VERSION ""

NS_ :

BS_:

BU_: AHLM ASBS CADM CBC DIAGNOST DPDM DTCM ECM EHPS ESC ESL ESM ETM EVCU2 GPF IC IRCM LTM OCM ORC PTS RF_HUB SCCM SGW TBM TCM

BO_ 1005 VehCfgBu2: 8 RF_HUB
 SG_ VC_BU_PwrIvtrTyp : 2|2@1+ (1,0) [0|0] ""  CBC,SGW
 SG_ VC_BU_MaseratiMd : 6|2@1+ (1,0) [0|0] ""  CBC,SGW
 SG_ VC_BU_FULL_SPARE : 14|1@1+ (1,0) [0|0] ""  CBC,SGW
 SG_ VC_BU_ECO_Indicator : 24|1@1+ (1,0) [0|0] ""  CBC,SGW
 SG_ VC_BU_EngPowerDrvMd_Prsnt : 28|1@1+ (1,0) [0|0] ""  CBC,SGW
 SG_ VC_BU_MaxLdPressFtTr : 40|8@1+ (1,0) [0|126] "psi"  CBC,SGW
 SG_ VC_BU_LgtLdPressRrTr : 48|8@1+ (1,0) [0|126] "psi"  CBC,SGW
 SG_ VC_BU_LgtLdPressFtTr : 56|8@1+ (1,0) [0|126] "psi"  CBC,SGW
 SG_ VC_BU_SecPrkPrsnt : 29|1@1+ (1,0) [0|0] ""  CBC,SGW
 SG_ VC_BU_ShftInd_Prsnt : 30|2@1+ (1,0) [0|0] ""  CBC,SGW
 SG_ VC_BU_DRVMD_Prsnt : 25|1@1+ (1,0) [0|0] ""  CBC,SGW
 SG_ VC_BU_MemoryDRVMD_Prsnt : 26|1@1+ (1,0) [0|0] ""  CBC,SGW
 SG_ VC_BU_ESCDrvMd_Prsnt : 27|1@1+ (1,0) [0|0] ""  CBC,SGW
 SG_ VC_BU_MaxLdPressRrTr : 32|8@1+ (1,0) [0|126] "psi"  CBC,SGW
 SG_ VC_BU_OffRoad : 15|1@1+ (1,0) [0|0] ""  CBC,SGW
 SG_ VC_BU_PADS_Prsnt : 8|1@1+ (1,0) [0|0] ""  CBC,SGW
 SG_ VC_BU_RainSnsPrsnt : 9|1@1+ (1,0) [0|0] ""  CBC,SGW
 SG_ VC_BU_SKIM_PRSNT : 10|1@1+ (1,0) [0|0] ""  CBC,SGW
 SG_ VC_BU_AC_Prsnt : 11|1@1+ (1,0) [0|0] ""  CBC,SGW
 SG_ VC_BU_CRUISE_PRSNT : 12|1@1+ (1,0) [0|0] ""  CBC,SGW
 SG_ VC_BU_FG_PRSNT : 13|1@1+ (1,0) [0|0] ""  CBC,SGW
 SG_ VC_BU_ThatchamPrsnt : 4|1@1+ (1,0) [0|0] ""  CBC,SGW
 SG_ VC_BU_RunFlatTirePrsnt : 5|1@1+ (1,0) [0|0] ""  CBC,SGW
 SG_ VC_BU_VehCfg2_Stat : 0|2@1+ (1,0) [0|0] ""  CBC,SGW
 SG_ VC_BU_SpecialPKG_IC : 16|8@1+ (1,0) [0|0] ""  CBC,SGW

BO_ 1006 VehCfgBu3: 8 RF_HUB
 SG_ VC_BU_AutoParkPrsnt : 61|1@1+ (1,0) [0|0] ""  CBC,SGW
 SG_ VC_BU_PE_Prsnt : 62|1@1+ (1,0) [0|0] ""  CBC,SGW
 SG_ VC_BU_KG_Prsnt : 63|1@1+ (1,0) [0|0] ""  CBC,SGW
 SG_ VC_BU_Prem_TPM : 58|1@1+ (1,0) [0|0] ""  CBC,SGW
 SG_ VC_BU_PDDL_PRSNT : 59|1@1+ (1,0) [0|0] ""  CBC,SGW
 SG_ VC_BU_CMS : 55|1@1+ (1,0) [0|0] ""  CBC,SGW
 SG_ VC_BU_FCW : 56|1@1+ (1,0) [0|0] ""  CBC,SGW
 SG_ VC_BU_SecLkPrsnt : 52|1@1+ (1,0) [0|0] ""  CBC,SGW
 SG_ VC_BU_VEH_BRAND : 44|4@1+ (1,0) [0|0] ""  CBC,SGW
 SG_ VC_BU_CMP_DISP : 48|1@1+ (1,0) [0|0] ""  CBC,SGW
 SG_ VC_BU_IntEC_MIRR : 49|1@1+ (1,0) [0|0] ""  CBC,SGW
 SG_ VC_BU_ESCL_Prsnt : 50|1@1+ (1,0) [0|0] ""  CBC,SGW
 SG_ VC_BU_DrAlrPrsnt : 28|1@1+ (1,0) [0|0] ""  CBC,SGW
 SG_ VC_BU_DualFuelSens : 29|1@1+ (1,0) [0|0] ""  CBC,SGW
 SG_ VC_BU_SRT_PRSNT : 30|1@1+ (1,0) [0|0] ""  CBC,SGW
 SG_ VC_BU_DSBL_CLK_DISP : 31|1@1+ (1,0) [0|0] ""  CBC,SGW
 SG_ VC_BU_ChassisType : 32|7@1+ (1,0) [0|126] ""  CBC,SGW
 SG_ VC_BU_TEMP_DISP : 39|1@1+ (1,0) [0|0] ""  CBC,SGW
 SG_ VC_BU_RKE_PRSNT : 6|1@1+ (1,0) [0|0] ""  CBC,SGW
 SG_ VC_BU_SunShade_Present : 7|1@1+ (1,0) [0|0] ""  CBC,SGW
 SG_ VC_BU_PWR_LFT_GT : 3|1@1+ (1,0) [0|0] ""  CBC,SGW
 SG_ VC_BU_PWR_RT_SLDR : 4|1@1+ (1,0) [0|0] ""  CBC,SGW
 SG_ VC_BU_VehCfg3_Stat : 0|2@1+ (1,0) [0|0] ""  CBC,SGW
 SG_ VC_BU_POLICE : 2|1@1+ (1,0) [0|0] ""  CBC,SGW
 SG_ VC_BU_PWR_LT_SLDR : 5|1@1+ (1,0) [0|0] ""  CBC,SGW
 SG_ VC_BU_WHL_BASE : 12|2@1+ (1,0) [0|0] ""  CBC,SGW
 SG_ VC_BU_AUTO_HL : 27|1@1+ (1,0) [0|0] ""  CBC,SGW
 SG_ VC_BU_HVAC_Config : 40|4@1+ (1,0) [0|0] ""  CBC,SGW
 SG_ VC_BU_HID_HL : 51|1@1+ (1,0) [0|0] ""  CBC,SGW
 SG_ VC_BU_Liftgate_Trunk : 53|2@1+ (1,0) [0|0] ""  CBC,SGW
 SG_ VC_BU_Base_TPM : 57|1@1+ (1,0) [0|0] ""  CBC,SGW
 SG_ VC_BU_SPORT_PRSNT : 60|1@1+ (1,0) [0|0] ""  CBC,SGW
 SG_ VC_BU_TcaseTyp : 8|4@1+ (1,0) [0|0] ""  CBC,SGW
 SG_ VC_BU_FOBIKsafeENBL : 14|1@1+ (1,0) [0|0] ""  CBC,SGW
 SG_ VC_BU_ELV_PRSNT : 15|1@1+ (1,0) [0|0] ""  CBC,SGW
 SG_ VC_BU_FUEL_CAP : 16|8@1+ (1,36) [36|290] "liters"  CBC,SGW
 SG_ VC_BU_WIN_EXPR_FEAT : 24|2@1+ (1,0) [0|0] ""  CBC,SGW
 SG_ VC_BU_ADJ_PDL_PRSNT : 26|1@1+ (1,0) [0|0] ""  CBC,SGW

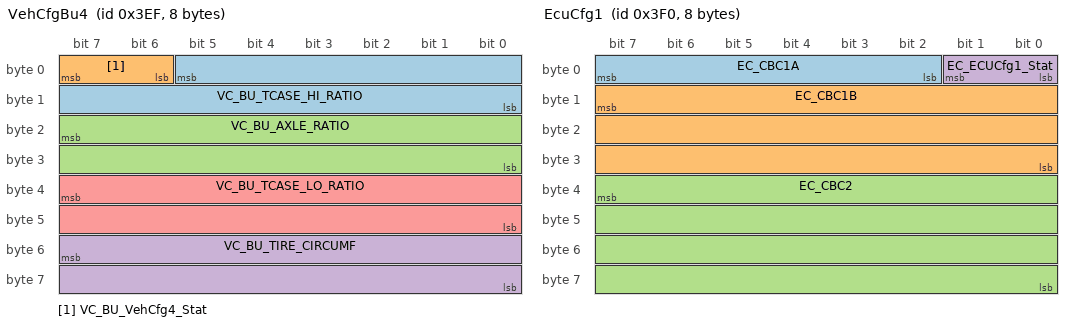
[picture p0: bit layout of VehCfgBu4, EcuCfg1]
BO_ 1007 VehCfgBu4: 8 RF_HUB
 SG_ VC_BU_TCASE_HI_RATIO : 5|14@0+ (0.001,0) [0|16.382] ""  CBC,SGW
 SG_ VC_BU_VehCfg4_Stat : 6|2@1+ (1,0) [0|0] ""  CBC,SGW
 SG_ VC_BU_AXLE_RATIO : 23|16@0+ (0.001,0) [0|65.534] ""  CBC,SGW
 SG_ VC_BU_TIRE_CIRCUMF : 55|16@0+ (1,0) [0|65534] "mm"  CBC,SGW
 SG_ VC_BU_TCASE_LO_RATIO : 39|16@0+ (0.001,0) [0|65.534] ""  CBC,SGW

BO_ 1008 EcuCfg1: 8 CBC
 SG_ EC_CBC1A : 2|6@1+ (1,0) [0|0] ""  RF_HUB,SGW
 SG_ EC_CBC1B : 15|24@0+ (1,0) [0|0] ""  RF_HUB,SGW
 SG_ EC_CBC2 : 39|32@0+ (1,0) [0|0] ""  RF_HUB,SGW
 SG_ EC_ECUCfg1_Stat : 0|2@1+ (1,0) [0|0] ""  RF_HUB,SGW

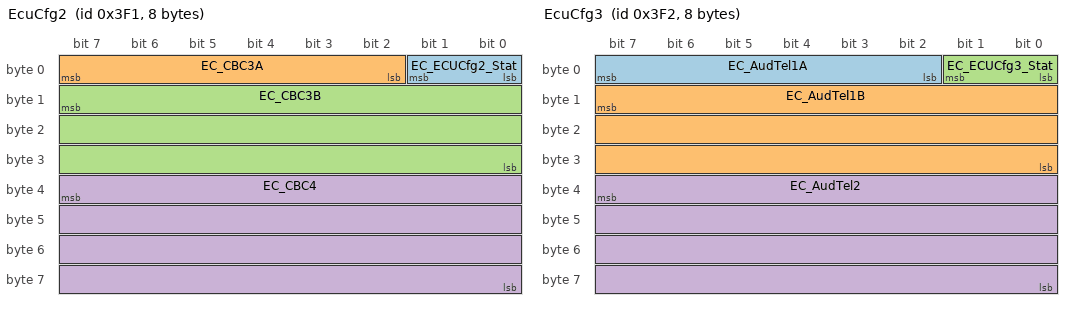
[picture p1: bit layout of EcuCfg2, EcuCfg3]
BO_ 1009 EcuCfg2: 8 CBC
 SG_ EC_ECUCfg2_Stat : 0|2@1+ (1,0) [0|0] ""  RF_HUB,SGW
 SG_ EC_CBC3A : 2|6@1+ (1,0) [0|0] ""  RF_HUB,SGW
 SG_ EC_CBC3B : 15|24@0+ (1,0) [0|0] ""  RF_HUB,SGW
 SG_ EC_CBC4 : 39|32@0+ (1,0) [0|0] ""  RF_HUB,SGW

BO_ 1010 EcuCfg3: 8 CBC
 SG_ EC_AudTel1A : 2|6@1+ (1,0) [0|0] ""  RF_HUB,SGW
 SG_ EC_AudTel1B : 15|24@0+ (1,0) [0|0] ""  RF_HUB,SGW
 SG_ EC_ECUCfg3_Stat : 0|2@1+ (1,0) [0|0] ""  RF_HUB,SGW
 SG_ EC_AudTel2 : 39|32@0+ (1,0) [0|0] ""  RF_HUB,SGW

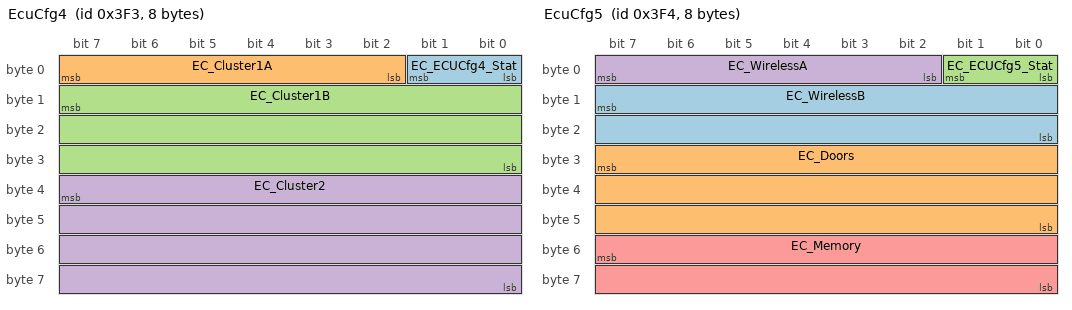
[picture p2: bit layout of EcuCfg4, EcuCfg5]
BO_ 1011 EcuCfg4: 8 CBC
 SG_ EC_ECUCfg4_Stat : 0|2@1+ (1,0) [0|0] ""  IC,RF_HUB,SGW
 SG_ EC_Cluster1A : 2|6@1+ (1,0) [0|0] ""  ETM,IC,RF_HUB,SGW
 SG_ EC_Cluster1B : 15|24@0+ (1,0) [0|0] ""  IC,RF_HUB,SGW
 SG_ EC_Cluster2 : 39|32@0+ (1,0) [0|0] ""  IC,RF_HUB,SGW

BO_ 1012 EcuCfg5: 8 CBC
 SG_ EC_WirelessB : 15|16@0+ (1,0) [0|0] ""  RF_HUB,SGW
 SG_ EC_Doors : 31|24@0+ (1,0) [0|0] ""  RF_HUB,SGW
 SG_ EC_ECUCfg5_Stat : 0|2@1+ (1,0) [0|0] ""  OCM,RF_HUB,SGW
 SG_ EC_WirelessA : 2|6@1+ (1,0) [0|0] ""  RF_HUB,SGW
 SG_ EC_Memory : 55|16@0+ (1,0) [0|0] ""  OCM,RF_HUB,SGW

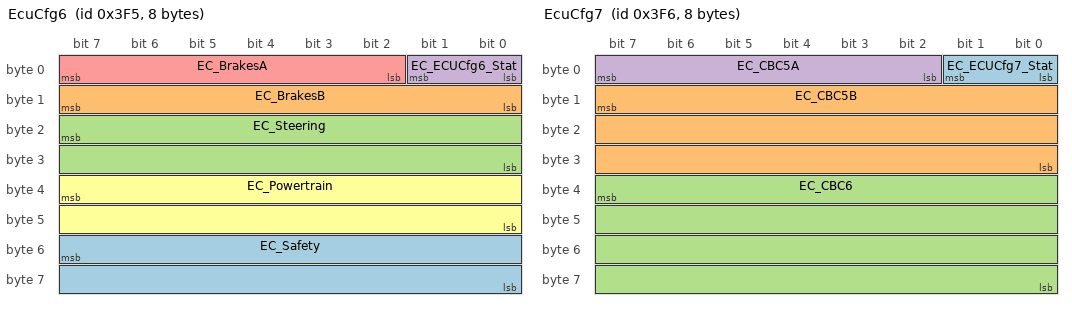
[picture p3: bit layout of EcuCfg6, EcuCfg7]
BO_ 1013 EcuCfg6: 8 CBC
 SG_ EC_Safety : 55|16@0+ (1,0) [0|0] ""  ORC,RF_HUB,SGW
 SG_ EC_BrakesB : 8|8@1+ (1,0) [0|0] ""  ESC,RF_HUB,SGW
 SG_ EC_Steering : 23|16@0+ (1,0) [0|0] ""  EHPS,ESC,RF_HUB,SGW
 SG_ EC_ECUCfg6_Stat : 0|2@1+ (1,0) [0|0] ""  ECM,EHPS,ESC,ORC,RF_HUB,SGW,TCM
 SG_ EC_BrakesA : 2|6@1+ (1,0) [0|0] ""  ESC,RF_HUB,SGW
 SG_ EC_Powertrain : 39|16@0+ (1,0) [0|0] ""  ECM,RF_HUB,SGW

BO_ 1014 EcuCfg7: 8 CBC
 SG_ EC_ECUCfg7_Stat : 0|2@1+ (1,0) [0|0] ""  RF_HUB,SGW
 SG_ EC_CBC5B : 15|24@0+ (1,0) [0|0] ""  RF_HUB,SGW
 SG_ EC_CBC6 : 39|32@0+ (1,0) [0|0] ""  RF_HUB,SGW
 SG_ EC_CBC5A : 2|6@1+ (1,0) [0|0] ""  RF_HUB,SGW

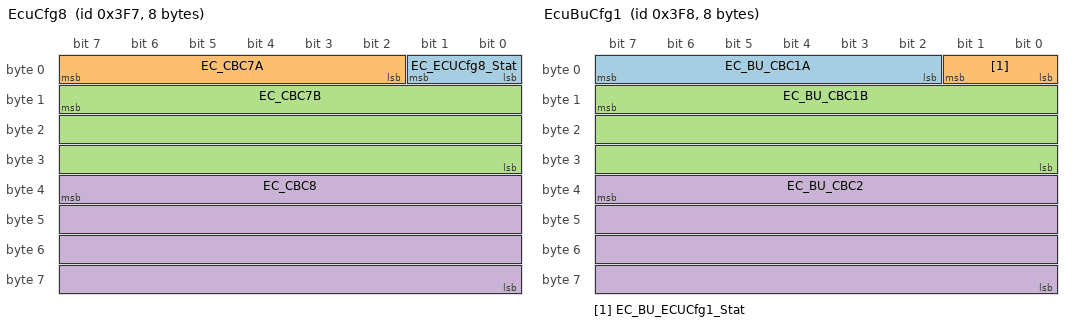
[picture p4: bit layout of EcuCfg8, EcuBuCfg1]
BO_ 1015 EcuCfg8: 8 CBC
 SG_ EC_ECUCfg8_Stat : 0|2@1+ (1,0) [0|0] ""  RF_HUB,SGW
 SG_ EC_CBC7A : 2|6@1+ (1,0) [0|0] ""  RF_HUB,SGW,TBM
 SG_ EC_CBC7B : 15|24@0+ (1,0) [0|0] ""  RF_HUB,SGW
 SG_ EC_CBC8 : 39|32@0+ (1,0) [0|0] ""  RF_HUB,SGW

BO_ 1016 EcuBuCfg1: 8 RF_HUB
 SG_ EC_BU_CBC1A : 2|6@1+ (1,0) [0|0] ""  CBC,SGW
 SG_ EC_BU_ECUCfg1_Stat : 0|2@1+ (1,0) [0|0] ""  CBC,SGW
 SG_ EC_BU_CBC1B : 15|24@0+ (1,0) [0|0] ""  CBC,SGW
 SG_ EC_BU_CBC2 : 39|32@0+ (1,0) [0|0] ""  CBC,SGW

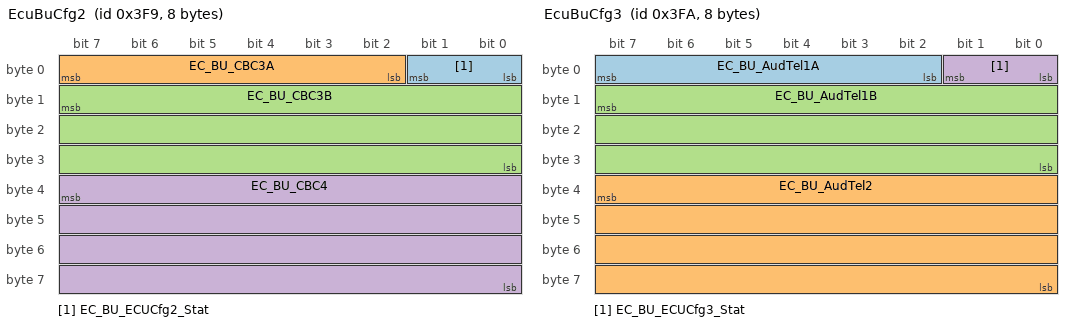
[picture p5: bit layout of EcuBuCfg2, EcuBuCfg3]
BO_ 1017 EcuBuCfg2: 8 RF_HUB
 SG_ EC_BU_ECUCfg2_Stat : 0|2@1+ (1,0) [0|0] ""  CBC,SGW
 SG_ EC_BU_CBC3A : 2|6@1+ (1,0) [0|0] ""  CBC,SGW
 SG_ EC_BU_CBC3B : 15|24@0+ (1,0) [0|0] ""  CBC,SGW
 SG_ EC_BU_CBC4 : 39|32@0+ (1,0) [0|0] ""  CBC,SGW

BO_ 1018 EcuBuCfg3: 8 RF_HUB
 SG_ EC_BU_AudTel1A : 2|6@1+ (1,0) [0|0] ""  CBC,SGW
 SG_ EC_BU_AudTel2 : 39|32@0+ (1,0) [0|0] ""  CBC,SGW
 SG_ EC_BU_AudTel1B : 15|24@0+ (1,0) [0|0] ""  CBC,SGW
 SG_ EC_BU_ECUCfg3_Stat : 0|2@1+ (1,0) [0|0] ""  CBC,SGW

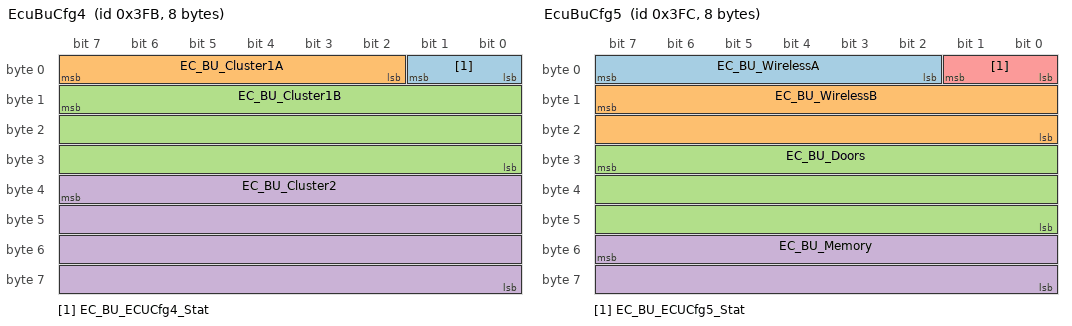
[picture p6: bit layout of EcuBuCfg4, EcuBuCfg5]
BO_ 1019 EcuBuCfg4: 8 RF_HUB
 SG_ EC_BU_ECUCfg4_Stat : 0|2@1+ (1,0) [0|0] ""  CBC,SGW
 SG_ EC_BU_Cluster1A : 2|6@1+ (1,0) [0|0] ""  CBC,SGW
 SG_ EC_BU_Cluster1B : 15|24@0+ (1,0) [0|0] ""  CBC,SGW
 SG_ EC_BU_Cluster2 : 39|32@0+ (1,0) [0|0] ""  CBC,SGW

BO_ 1020 EcuBuCfg5: 8 RF_HUB
 SG_ EC_BU_WirelessA : 2|6@1+ (1,0) [0|0] ""  CBC,SGW
 SG_ EC_BU_WirelessB : 15|16@0+ (1,0) [0|0] ""  CBC,SGW
 SG_ EC_BU_Doors : 31|24@0+ (1,0) [0|0] ""  CBC,SGW
 SG_ EC_BU_Memory : 55|16@0+ (1,0) [0|0] ""  CBC,SGW
 SG_ EC_BU_ECUCfg5_Stat : 0|2@1+ (1,0) [0|0] ""  CBC,SGW

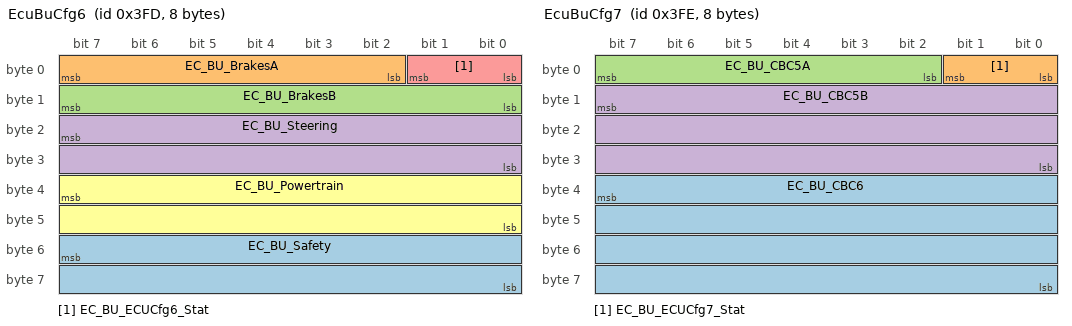
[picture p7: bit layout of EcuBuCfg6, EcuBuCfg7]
BO_ 1021 EcuBuCfg6: 8 RF_HUB
 SG_ EC_BU_Safety : 55|16@0+ (1,0) [0|0] ""  CBC,SGW
 SG_ EC_BU_BrakesA : 2|6@1+ (1,0) [0|0] ""  CBC,SGW
 SG_ EC_BU_BrakesB : 8|8@1+ (1,0) [0|0] ""  CBC,SGW
 SG_ EC_BU_Steering : 23|16@0+ (1,0) [0|0] ""  CBC,SGW
 SG_ EC_BU_ECUCfg6_Stat : 0|2@1+ (1,0) [0|0] ""  CBC,SGW
 SG_ EC_BU_Powertrain : 39|16@0+ (1,0) [0|0] ""  CBC,SGW

BO_ 1022 EcuBuCfg7: 8 RF_HUB
 SG_ EC_BU_CBC6 : 39|32@0+ (1,0) [0|0] ""  CBC,SGW
 SG_ EC_BU_ECUCfg7_Stat : 0|2@1+ (1,0) [0|0] ""  CBC,SGW
 SG_ EC_BU_CBC5A : 2|6@1+ (1,0) [0|0] ""  CBC,SGW
 SG_ EC_BU_CBC5B : 15|24@0+ (1,0) [0|0] ""  CBC,SGW

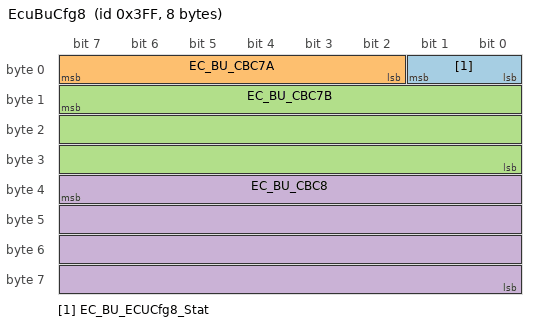
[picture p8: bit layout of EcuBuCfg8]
BO_ 1023 EcuBuCfg8: 8 RF_HUB
 SG_ EC_BU_ECUCfg8_Stat : 0|2@1+ (1,0) [0|0] ""  CBC,SGW
 SG_ EC_BU_CBC7A : 2|6@1+ (1,0) [0|0] ""  CBC,SGW
 SG_ EC_BU_CBC7B : 15|24@0+ (1,0) [0|0] ""  CBC,SGW
 SG_ EC_BU_CBC8 : 39|32@0+ (1,0) [0|0] ""  CBC,SGW

BO_ 1024 NM_RF_HUB: 8 RF_HUB
 SG_ NM_Mode : 0|8@1+ (1,0) [0|0] ""  CBC,EHPS,ESC,ESL,ESM,EVCU2,IC,RF_HUB,SCCM,SGW
 SG_ NM_Sleep_Ack : 22|1@1+ (1,0) [0|0] ""  CBC,EHPS,ESC,ESL,ESM,EVCU2,IC,RF_HUB,SCCM,SGW
 SG_ WakeupCnt m2 : 40|8@1+ (1,0) [0|254] ""  CBC,EHPS,ESC,ESL,ESM,EVCU2,IC,RF_HUB,SCCM,SGW
 SG_ Nw_Id : 56|8@1+ (1,0) [0|0] ""  CBC,EHPS,ESC,ESL,ESM,EVCU2,IC,RF_HUB,SCCM,SGW
 SG_ NM_Sleep_Ind : 23|1@1+ (1,0) [0|0] ""  CBC,EHPS,ESC,ESL,ESM,EVCU2,IC,RF_HUB,SCCM,SGW
 SG_ NM_Ud_Srv M : 24|8@1+ (1,0) [0|0] ""  CBC,EHPS,ESC,ESL,ESM,EVCU2,IC,RF_HUB,SCCM,SGW
 SG_ Awake_NwSt m15 : 32|1@1+ (1,0) [0|0] ""  CBC,EHPS,ESC,ESL,ESM,EVCU2,IC,RF_HUB,SCCM,SGW
 SG_ WakeupRsn_RF_HUB m2 : 32|8@1+ (1,0) [0|0] ""  CBC,EHPS,ESC,ESL,ESM,EVCU2,IC,RF_HUB,SCCM,SGW
 SG_ Awake_Diag_Actv m15 : 33|1@1+ (1,0) [0|0] ""  CBC,EHPS,ESC,ESL,ESM,EVCU2,IC,RF_HUB,SCCM,SGW
 SG_ NM_Successor : 8|8@1+ (1,0) [0|63] ""  CBC,EHPS,ESC,ESL,ESM,EVCU2,IC,RF_HUB,SCCM,SGW
 SG_ NM_Ud_Launch : 16|6@1+ (1,0) [0|0] ""  CBC,EHPS,ESC,ESL,ESM,EVCU2,IC,RF_HUB,SCCM,SGW

BO_ 1025 NM_CBC: 8 CBC
 SG_ NM_Ud_Srv M : 24|8@1+ (1,0) [0|0] ""  CBC,EHPS,ESC,ESL,ESM,EVCU2,IC,RF_HUB,SCCM,SGW
 SG_ WakeupRsn_CBC m2 : 32|8@1+ (1,0) [0|0] ""  CBC,EHPS,ESC,ESL,ESM,EVCU2,IC,RF_HUB,SCCM,SGW
 SG_ NM_Mode : 0|8@1+ (1,0) [0|0] ""  CBC,EHPS,ESC,ESL,ESM,EVCU2,IC,RF_HUB,SCCM,SGW
 SG_ NM_Successor : 8|8@1+ (1,0) [0|63] ""  CBC,EHPS,ESC,ESL,ESM,EVCU2,IC,RF_HUB,SCCM,SGW
 SG_ NM_Ud_Launch : 16|6@1+ (1,0) [0|0] ""  CBC,EHPS,ESC,ESL,ESM,EVCU2,IC,RF_HUB,SCCM,SGW
 SG_ NM_Sleep_Ack : 22|1@1+ (1,0) [0|0] ""  CBC,EHPS,ESC,ESL,ESM,EVCU2,IC,RF_HUB,SCCM,SGW
 SG_ NM_Sleep_Ind : 23|1@1+ (1,0) [0|0] ""  CBC,EHPS,ESC,ESL,ESM,EVCU2,IC,RF_HUB,SCCM,SGW
 SG_ Awake_NwSt m15 : 32|1@1+ (1,0) [0|0] ""  CBC,EHPS,ESC,ESL,ESM,EVCU2,IC,RF_HUB,SCCM,SGW
 SG_ Awake_Diag_Actv m15 : 33|1@1+ (1,0) [0|0] ""  CBC,EHPS,ESC,ESL,ESM,EVCU2,IC,RF_HUB,SCCM,SGW
 SG_ WakeupCnt m2 : 40|8@1+ (1,0) [0|254] ""  CBC,EHPS,ESC,ESL,ESM,EVCU2,IC,RF_HUB,SCCM,SGW
 SG_ Nw_Id : 56|8@1+ (1,0) [0|0] ""  CBC,EHPS,ESC,ESL,ESM,EVCU2,IC,RF_HUB,SCCM,SGW

BO_ 1026 NM_IC: 8 IC
 SG_ NM_Ud_Launch : 16|6@1+ (1,0) [0|0] ""  CBC,EHPS,ESC,ESL,ESM,EVCU2,IC,RF_HUB,SCCM,SGW
 SG_ WakeupRsn_IC m2 : 32|8@1+ (1,0) [0|0] ""  CBC,EHPS,ESC,ESL,ESM,EVCU2,IC,RF_HUB,SCCM,SGW
 SG_ NM_Sleep_Ack : 22|1@1+ (1,0) [0|0] ""  CBC,EHPS,ESC,ESL,ESM,EVCU2,IC,RF_HUB,SCCM,SGW
 SG_ NM_Sleep_Ind : 23|1@1+ (1,0) [0|0] ""  CBC,EHPS,ESC,ESL,ESM,EVCU2,IC,RF_HUB,SCCM,SGW
 SG_ NM_Ud_Srv M : 24|8@1+ (1,0) [0|0] ""  CBC,EHPS,ESC,ESL,ESM,EVCU2,IC,RF_HUB,SCCM,SGW
 SG_ Awake_NwSt m15 : 32|1@1+ (1,0) [0|0] ""  CBC,EHPS,ESC,ESL,ESM,EVCU2,IC,RF_HUB,SCCM,SGW
 SG_ Awake_Diag_Actv m15 : 33|1@1+ (1,0) [0|0] ""  CBC,EHPS,ESC,ESL,ESM,EVCU2,IC,RF_HUB,SCCM,SGW
 SG_ WakeupCnt m2 : 40|8@1+ (1,0) [0|254] ""  CBC,EHPS,ESC,ESL,ESM,EVCU2,IC,RF_HUB,SCCM,SGW
 SG_ Nw_Id : 56|8@1+ (1,0) [0|0] ""  CBC,EHPS,ESC,ESL,ESM,EVCU2,IC,RF_HUB,SCCM,SGW
 SG_ NM_Mode : 0|8@1+ (1,0) [0|0] ""  CBC,EHPS,ESC,ESL,ESM,EVCU2,IC,RF_HUB,SCCM,SGW
 SG_ NM_Successor : 8|8@1+ (1,0) [0|63] ""  CBC,EHPS,ESC,ESL,ESM,EVCU2,IC,RF_HUB,SCCM,SGW

BO_ 1031 NM_ESC: 8 ESC
 SG_ NM_Mode : 0|8@1+ (1,0) [0|0] ""  CBC,EHPS,ESC,ESL,ESM,EVCU2,IC,RF_HUB,SCCM,SGW
 SG_ NM_Sleep_Ind : 23|1@1+ (1,0) [0|0] ""  CBC,EHPS,ESC,ESL,ESM,EVCU2,IC,RF_HUB,SCCM,SGW
 SG_ Awake_NwSt m15 : 32|1@1+ (1,0) [0|0] ""  CBC,EHPS,ESC,ESL,ESM,EVCU2,IC,RF_HUB,SCCM,SGW
 SG_ WakeupCnt m2 : 40|8@1+ (1,0) [0|254] ""  CBC,EHPS,ESC,ESL,ESM,EVCU2,IC,RF_HUB,SCCM,SGW
 SG_ Nw_Id : 56|8@1+ (1,0) [0|0] ""  CBC,EHPS,ESC,ESL,ESM,EVCU2,IC,RF_HUB,SCCM,SGW
 SG_ NM_Ud_Srv M : 24|8@1+ (1,0) [0|0] ""  CBC,EHPS,ESC,ESL,ESM,EVCU2,IC,RF_HUB,SCCM,SGW
 SG_ WakeupRsn_ESC m2 : 32|8@1+ (1,0) [0|0] ""  CBC,EHPS,ESC,ESL,ESM,EVCU2,IC,RF_HUB,SCCM,SGW
 SG_ Awake_Diag_Actv m15 : 33|1@1+ (1,0) [0|0] ""  CBC,EHPS,ESC,ESL,ESM,EVCU2,IC,RF_HUB,SCCM,SGW
 SG_ Awake_Brake_Pedal_Pressed m15 : 34|1@1+ (1,0) [0|0] ""  CBC,EHPS,ESC,ESL,ESM,EVCU2,IC,RF_HUB,SCCM,SGW
 SG_ Awake_Vehicle_Speed m15 : 35|1@1+ (1,0) [0|0] ""  CBC,EHPS,ESC,ESL,ESM,EVCU2,IC,RF_HUB,SCCM,SGW
 SG_ Awake_EPB_Switch_Wakeup m15 : 36|1@1+ (1,0) [0|0] ""  CBC,EHPS,ESC,ESL,ESM,EVCU2,IC,RF_HUB,SCCM,SGW
 SG_ Awake_Hardwire_Ignition m15 : 37|1@1+ (1,0) [0|0] ""  CBC,EHPS,ESC,ESL,ESM,EVCU2,IC,RF_HUB,SCCM,SGW
 SG_ NM_Successor : 8|8@1+ (1,0) [0|63] ""  CBC,EHPS,ESC,ESL,ESM,EVCU2,IC,RF_HUB,SCCM,SGW
 SG_ NM_Ud_Launch : 16|6@1+ (1,0) [0|0] ""  CBC,EHPS,ESC,ESL,ESM,EVCU2,IC,RF_HUB,SCCM,SGW
 SG_ NM_Sleep_Ack : 22|1@1+ (1,0) [0|0] ""  CBC,EHPS,ESC,ESL,ESM,EVCU2,IC,RF_HUB,SCCM,SGW

BO_ 1032 NM_ESL: 8 ESL
 SG_ Awake_NwSt m15 : 32|1@1+ (1,0) [0|0] ""  CBC,EHPS,ESC,ESL,ESM,EVCU2,IC,RF_HUB,SCCM,SGW
 SG_ WakeupCnt m2 : 40|8@1+ (1,0) [0|254] ""  CBC,EHPS,ESC,ESL,ESM,EVCU2,IC,RF_HUB,SCCM,SGW
 SG_ Nw_Id : 56|8@1+ (1,0) [0|0] ""  CBC,EHPS,ESC,ESL,ESM,EVCU2,IC,RF_HUB,SCCM,SGW
 SG_ NM_Mode : 0|8@1+ (1,0) [0|0] ""  CBC,EHPS,ESC,ESL,ESM,EVCU2,IC,RF_HUB,SCCM,SGW
 SG_ NM_Successor : 8|8@1+ (1,0) [0|63] ""  CBC,EHPS,ESC,ESL,ESM,EVCU2,IC,RF_HUB,SCCM,SGW
 SG_ NM_Ud_Launch : 16|6@1+ (1,0) [0|0] ""  CBC,EHPS,ESC,ESL,ESM,EVCU2,IC,RF_HUB,SCCM,SGW
 SG_ NM_Sleep_Ack : 22|1@1+ (1,0) [0|0] ""  CBC,EHPS,ESC,ESL,ESM,EVCU2,IC,RF_HUB,SCCM,SGW
 SG_ NM_Sleep_Ind : 23|1@1+ (1,0) [0|0] ""  CBC,EHPS,ESC,ESL,ESM,EVCU2,IC,RF_HUB,SCCM,SGW
 SG_ NM_Ud_Srv M : 24|8@1+ (1,0) [0|0] ""  CBC,EHPS,ESC,ESL,ESM,EVCU2,IC,RF_HUB,SCCM,SGW
 SG_ WakeupRsn_ESL m2 : 32|8@1+ (1,0) [0|0] ""  CBC,EHPS,ESC,ESL,ESM,EVCU2,IC,RF_HUB,SCCM,SGW
 SG_ Awake_Diag_Actv m15 : 33|1@1+ (1,0) [0|0] ""  CBC,EHPS,ESC,ESL,ESM,EVCU2,IC,RF_HUB,SCCM,SGW
 SG_ Awake_Ign_RunStart m15 : 34|1@1+ (1,0) [0|0] ""  CBC,EHPS,ESC,ESL,ESM,EVCU2,IC,RF_HUB,SCCM,SGW
 SG_ Awake_Lock_Unlock m15 : 35|1@1+ (1,0) [0|0] ""  CBC,EHPS,ESC,ESL,ESM,EVCU2,IC,RF_HUB,SCCM,SGW

BO_ 1033 NM_SBWM: 8 ESM
 SG_ NM_Sleep_Ack : 22|1@1+ (1,0) [0|0] ""  CBC,EHPS,ESC,ESL,ESM,EVCU2,IC,RF_HUB,SCCM,SGW
 SG_ Awake_Ignition_On m15 : 34|1@1+ (1,0) [0|0] ""  CBC,EHPS,ESC,ESL,ESM,EVCU2,IC,RF_HUB,SCCM,SGW
 SG_ Nw_Id : 56|8@1+ (1,0) [0|0] ""  CBC,EHPS,ESC,ESL,ESM,EVCU2,IC,RF_HUB,SCCM,SGW
 SG_ NM_Sleep_Ind : 23|1@1+ (1,0) [0|0] ""  CBC,EHPS,ESC,ESL,ESM,EVCU2,IC,RF_HUB,SCCM,SGW
 SG_ NM_Ud_Srv M : 24|8@1+ (1,0) [0|0] ""  CBC,EHPS,ESC,ESL,ESM,EVCU2,IC,RF_HUB,SCCM,SGW
 SG_ Awake_NwSt m15 : 32|1@1+ (1,0) [0|0] ""  CBC,EHPS,ESC,ESL,ESM,EVCU2,IC,RF_HUB,SCCM,SGW
 SG_ WakeupRsn_SBWM m2 : 32|8@1+ (1,0) [0|0] ""  CBC,EHPS,ESC,ESL,ESM,EVCU2,IC,RF_HUB,SCCM,SGW
 SG_ Awake_Diag_Actv m15 : 33|1@1+ (1,0) [0|0] ""  CBC,EHPS,ESC,ESL,ESM,EVCU2,IC,RF_HUB,SCCM,SGW
 SG_ Awake_EEPROM m15 : 35|1@1+ (1,0) [0|0] ""  CBC,EHPS,ESC,ESL,ESM,EVCU2,IC,RF_HUB,SCCM,SGW
 SG_ Awake_URS m15 : 36|1@1+ (1,0) [0|0] ""  CBC,EHPS,ESC,ESL,ESM,EVCU2,IC,RF_HUB,SCCM,SGW
 SG_ WakeupCnt m2 : 40|8@1+ (1,0) [0|254] ""  CBC,EHPS,ESC,ESL,ESM,EVCU2,IC,RF_HUB,SCCM,SGW
 SG_ NM_Mode : 0|8@1+ (1,0) [0|0] ""  CBC,EHPS,ESC,ESL,ESM,EVCU2,IC,RF_HUB,SCCM,SGW
 SG_ NM_Successor : 8|8@1+ (1,0) [0|63] ""  CBC,EHPS,ESC,ESL,ESM,EVCU2,IC,RF_HUB,SCCM,SGW
 SG_ NM_Ud_Launch : 16|6@1+ (1,0) [0|0] ""  CBC,EHPS,ESC,ESL,ESM,EVCU2,IC,RF_HUB,SCCM,SGW

BO_ 1050 NM_EPS: 8 EHPS
 SG_ NM_Successor : 8|8@1+ (1,0) [0|63] ""  CBC,EHPS,ESC,ESL,ESM,EVCU2,IC,RF_HUB,SCCM,SGW
 SG_ NM_Sleep_Ack : 22|1@1+ (1,0) [0|0] ""  CBC,EHPS,ESC,ESL,ESM,EVCU2,IC,RF_HUB,SCCM,SGW
 SG_ Awake_NwSt m15 : 32|1@1+ (1,0) [0|0] ""  CBC,EHPS,ESC,ESL,ESM,EVCU2,IC,RF_HUB,SCCM,SGW
 SG_ Awake_VSS_high m15 : 35|1@1+ (1,0) [0|0] ""  CBC,EHPS,ESC,ESL,ESM,EVCU2,IC,RF_HUB,SCCM,SGW
 SG_ Awake_IgnHigh m15 : 37|1@1+ (1,0) [0|0] ""  CBC,EHPS,ESC,ESL,ESM,EVCU2,IC,RF_HUB,SCCM,SGW
 SG_ WakeupCnt m2 : 40|8@1+ (1,0) [0|254] ""  CBC,EHPS,ESC,ESL,ESM,EVCU2,IC,RF_HUB,SCCM,SGW
 SG_ Nw_Id : 56|8@1+ (1,0) [0|0] ""  CBC,EHPS,ESC,ESL,ESM,EVCU2,IC,RF_HUB,SCCM,SGW
 SG_ Awake_EngRPM_high m15 : 36|1@1+ (1,0) [0|0] ""  CBC,EHPS,ESC,ESL,ESM,EVCU2,IC,RF_HUB,SCCM,SGW
 SG_ NM_Sleep_Ind : 23|1@1+ (1,0) [0|0] ""  CBC,EHPS,ESC,ESL,ESM,EVCU2,IC,RF_HUB,SCCM,SGW
 SG_ NM_Ud_Srv M : 24|8@1+ (1,0) [0|0] ""  CBC,EHPS,ESC,ESL,ESM,EVCU2,IC,RF_HUB,SCCM,SGW
 SG_ NM_Ud_Launch : 16|6@1+ (1,0) [0|0] ""  CBC,EHPS,ESC,ESL,ESM,EVCU2,IC,RF_HUB,SCCM,SGW
 SG_ WakeupRsn_EPS m2 : 32|8@1+ (1,0) [0|0] ""  CBC,EHPS,ESC,ESL,ESM,EVCU2,IC,RF_HUB,SCCM,SGW
 SG_ Awake_Diag_Actv m15 : 33|1@1+ (1,0) [0|0] ""  CBC,EHPS,ESC,ESL,ESM,EVCU2,IC,RF_HUB,SCCM,SGW
 SG_ Awake_Rampout m15 : 34|1@1+ (1,0) [0|0] ""  CBC,EHPS,ESC,ESL,ESM,EVCU2,IC,RF_HUB,SCCM,SGW
 SG_ NM_Mode : 0|8@1+ (1,0) [0|0] ""  CBC,EHPS,ESC,ESL,ESM,EVCU2,IC,RF_HUB,SCCM,SGW

BO_ 1059 NM_SCCM: 8 SCCM
 SG_ NM_Sleep_Ind : 23|1@1+ (1,0) [0|0] ""  CBC,EHPS,ESC,ESL,ESM,EVCU2,IC,RF_HUB,SCCM,SGW
 SG_ WakeupRsn_SCCM m2 : 32|8@1+ (1,0) [0|0] ""  CBC,EHPS,ESC,ESL,ESM,EVCU2,IC,RF_HUB,SCCM,SGW
 SG_ Awake_StwSw_Actv m15 : 34|1@1+ (1,0) [0|0] ""  CBC,EHPS,ESC,ESL,ESM,EVCU2,IC,RF_HUB,SCCM,SGW
 SG_ Awake_EEPROM m15 : 36|1@1+ (1,0) [0|0] ""  CBC,EHPS,ESC,ESL,ESM,EVCU2,IC,RF_HUB,SCCM,SGW
 SG_ Awake_FTP_Psd m15 : 38|1@1+ (1,0) [0|0] ""  CBC,EHPS,ESC,ESL,ESM,EVCU2,IC,RF_HUB,SCCM,SGW
 SG_ Awake_tilt_tel_Psd m15 : 37|1@1+ (1,0) [0|0] ""  CBC,EHPS,ESC,ESL,ESM,EVCU2,IC,RF_HUB,SCCM,SGW
 SG_ Awake_HrnSwt_Actv m15 : 39|1@1+ (1,0) [0|0] ""  CBC,EHPS,ESC,ESL,ESM,EVCU2,IC,RF_HUB,SCCM,SGW
 SG_ WakeupCnt m2 : 40|8@1+ (1,0) [0|254] ""  CBC,EHPS,ESC,ESL,ESM,EVCU2,IC,RF_HUB,SCCM,SGW
 SG_ Nw_Id : 56|8@1+ (1,0) [0|0] ""  CBC,EHPS,ESC,ESL,ESM,EVCU2,IC,RF_HUB,SCCM,SGW
 SG_ Awake_Diag_Actv m15 : 33|1@1+ (1,0) [0|0] ""  CBC,EHPS,ESC,ESL,ESM,EVCU2,IC,RF_HUB,SCCM,SGW
 SG_ Awake_Ignition_On m15 : 35|1@1+ (1,0) [0|0] ""  CBC,EHPS,ESC,ESL,ESM,EVCU2,IC,RF_HUB,SCCM,SGW
 SG_ NM_Ud_Srv M : 24|8@1+ (1,0) [0|0] ""  CBC,EHPS,ESC,ESL,ESM,EVCU2,IC,RF_HUB,SCCM,SGW
 SG_ Awake_NwSt m15 : 32|1@1+ (1,0) [0|0] ""  CBC,EHPS,ESC,ESL,ESM,EVCU2,IC,RF_HUB,SCCM,SGW
 SG_ NM_Mode : 0|8@1+ (1,0) [0|0] ""  CBC,EHPS,ESC,ESL,ESM,EVCU2,IC,RF_HUB,SCCM,SGW
 SG_ NM_Successor : 8|8@1+ (1,0) [0|63] ""  CBC,EHPS,ESC,ESL,ESM,EVCU2,IC,RF_HUB,SCCM,SGW
 SG_ NM_Ud_Launch : 16|6@1+ (1,0) [0|0] ""  CBC,EHPS,ESC,ESL,ESM,EVCU2,IC,RF_HUB,SCCM,SGW
 SG_ NM_Sleep_Ack : 22|1@1+ (1,0) [0|0] ""  CBC,EHPS,ESC,ESL,ESM,EVCU2,IC,RF_HUB,SCCM,SGW

BO_ 1089 DG_RQ_GLOBAL_UDS: 8 DIAGNOST
 SG_ DG_RQ_GLOBAL_UDS : 7|64@0+ (1,0) [0|0] ""  AHLM,ASBS,CADM,CBC,DPDM,DTCM,ECM,EHPS,ESC,ESL,ESM,ETM,EVCU2,IC,IRCM,OCM,ORC,PTS,RF_HUB,SCCM,TBM,TCM

BO_TX_BU_ 1089 : DIAGNOST,SGW;
CM_ SG_ 1005 VC_BU_PwrIvtrTyp "Backup for power inverter type";
CM_ SG_ 1005 VC_BU_MaseratiMd "Backup for Maserati vehicle mode";
CM_ SG_ 1005 VC_BU_FULL_SPARE "Backup for Full size spare; present = [1]";
CM_ SG_ 1005 VC_BU_ECO_Indicator "Backup for ECO Indicator present on vehicle; True = [1]";
CM_ SG_ 1005 VC_BU_EngPowerDrvMd_Prsnt "Backup for ECM drive mode sub-feature configuration (1 = Present)";
CM_ SG_ 1005 VC_BU_MaxLdPressFtTr "Backup for Max Load Inflation Pressure Front Tire";
CM_ SG_ 1005 VC_BU_LgtLdPressRrTr "Backup for Light Load Inflation Pressure Rear Tire";
CM_ SG_ 1005 VC_BU_LgtLdPressFtTr "Backup for Light Load Inflation Pressure Front Tire";
CM_ SG_ 1005 VC_BU_SecPrkPrsnt "Backup for secure park feature present; present = [1]";
CM_ SG_ 1005 VC_BU_ShftInd_Prsnt "Backup for configuration for performance & gear shift indication";
CM_ SG_ 1005 VC_BU_DRVMD_Prsnt "Backup for drive mode feature configuration (1 = Present)";
CM_ SG_ 1005 VC_BU_MemoryDRVMD_Prsnt "Backup for memory drive mode sub-feature configuration (1 = Present)";
CM_ SG_ 1005 VC_BU_ESCDrvMd_Prsnt "Backup for ESC drive mode sub-feature configuration (1 = Present)";
CM_ SG_ 1005 VC_BU_MaxLdPressRrTr "Backup for Max Load Inflation Pressure Rear Tire";
CM_ SG_ 1005 VC_BU_OffRoad "Backup for Off road capable; present = [1]";
CM_ SG_ 1005 VC_BU_PADS_Prsnt "Backup for Pass. airbag disable switch present; present = [1]";
CM_ SG_ 1005 VC_BU_RainSnsPrsnt "Backup for Rain sensor present; present = [1]";
CM_ SG_ 1005 VC_BU_SKIM_PRSNT "Backup for SKIM system present; present = [1]";
CM_ SG_ 1005 VC_BU_AC_Prsnt "Backup for Vehicle is equipped with air conditioning; present = [1]";
CM_ SG_ 1005 VC_BU_CRUISE_PRSNT "Backup for Cruise feature is present; present = [1]";
CM_ SG_ 1005 VC_BU_FG_PRSNT "Backup for Flipper glass present; present = [1]";
CM_ SG_ 1005 VC_BU_ThatchamPrsnt "Backup for thatcham present; present = [1]";
CM_ SG_ 1005 VC_BU_RunFlatTirePrsnt "Backup for run flat tires present; present = [1]";
CM_ SG_ 1005 VC_BU_VehCfg2_Stat "Backup for Configuration messages status 2";
CM_ SG_ 1005 VC_BU_SpecialPKG_IC "Special sales code package";
CM_ SG_ 1006 VC_BU_AutoParkPrsnt "Backup for automatic transmission parking feature is present; present = [1]";
CM_ SG_ 1006 VC_BU_PE_Prsnt "Backup for passive entry is present; present = [1]";
CM_ SG_ 1006 VC_BU_KG_Prsnt "Backup for keyless go is present; present = [1]";
CM_ SG_ 1006 VC_BU_Prem_TPM "Backup for Premium TPM system present; present = [1]";
CM_ SG_ 1006 VC_BU_PDDL_PRSNT "backup for Paddle shift feature is present; present = [1]";
CM_ SG_ 1006 VC_BU_CMS "Backup for Collision Mitigation System present; present = [1]";
CM_ SG_ 1006 VC_BU_FCW "Backup for Forward Collision Warning present; present = [1]";
CM_ SG_ 1006 VC_BU_SecLkPrsnt "Backup for Secondary Lock Present; [1] = True";
CM_ SG_ 1006 VC_BU_VEH_BRAND "Backup for Vehicle brand type";
CM_ SG_ 1006 VC_BU_CMP_DISP "Backup for display compass heading present; present = [1]";
CM_ SG_ 1006 VC_BU_IntEC_MIRR "Backup for vehicle is equipped with an interior EC mirror; present = [1]";
CM_ SG_ 1006 VC_BU_ESCL_Prsnt "Backup for ESCL system present; enabled=[1], disabled=[0]";
CM_ SG_ 1006 VC_BU_DrAlrPrsnt "Backup for Door alert feature present; present = [1]";
CM_ SG_ 1006 VC_BU_DualFuelSens "Backup for Vehicle equipped with two fuel sending units; present = [1]";
CM_ SG_ 1006 VC_BU_SRT_PRSNT "Backup for Vehicle is an SRT; present = [1]";
CM_ SG_ 1006 VC_BU_DSBL_CLK_DISP "Backup of Disable display of radio clock; 1 = clock display disabled";
CM_ SG_ 1006 VC_BU_ChassisType "Backup for chassis type (including suspension, brakes, and tires)";
CM_ SG_ 1006 VC_BU_TEMP_DISP "Backup for display outside temperature present; present = [1]";
CM_ SG_ 1006 VC_BU_RKE_PRSNT "Backup for RKE system present; present = [1]";
CM_ SG_ 1006 VC_BU_SunShade_Present "Backup for Vehicle equipped w/SunShade (1=present)";
CM_ SG_ 1006 VC_BU_PWR_LFT_GT "Backup for Power lift gate present; present = [1]";
CM_ SG_ 1006 VC_BU_PWR_RT_SLDR "Backup for Power right sliding door present; present = [1]";
CM_ SG_ 1006 VC_BU_VehCfg3_Stat "Backup for Configuration messages status 3";
CM_ SG_ 1006 VC_BU_POLICE "Backup for Police lighting feature; present = [1]";
CM_ SG_ 1006 VC_BU_PWR_LT_SLDR "Backup for Power left sliding door present; present = [1]";
CM_ SG_ 1006 VC_BU_WHL_BASE "Backup for Wheel base";
CM_ SG_ 1006 VC_BU_AUTO_HL "Backup for Auto headlamp feature present; present = [1]";
CM_ SG_ 1006 VC_BU_HVAC_Config "Backup for HVAC Configuration";
CM_ SG_ 1006 VC_BU_HID_HL "Backup for High intensity discharge head lamps; present = [1]";
CM_ SG_ 1006 VC_BU_Liftgate_Trunk "Backup for Liftgate or trunk";
CM_ SG_ 1006 VC_BU_Base_TPM "Backup for Base TPM system present; present = [1]";
CM_ SG_ 1006 VC_BU_SPORT_PRSNT "Backup for Sport mode is present; present = [1]";
CM_ SG_ 1006 VC_BU_TcaseTyp "Backup for Tcase type";
CM_ SG_ 1006 VC_BU_FOBIKsafeENBL "Backup for FOBIK safe feature; present = [1]";
CM_ SG_ 1006 VC_BU_ELV_PRSNT "Backup for ELV system present; enabled=[1], disabled=[0]";
CM_ SG_ 1006 VC_BU_FUEL_CAP "Backup for Fuel capacity";
CM_ SG_ 1006 VC_BU_WIN_EXPR_FEAT "Backup for Window express feature configuration";
CM_ SG_ 1006 VC_BU_ADJ_PDL_PRSNT "Backup for Adjustable pedal system present (non-memory); present = [1]";
CM_ SG_ 1007 VC_BU_TCASE_HI_RATIO "Backup for Transfer case high ratio";
CM_ SG_ 1007 VC_BU_VehCfg4_Stat "Backup for Configuration messages status 4";
CM_ SG_ 1007 VC_BU_AXLE_RATIO "Backup for Axle ratio";
CM_ SG_ 1007 VC_BU_TIRE_CIRCUMF "Backup for Dynamic tire circumference (all or rear)";
CM_ SG_ 1007 VC_BU_TCASE_LO_RATIO "Backup for Transfer case low range reduction ratio";
CM_ SG_ 1008 EC_CBC1A "CBC ecu configuration 1A";
CM_ SG_ 1008 EC_CBC1B "CBC ecu configuration 1B";
CM_ SG_ 1008 EC_CBC2 "CBC ecu configuration 2";
CM_ SG_ 1008 EC_ECUCfg1_Stat "ECU Configuration messages status 1";
CM_ SG_ 1009 EC_ECUCfg2_Stat "ECU Configuration messages status 2";
CM_ SG_ 1009 EC_CBC3A "CBC ecu configuration 3A";
CM_ SG_ 1009 EC_CBC3B "CBC ecu configuration 3B";
CM_ SG_ 1009 EC_CBC4 "CBC ecu configuration 4";
CM_ SG_ 1010 EC_AudTel1A "Audio and telematics ecu configuration 1A";
CM_ SG_ 1010 EC_AudTel1B "Audio and telematics ecu configuration 1B";
CM_ SG_ 1010 EC_ECUCfg3_Stat "ECU Configuration messages status 3";
CM_ SG_ 1010 EC_AudTel2 "Audio and telematics ecu configuration 2";
CM_ SG_ 1011 EC_ECUCfg4_Stat "ECU Configuration messages status 4";
CM_ SG_ 1011 EC_Cluster1A "Instrument cluster ecu configuration 1A";
CM_ SG_ 1011 EC_Cluster1B "Instrument cluster ecu configuration 1B";
CM_ SG_ 1011 EC_Cluster2 "Instrument cluster ecu configuration 2";
CM_ SG_ 1012 EC_WirelessB "Wireless ecu configurationB";
CM_ SG_ 1012 EC_Doors "Doors ecu configuration";
CM_ SG_ 1012 EC_ECUCfg5_Stat "ECU Configuration messages status 5";
CM_ SG_ 1012 EC_WirelessA "Wireless ecu configurationA";
CM_ SG_ 1012 EC_Memory "Memory ecu configuration";
CM_ SG_ 1013 EC_Safety "Safety ecu configuration";
CM_ SG_ 1013 EC_BrakesB "Brake system ecu configurationB";
CM_ SG_ 1013 EC_Steering "Steering ecu configuration";
CM_ SG_ 1013 EC_ECUCfg6_Stat "ECU Configuration messages status 6";
CM_ SG_ 1013 EC_BrakesA "Brake system ecu configurationA";
CM_ SG_ 1013 EC_Powertrain "Powertrain ecu configuration";
CM_ SG_ 1014 EC_ECUCfg7_Stat "ECU Configuration messages status 7";
CM_ SG_ 1014 EC_CBC5B "CBC ecu configuration 5B";
CM_ SG_ 1014 EC_CBC6 "CBC ecu configuration 6";
CM_ SG_ 1014 EC_CBC5A "CBC ecu configuration 5A";
CM_ SG_ 1015 EC_ECUCfg8_Stat "ECU Configuration messages status 8";
CM_ SG_ 1015 EC_CBC7A "CBC ecu configuration 7A";
CM_ SG_ 1015 EC_CBC7B "CBC ecu configuration 7B";
CM_ SG_ 1015 EC_CBC8 "CBC ecu configuration 8";
CM_ SG_ 1016 EC_BU_CBC1A "Backup for CBC ecu configuration 1A";
CM_ SG_ 1016 EC_BU_ECUCfg1_Stat "Backup for ECU Configuration messages status 1";
CM_ SG_ 1016 EC_BU_CBC1B "Backup for CBC ecu configuration 1B";
CM_ SG_ 1016 EC_BU_CBC2 "Backup for CBC ecu configuration 2";
CM_ SG_ 1017 EC_BU_ECUCfg2_Stat "Backup for ECU Configuration messages status 2";
CM_ SG_ 1017 EC_BU_CBC3A "Backup for CBC ecu configuration 3A";
CM_ SG_ 1017 EC_BU_CBC3B "Backup for CBC ecu configuration 3B";
CM_ SG_ 1017 EC_BU_CBC4 "Backup for CBC ecu configuration 4";
CM_ SG_ 1018 EC_BU_AudTel1A "Backup for Audio and telematics ecu configuration 1A";
CM_ SG_ 1018 EC_BU_AudTel2 "Backup for Audio and telematics ecu configuration 2";
CM_ SG_ 1018 EC_BU_AudTel1B "Backup for Audio and telematics ecu configuration 1B";
CM_ SG_ 1018 EC_BU_ECUCfg3_Stat "Backup for ECU Configuration messages status 3";
CM_ SG_ 1019 EC_BU_ECUCfg4_Stat "Backup for ECU Configuration messages status 4";
CM_ SG_ 1019 EC_BU_Cluster1A "Backup for Instrument cluster ecu configuration 1A";
CM_ SG_ 1019 EC_BU_Cluster1B "Backup for Instrument cluster ecu configuration 1B";
CM_ SG_ 1019 EC_BU_Cluster2 "Backup for Instrument cluster ecu configuration 2";
CM_ SG_ 1020 EC_BU_WirelessA "Backup for Wireless ecu configurationA";
CM_ SG_ 1020 EC_BU_WirelessB "Backup for Wireless ecu configurationB";
CM_ SG_ 1020 EC_BU_Doors "Backup for Doors ecu configuration";
CM_ SG_ 1020 EC_BU_Memory "Backup for Memory ecu configuration";
CM_ SG_ 1020 EC_BU_ECUCfg5_Stat "Backup for ECU Configuration messages status 5";
CM_ SG_ 1021 EC_BU_Safety "Backup for Safety ecu configuration";
CM_ SG_ 1021 EC_BU_BrakesA "Backup for Brake system ecu configurationA";
CM_ SG_ 1021 EC_BU_BrakesB "Backup for Brake system ecu configurationB";
CM_ SG_ 1021 EC_BU_Steering "Backup for steering ecu configuration";
CM_ SG_ 1021 EC_BU_ECUCfg6_Stat "Backup for ECU Configuration messages status 6";
CM_ SG_ 1021 EC_BU_Powertrain "Backup for Powertrain ecu configuration";
CM_ SG_ 1022 EC_BU_CBC6 "Backup for CBC ecu configuration 6";
CM_ SG_ 1022 EC_BU_ECUCfg7_Stat "Backup for ECU Configuration messages status 7";
CM_ SG_ 1022 EC_BU_CBC5A "Backup for CBC ecu configuration 5A";
CM_ SG_ 1022 EC_BU_CBC5B "Backup for CBC ecu configuration 5B";
CM_ SG_ 1023 EC_BU_ECUCfg8_Stat "Backup for ECU Configuration messages status 8";
CM_ SG_ 1023 EC_BU_CBC7A "Backup for CBC ecu configuration 7A";
CM_ SG_ 1023 EC_BU_CBC7B "Backup for CBC ecu configuration 7B";
CM_ SG_ 1023 EC_BU_CBC8 "Backup for CBC ecu configuration 8";
CM_ SG_ 1024 NM_Mode "Network management mode";
CM_ SG_ 1024 NM_Sleep_Ack "Network management sleep acknowledge; True = [1]";
CM_ SG_ 1024 WakeupCnt "Counter for module wakeup states during network sleep";
CM_ SG_ 1024 Nw_Id "Network identification no.";
CM_ SG_ 1024 NM_Sleep_Ind "Network management sleep indication; True = [1]";
CM_ SG_ 1024 NM_Ud_Srv "Network management userdata service no.";
CM_ SG_ 1024 Awake_NwSt "Stay awake for network startup; True = [1]";
CM_ SG_ 1024 WakeupRsn_RF_HUB "Wakeup reason RF_HUB";
CM_ SG_ 1024 Awake_Diag_Actv "Stay awake for diagnostics active; True = [1]";
CM_ SG_ 1024 NM_Successor "Network management logical successor";
CM_ SG_ 1024 NM_Ud_Launch "Network management userdata launch type";
CM_ SG_ 1025 NM_Ud_Srv "Network management userdata service no.";
CM_ SG_ 1025 WakeupRsn_CBC "Wakeup reason CBC";
CM_ SG_ 1025 NM_Mode "Network management mode";
CM_ SG_ 1025 NM_Successor "Network management logical successor";
CM_ SG_ 1025 NM_Ud_Launch "Network management userdata launch type";
CM_ SG_ 1025 NM_Sleep_Ack "Network management sleep acknowledge; True = [1]";
CM_ SG_ 1025 NM_Sleep_Ind "Network management sleep indication; True = [1]";
CM_ SG_ 1025 Awake_NwSt "Stay awake for network startup; True = [1]";
CM_ SG_ 1025 Awake_Diag_Actv "Stay awake for diagnostics active; True = [1]";
CM_ SG_ 1025 WakeupCnt "Counter for module wakeup states during network sleep";
CM_ SG_ 1025 Nw_Id "Network identification no.";
CM_ SG_ 1026 NM_Ud_Launch "Network management userdata launch type";
CM_ SG_ 1026 WakeupRsn_IC "Wakeup reason IC";
CM_ SG_ 1026 NM_Sleep_Ack "Network management sleep acknowledge; True = [1]";
CM_ SG_ 1026 NM_Sleep_Ind "Network management sleep indication; True = [1]";
CM_ SG_ 1026 NM_Ud_Srv "Network management userdata service no.";
CM_ SG_ 1026 Awake_NwSt "Stay awake for network startup; True = [1]";
CM_ SG_ 1026 Awake_Diag_Actv "Stay awake for diagnostics active; True = [1]";
CM_ SG_ 1026 WakeupCnt "Counter for module wakeup states during network sleep";
CM_ SG_ 1026 Nw_Id "Network identification no.";
CM_ SG_ 1026 NM_Mode "Network management mode";
CM_ SG_ 1026 NM_Successor "Network management logical successor";
CM_ SG_ 1031 NM_Mode "Network management mode";
CM_ SG_ 1031 NM_Sleep_Ind "Network management sleep indication; True = [1]";
CM_ SG_ 1031 Awake_NwSt "Stay awake for network startup; True = [1]";
CM_ SG_ 1031 WakeupCnt "Counter for module wakeup states during network sleep";
CM_ SG_ 1031 Nw_Id "Network identification no.";
CM_ SG_ 1031 NM_Ud_Srv "Network management userdata service no.";
CM_ SG_ 1031 WakeupRsn_ESC "Wakeup reason ESC";
CM_ SG_ 1031 Awake_Diag_Actv "Stay awake for diagnostics active; True = [1]";
CM_ SG_ 1031 Awake_Brake_Pedal_Pressed "Stay awake for brake pedal pressed; True = [1]";
CM_ SG_ 1031 Awake_Vehicle_Speed "Stay awake for vehicle speed; True = [1]";
CM_ SG_ 1031 Awake_EPB_Switch_Wakeup "Stay awake for EPB switch actuation; True = [1]";
CM_ SG_ 1031 Awake_Hardwire_Ignition "Stay awake for ignition on; True = [1]";
CM_ SG_ 1031 NM_Successor "Network management logical successor";
CM_ SG_ 1031 NM_Ud_Launch "Network management userdata launch type";
CM_ SG_ 1031 NM_Sleep_Ack "Network management sleep acknowledge; True = [1]";
CM_ SG_ 1032 Awake_NwSt "Stay awake for network startup; True = [1]";
CM_ SG_ 1032 WakeupCnt "Counter for module wakeup states during network sleep";
CM_ SG_ 1032 Nw_Id "Network identification no.";
CM_ SG_ 1032 NM_Mode "Network management mode";
CM_ SG_ 1032 NM_Successor "Network management logical successor";
CM_ SG_ 1032 NM_Ud_Launch "Network management userdata launch type";
CM_ SG_ 1032 NM_Sleep_Ack "Network management sleep acknowledge; True = [1]";
CM_ SG_ 1032 NM_Sleep_Ind "Network management sleep indication; True = [1]";
CM_ SG_ 1032 NM_Ud_Srv "Network management userdata service no.";
CM_ SG_ 1032 WakeupRsn_ESL "Wakeup reason ESL";
CM_ SG_ 1032 Awake_Diag_Actv "Stay awake for diagnostics active; True = [1]";
CM_ SG_ 1032 Awake_Ign_RunStart "Stay awake for the ignition is either Run or start; True = [1]";
CM_ SG_ 1032 Awake_Lock_Unlock "ESL is performing lock/unlock operation; True = [1]";
CM_ SG_ 1033 NM_Sleep_Ack "Network management sleep acknowledge; True = [1]";
CM_ SG_ 1033 Awake_Ignition_On "Stay awake for ignition on; True = [1]";
CM_ SG_ 1033 Nw_Id "Network identification no.";
CM_ SG_ 1033 NM_Sleep_Ind "Network management sleep indication; True = [1]";
CM_ SG_ 1033 NM_Ud_Srv "Network management userdata service no.";
CM_ SG_ 1033 Awake_NwSt "Stay awake for network startup; True = [1]";
CM_ SG_ 1033 WakeupRsn_SBWM "Wakeup reason SBWM";
CM_ SG_ 1033 Awake_Diag_Actv "Stay awake for diagnostics active; True = [1]";
CM_ SG_ 1033 Awake_EEPROM "Stay awake for EEPROM write access; True = [1]";
CM_ SG_ 1033 Awake_URS "Stay awake for 'Unlock Run Start' hardwired input; True = [1]";
CM_ SG_ 1033 WakeupCnt "Counter for module wakeup states during network sleep";
CM_ SG_ 1033 NM_Mode "Network management mode";
CM_ SG_ 1033 NM_Successor "Network management logical successor";
CM_ SG_ 1033 NM_Ud_Launch "Network management userdata launch type";
CM_ SG_ 1050 NM_Successor "Network management logical successor";
CM_ SG_ 1050 NM_Sleep_Ack "Network management sleep acknowledge; True = [1]";
CM_ SG_ 1050 Awake_NwSt "Stay awake for network startup; True = [1]";
CM_ SG_ 1050 Awake_VSS_high "Stay awake - assist active due to vehicle speed high; True = 1";
CM_ SG_ 1050 Awake_IgnHigh "Stay awake - ignition high; True = 1";
CM_ SG_ 1050 WakeupCnt "Counter for module wakeup states during network sleep";
CM_ SG_ 1050 Nw_Id "Network identification no.";
CM_ SG_ 1050 Awake_EngRPM_high "Stay awake - assist active due to engine RPM high; True = 1";
CM_ SG_ 1050 NM_Sleep_Ind "Network management sleep indication; True = [1]";
CM_ SG_ 1050 NM_Ud_Srv "Network management userdata service no.";
CM_ SG_ 1050 NM_Ud_Launch "Network management userdata launch type";
CM_ SG_ 1050 WakeupRsn_EPS "Wakeup reason EPS";
CM_ SG_ 1050 Awake_Diag_Actv "Stay awake for diagnostics active; True = [1]";
CM_ SG_ 1050 Awake_Rampout "Stay awake - ramping assist off; True = 1";
CM_ SG_ 1050 NM_Mode "Network management mode";
CM_ SG_ 1059 NM_Sleep_Ind "Network management sleep indication; True = [1]";
CM_ SG_ 1059 WakeupRsn_SCCM "Wakeup reason SCCM";
CM_ SG_ 1059 Awake_StwSw_Actv "Stay awake for steering wheel switches active; True = [1]";
CM_ SG_ 1059 Awake_EEPROM "Stay awake for EEPROM write access; True = [1]";
CM_ SG_ 1059 Awake_FTP_Psd "Stay awake for flash to pass lever actuated; True = [1]";
CM_ SG_ 1059 Awake_tilt_tel_Psd "Stay awake for tilt/telescope switch actuated; True = [1]";
CM_ SG_ 1059 Awake_HrnSwt_Actv "Stay awake for  horn switch active; True = [1]";
CM_ SG_ 1059 WakeupCnt "Counter for module wakeup states during network sleep";
CM_ SG_ 1059 Nw_Id "Network identification no.";
CM_ SG_ 1059 Awake_Diag_Actv "Stay awake for diagnostics active; True = [1]";
CM_ SG_ 1059 Awake_Ignition_On "Stay awake for ignition on; True = [1]";
CM_ SG_ 1059 NM_Ud_Srv "Network management userdata service no.";
CM_ SG_ 1059 Awake_NwSt "Stay awake for network startup; True = [1]";
CM_ SG_ 1059 NM_Mode "Network management mode";
CM_ SG_ 1059 NM_Successor "Network management logical successor";
CM_ SG_ 1059 NM_Ud_Launch "Network management userdata launch type";
CM_ SG_ 1059 NM_Sleep_Ack "Network management sleep acknowledge; True = [1]";
CM_ SG_ 1089 DG_RQ_GLOBAL_UDS "Diagnostic-Request";
BA_DEF_ BO_  "App-Botschaft" ENUM  "nein","ja";
BA_DEF_ BO_  "CanMsgMinLen" INT 0 8;
BA_DEF_ BO_  "DiagRequest" ENUM  "nein","ja";
BA_DEF_ BO_  "DiagResponse" ENUM  "nein","ja";
BA_DEF_ BO_  "DiagState" ENUM  "nein","ja";
BA_DEF_ BO_  "GenMsgCycleTime" INT 0 65535;
BA_DEF_ BO_  "GenMsgCycleTimeActive" INT 0 65535;
BA_DEF_ BO_  "GenMsgDelayTime" INT 0 65535;
BA_DEF_ BO_  "GenMsgNrOfRepetitions" INT 0 65535;
BA_DEF_ BO_  "GenMsgSendType" ENUM  "cyclicX","spontanX","cyclicIfActiveX","spontanWithDelay","cyclicAndSpontanX","cyclicAndSpontanWithDelay","spontanWithRepitition","cyclicIfActiveAndSpontanWD","cyclicIfActiveFast","cyclicWithRepeatOnDemand","none";
BA_DEF_ BO_  "GenMsgStartDelayTime" INT 0 65535;
BA_DEF_ BO_  "GenMsgStartValue" STRING ;
BA_DEF_ BO_  "NWM-Botschaft" ENUM  "nein","ja";
BA_DEF_ BO_  "TpTxIndex" INT 0 99;
BA_DEF_ SG_  "FlexKomComment" STRING ;
BA_DEF_ SG_  "FlexKomIsMotorola" ENUM  "nein","ja";
BA_DEF_ SG_  "FlexKomSID" INT 0 2147483647;
BA_DEF_ SG_  "FlexKomSigLaenge" INT 0 64;
BA_DEF_ SG_  "FlexKomSigName" STRING ;
BA_DEF_ SG_  "FlexKomSigStartPos" INT 0 63;
BA_DEF_ SG_  "FlexKomSigStartValue" STRING ;
BA_DEF_ SG_  "GenSigCycleTime" INT 0 65535;
BA_DEF_ SG_  "GenSigCycleTimeActive" INT 0 65535;
BA_DEF_ SG_  "GenSigSendType" ENUM  "cyclicX","spontanX","cyclicIfActiveX","spontanWithDelay","cyclicAndSpontanX","cyclicAndSpontanWithDelay","spontanWithRepitition","cyclicIfActiveAndSpontanWD","cyclicIfActiveFast","cyclicWithRepeatOnDemand","none";
BA_DEF_ SG_  "GenSigSNA" STRING ;
BA_DEF_ SG_  "GenSigStartValue" HEX 0 2147483648;
BA_DEF_ SG_  "GenSigTimeout_AHLM" INT 0 65535;
BA_DEF_ SG_  "GenSigTimeout_ASBS" INT 0 65535;
BA_DEF_ SG_  "GenSigTimeout_CBC" INT 0 65535;
BA_DEF_ SG_  "GenSigTimeout_DPDM" INT 0 65535;
BA_DEF_ SG_  "GenSigTimeout_DTCM" INT 0 65535;
BA_DEF_ SG_  "GenSigTimeout_EHPS" INT 0 65535;
BA_DEF_ SG_  "GenSigTimeout_ESC" INT 0 65535;
BA_DEF_ SG_  "GenSigTimeout_ESL" INT 0 65535;
BA_DEF_ SG_  "GenSigTimeout_ESM" INT 0 65535;
BA_DEF_ SG_  "GenSigTimeout_ETM" INT 0 65535;
BA_DEF_ SG_  "GenSigTimeout_IC" INT 0 65535;
BA_DEF_ SG_  "GenSigTimeout_OCM" INT 0 65535;
BA_DEF_ SG_  "GenSigTimeout_ORC" INT 0 65535;
BA_DEF_ SG_  "GenSigTimeout_PTS" INT 0 65535;
BA_DEF_ SG_  "GenSigTimeout_RF_HUB" INT 0 65535;
BA_DEF_ SG_  "GenSigTimeout_SCCM" INT 0 65535;
BA_DEF_ SG_  "GenSigTimeout_TBM" INT 0 65535;
BA_DEF_ SG_  "GenSigTimeout_TCM" INT 0 65535;
BA_DEF_ SG_  "GenSigTimeout_TPM" INT 0 65535;
BA_DEF_ SG_  "RID" STRING ;
BA_DEF_ SG_  "SystemSignalLongSymbol" STRING ;
BA_DEF_DEF_  "App-Botschaft" "nein";
BA_DEF_DEF_  "CanMsgMinLen" 0;
BA_DEF_DEF_  "DiagRequest" "nein";
BA_DEF_DEF_  "DiagResponse" "nein";
BA_DEF_DEF_  "DiagState" "nein";
BA_DEF_DEF_  "GenMsgCycleTime" 0;
BA_DEF_DEF_  "GenMsgCycleTimeActive" 0;
BA_DEF_DEF_  "GenMsgDelayTime" 0;
BA_DEF_DEF_  "GenMsgNrOfRepetitions" 0;
BA_DEF_DEF_  "GenMsgSendType" "cyclicX";
BA_DEF_DEF_  "GenMsgStartDelayTime" 0;
BA_DEF_DEF_  "GenMsgStartValue" "";
BA_DEF_DEF_  "NWM-Botschaft" "nein";
BA_DEF_DEF_  "TpTxIndex" 0;
BA_DEF_DEF_  "FlexKomComment" "";
BA_DEF_DEF_  "FlexKomIsMotorola" "nein";
BA_DEF_DEF_  "FlexKomSID" 0;
BA_DEF_DEF_  "FlexKomSigLaenge" 0;
BA_DEF_DEF_  "FlexKomSigName" "";
BA_DEF_DEF_  "FlexKomSigStartPos" 0;
BA_DEF_DEF_  "FlexKomSigStartValue" "";
BA_DEF_DEF_  "GenSigCycleTime" 0;
BA_DEF_DEF_  "GenSigCycleTimeActive" 0;
BA_DEF_DEF_  "GenSigSendType" "cyclicX";
BA_DEF_DEF_  "GenSigSNA" "";
BA_DEF_DEF_  "GenSigStartValue" 0;
BA_DEF_DEF_  "GenSigTimeout_AHLM" 0;
BA_DEF_DEF_  "GenSigTimeout_ASBS" 0;
BA_DEF_DEF_  "GenSigTimeout_CBC" 0;
BA_DEF_DEF_  "GenSigTimeout_DPDM" 0;
BA_DEF_DEF_  "GenSigTimeout_DTCM" 0;
BA_DEF_DEF_  "GenSigTimeout_EHPS" 0;
BA_DEF_DEF_  "GenSigTimeout_ESC" 0;
BA_DEF_DEF_  "GenSigTimeout_ESL" 0;
BA_DEF_DEF_  "GenSigTimeout_ESM" 0;
BA_DEF_DEF_  "GenSigTimeout_ETM" 0;
BA_DEF_DEF_  "GenSigTimeout_IC" 0;
BA_DEF_DEF_  "GenSigTimeout_OCM" 0;
BA_DEF_DEF_  "GenSigTimeout_ORC" 0;
BA_DEF_DEF_  "GenSigTimeout_PTS" 0;
BA_DEF_DEF_  "GenSigTimeout_RF_HUB" 0;
BA_DEF_DEF_  "GenSigTimeout_SCCM" 0;
BA_DEF_DEF_  "GenSigTimeout_TBM" 0;
BA_DEF_DEF_  "GenSigTimeout_TCM" 0;
BA_DEF_DEF_  "GenSigTimeout_TPM" 0;
BA_DEF_DEF_  "RID" "";
BA_DEF_DEF_  "SystemSignalLongSymbol" "";
BA_ "GenMsgStartValue" BO_ 1005 "0300FF00FFFFFFFFh";
BA_ "GenMsgSendType" BO_ 1005 1;
BA_ "GenMsgNrOfRepetitions" BO_ 1005 2;
BA_ "GenMsgDelayTime" BO_ 1005 20;
BA_ "GenMsgStartValue" BO_ 1006 "0370FF037FFF0000h";
BA_ "GenMsgSendType" BO_ 1006 1;
BA_ "GenMsgNrOfRepetitions" BO_ 1006 2;
BA_ "GenMsgDelayTime" BO_ 1006 20;
BA_ "GenMsgStartValue" BO_ 1007 "FFFFFFFFFFFFFFFFh";
BA_ "GenMsgSendType" BO_ 1007 1;
BA_ "GenMsgNrOfRepetitions" BO_ 1007 2;
BA_ "GenMsgDelayTime" BO_ 1007 20;
BA_ "GenMsgStartValue" BO_ 1008 "0300000000000000h";
BA_ "GenMsgStartDelayTime" BO_ 1008 140;
BA_ "GenMsgNrOfRepetitions" BO_ 1008 2;
BA_ "GenMsgDelayTime" BO_ 1008 20;
BA_ "GenMsgCycleTime" BO_ 1008 2000;
BA_ "GenMsgStartValue" BO_ 1009 "0300000000000000h";
BA_ "GenMsgStartDelayTime" BO_ 1009 150;
BA_ "GenMsgNrOfRepetitions" BO_ 1009 2;
BA_ "GenMsgDelayTime" BO_ 1009 20;
BA_ "GenMsgCycleTime" BO_ 1009 2000;
BA_ "GenMsgStartValue" BO_ 1010 "0300000000000000h";
BA_ "GenMsgStartDelayTime" BO_ 1010 30;
BA_ "GenMsgSendType" BO_ 1010 5;
BA_ "GenMsgNrOfRepetitions" BO_ 1010 2;
BA_ "GenMsgDelayTime" BO_ 1010 20;
BA_ "GenMsgCycleTime" BO_ 1010 2000;
BA_ "GenMsgStartValue" BO_ 1011 "0300000000000000h";
BA_ "GenMsgStartDelayTime" BO_ 1011 40;
BA_ "GenMsgSendType" BO_ 1011 5;
BA_ "GenMsgNrOfRepetitions" BO_ 1011 2;
BA_ "GenMsgDelayTime" BO_ 1011 20;
BA_ "GenMsgCycleTime" BO_ 1011 2000;
BA_ "GenMsgStartValue" BO_ 1012 "0300000000000000h";
BA_ "GenMsgStartDelayTime" BO_ 1012 50;
BA_ "GenMsgSendType" BO_ 1012 5;
BA_ "GenMsgNrOfRepetitions" BO_ 1012 2;
BA_ "GenMsgDelayTime" BO_ 1012 20;
BA_ "GenMsgCycleTime" BO_ 1012 2000;
BA_ "GenMsgStartValue" BO_ 1013 "0300000000000000h";
BA_ "GenMsgStartDelayTime" BO_ 1013 60;
BA_ "GenMsgSendType" BO_ 1013 5;
BA_ "GenMsgNrOfRepetitions" BO_ 1013 2;
BA_ "GenMsgDelayTime" BO_ 1013 20;
BA_ "GenMsgCycleTime" BO_ 1013 2000;
BA_ "GenMsgStartValue" BO_ 1014 "0300000000000000h";
BA_ "GenMsgStartDelayTime" BO_ 1014 150;
BA_ "GenMsgNrOfRepetitions" BO_ 1014 2;
BA_ "GenMsgDelayTime" BO_ 1014 20;
BA_ "GenMsgCycleTime" BO_ 1014 2000;
BA_ "GenMsgStartValue" BO_ 1015 "0300000000000000h";
BA_ "GenMsgStartDelayTime" BO_ 1015 80;
BA_ "GenMsgNrOfRepetitions" BO_ 1015 2;
BA_ "GenMsgDelayTime" BO_ 1015 20;
BA_ "GenMsgCycleTime" BO_ 1015 2000;
BA_ "GenMsgStartValue" BO_ 1016 "0300000000000000h";
BA_ "GenMsgSendType" BO_ 1016 1;
BA_ "GenMsgNrOfRepetitions" BO_ 1016 2;
BA_ "GenMsgDelayTime" BO_ 1016 20;
BA_ "GenMsgStartValue" BO_ 1017 "0300000000000000h";
BA_ "GenMsgSendType" BO_ 1017 1;
BA_ "GenMsgNrOfRepetitions" BO_ 1017 2;
BA_ "GenMsgDelayTime" BO_ 1017 20;
BA_ "GenMsgStartValue" BO_ 1018 "0300000000000000h";
BA_ "GenMsgSendType" BO_ 1018 1;
BA_ "GenMsgNrOfRepetitions" BO_ 1018 2;
BA_ "GenMsgDelayTime" BO_ 1018 20;
BA_ "GenMsgStartValue" BO_ 1019 "0300000000000000h";
BA_ "GenMsgSendType" BO_ 1019 1;
BA_ "GenMsgNrOfRepetitions" BO_ 1019 2;
BA_ "GenMsgDelayTime" BO_ 1019 20;
BA_ "GenMsgStartValue" BO_ 1020 "0300000000000000h";
BA_ "GenMsgSendType" BO_ 1020 1;
BA_ "GenMsgNrOfRepetitions" BO_ 1020 2;
BA_ "GenMsgDelayTime" BO_ 1020 20;
BA_ "GenMsgStartValue" BO_ 1021 "0300000000000000h";
BA_ "GenMsgSendType" BO_ 1021 1;
BA_ "GenMsgNrOfRepetitions" BO_ 1021 2;
BA_ "GenMsgDelayTime" BO_ 1021 20;
BA_ "GenMsgStartValue" BO_ 1022 "0300000000000000h";
BA_ "GenMsgSendType" BO_ 1022 1;
BA_ "GenMsgNrOfRepetitions" BO_ 1022 2;
BA_ "GenMsgDelayTime" BO_ 1022 20;
BA_ "GenMsgStartValue" BO_ 1023 "0300000000000000h";
BA_ "GenMsgSendType" BO_ 1023 1;
BA_ "GenMsgNrOfRepetitions" BO_ 1023 2;
BA_ "GenMsgDelayTime" BO_ 1023 20;
BA_ "NWM-Botschaft" BO_ 1024 1;
BA_ "GenMsgStartValue" BO_ 1024 "FFFFFFFF000000FFh";
BA_ "GenMsgSendType" BO_ 1024 1;
BA_ "GenMsgNrOfRepetitions" BO_ 1024 2;
BA_ "GenMsgDelayTime" BO_ 1024 20;
BA_ "NWM-Botschaft" BO_ 1025 1;
BA_ "GenMsgStartValue" BO_ 1025 "FFFFFFFF000000FFh";
BA_ "GenMsgSendType" BO_ 1025 1;
BA_ "GenMsgNrOfRepetitions" BO_ 1025 2;
BA_ "GenMsgDelayTime" BO_ 1025 20;
BA_ "NWM-Botschaft" BO_ 1026 1;
BA_ "GenMsgStartValue" BO_ 1026 "FFFFFFFF000000FFh";
BA_ "GenMsgSendType" BO_ 1026 1;
BA_ "GenMsgNrOfRepetitions" BO_ 1026 2;
BA_ "GenMsgDelayTime" BO_ 1026 20;
BA_ "NWM-Botschaft" BO_ 1031 1;
BA_ "GenMsgStartValue" BO_ 1031 "FFFFFFFF000000FFh";
BA_ "GenMsgSendType" BO_ 1031 1;
BA_ "GenMsgNrOfRepetitions" BO_ 1031 2;
BA_ "GenMsgDelayTime" BO_ 1031 20;
BA_ "NWM-Botschaft" BO_ 1032 1;
BA_ "GenMsgStartValue" BO_ 1032 "FFFFFFFF000000FFh";
BA_ "GenMsgSendType" BO_ 1032 1;
BA_ "GenMsgNrOfRepetitions" BO_ 1032 2;
BA_ "GenMsgDelayTime" BO_ 1032 20;
BA_ "NWM-Botschaft" BO_ 1033 1;
BA_ "GenMsgStartValue" BO_ 1033 "FFFFFFFF000000FFh";
BA_ "GenMsgSendType" BO_ 1033 1;
BA_ "GenMsgNrOfRepetitions" BO_ 1033 2;
BA_ "GenMsgDelayTime" BO_ 1033 20;
BA_ "NWM-Botschaft" BO_ 1050 1;
BA_ "GenMsgStartValue" BO_ 1050 "FFFFFFFF000000FFh";
BA_ "GenMsgSendType" BO_ 1050 1;
BA_ "GenMsgNrOfRepetitions" BO_ 1050 2;
BA_ "GenMsgDelayTime" BO_ 1050 20;
BA_ "NWM-Botschaft" BO_ 1059 1;
BA_ "GenMsgStartValue" BO_ 1059 "FFFFFFFF000000FFh";
BA_ "GenMsgSendType" BO_ 1059 1;
BA_ "GenMsgNrOfRepetitions" BO_ 1059 2;
BA_ "GenMsgDelayTime" BO_ 1059 20;
BA_ "GenMsgStartValue" BO_ 1089 "0000000000000000h";
BA_ "GenMsgNrOfRepetitions" BO_ 1089 2;
BA_ "GenMsgDelayTime" BO_ 1089 20;
BA_ "DiagState" BO_ 1089 1;
BA_ "GenSigSNA" SG_ 1005 VC_BU_PwrIvtrTyp "0h";
BA_ "GenSigSendType" SG_ 1005 VC_BU_PwrIvtrTyp 1;
BA_ "FlexKomSigStartValue" SG_ 1005 VC_BU_PwrIvtrTyp "0300FF00FFFFFFFFh";
BA_ "FlexKomSigStartPos" SG_ 1005 VC_BU_PwrIvtrTyp 7;
BA_ "FlexKomSigName" SG_ 1005 VC_BU_PwrIvtrTyp "VehCfgBu2_Pkt";
BA_ "FlexKomSigLaenge" SG_ 1005 VC_BU_PwrIvtrTyp 64;
BA_ "FlexKomSID" SG_ 1005 VC_BU_PwrIvtrTyp 920;
BA_ "FlexKomIsMotorola" SG_ 1005 VC_BU_PwrIvtrTyp 1;
BA_ "FlexKomComment" SG_ 1005 VC_BU_PwrIvtrTyp "Vehicle Configuration Backup 2 Packet";
BA_ "GenSigSNA" SG_ 1005 VC_BU_MaseratiMd "3h";
BA_ "GenSigSendType" SG_ 1005 VC_BU_MaseratiMd 1;
BA_ "FlexKomSigStartValue" SG_ 1005 VC_BU_MaseratiMd "0300FF00FFFFFFFFh";
BA_ "FlexKomSigStartPos" SG_ 1005 VC_BU_MaseratiMd 7;
BA_ "FlexKomSigName" SG_ 1005 VC_BU_MaseratiMd "VehCfgBu2_Pkt";
BA_ "FlexKomSigLaenge" SG_ 1005 VC_BU_MaseratiMd 64;
BA_ "FlexKomSID" SG_ 1005 VC_BU_MaseratiMd 920;
BA_ "FlexKomIsMotorola" SG_ 1005 VC_BU_MaseratiMd 1;
BA_ "FlexKomComment" SG_ 1005 VC_BU_MaseratiMd "Vehicle Configuration Backup 2 Packet";
BA_ "GenSigSNA" SG_ 1005 VC_BU_FULL_SPARE "0h";
BA_ "GenSigSendType" SG_ 1005 VC_BU_FULL_SPARE 1;
BA_ "FlexKomSigStartValue" SG_ 1005 VC_BU_FULL_SPARE "0300FF00FFFFFFFFh";
BA_ "FlexKomSigStartPos" SG_ 1005 VC_BU_FULL_SPARE 7;
BA_ "FlexKomSigName" SG_ 1005 VC_BU_FULL_SPARE "VehCfgBu2_Pkt";
BA_ "FlexKomSigLaenge" SG_ 1005 VC_BU_FULL_SPARE 64;
BA_ "FlexKomSID" SG_ 1005 VC_BU_FULL_SPARE 920;
BA_ "FlexKomIsMotorola" SG_ 1005 VC_BU_FULL_SPARE 1;
BA_ "FlexKomComment" SG_ 1005 VC_BU_FULL_SPARE "Vehicle Configuration Backup 2 Packet";
BA_ "GenSigSNA" SG_ 1005 VC_BU_ECO_Indicator "0h";
BA_ "GenSigSendType" SG_ 1005 VC_BU_ECO_Indicator 1;
BA_ "FlexKomSigStartValue" SG_ 1005 VC_BU_ECO_Indicator "0300FF00FFFFFFFFh";
BA_ "FlexKomSigStartPos" SG_ 1005 VC_BU_ECO_Indicator 7;
BA_ "FlexKomSigName" SG_ 1005 VC_BU_ECO_Indicator "VehCfgBu2_Pkt";
BA_ "FlexKomSigLaenge" SG_ 1005 VC_BU_ECO_Indicator 64;
BA_ "FlexKomSID" SG_ 1005 VC_BU_ECO_Indicator 920;
BA_ "FlexKomIsMotorola" SG_ 1005 VC_BU_ECO_Indicator 1;
BA_ "FlexKomComment" SG_ 1005 VC_BU_ECO_Indicator "Vehicle Configuration Backup 2 Packet";
BA_ "GenSigSNA" SG_ 1005 VC_BU_EngPowerDrvMd_Prsnt "0h";
BA_ "GenSigSendType" SG_ 1005 VC_BU_EngPowerDrvMd_Prsnt 1;
BA_ "FlexKomSigStartValue" SG_ 1005 VC_BU_EngPowerDrvMd_Prsnt "0300FF00FFFFFFFFh";
BA_ "FlexKomSigStartPos" SG_ 1005 VC_BU_EngPowerDrvMd_Prsnt 7;
BA_ "FlexKomSigName" SG_ 1005 VC_BU_EngPowerDrvMd_Prsnt "VehCfgBu2_Pkt";
BA_ "FlexKomSigLaenge" SG_ 1005 VC_BU_EngPowerDrvMd_Prsnt 64;
BA_ "FlexKomSID" SG_ 1005 VC_BU_EngPowerDrvMd_Prsnt 920;
BA_ "FlexKomIsMotorola" SG_ 1005 VC_BU_EngPowerDrvMd_Prsnt 1;
BA_ "FlexKomComment" SG_ 1005 VC_BU_EngPowerDrvMd_Prsnt "Vehicle Configuration Backup 2 Packet";
BA_ "GenSigStartValue" SG_ 1005 VC_BU_MaxLdPressFtTr 255;
BA_ "GenSigSNA" SG_ 1005 VC_BU_MaxLdPressFtTr "FFh";
BA_ "GenSigSendType" SG_ 1005 VC_BU_MaxLdPressFtTr 1;
BA_ "FlexKomSigStartValue" SG_ 1005 VC_BU_MaxLdPressFtTr "0300FF00FFFFFFFFh";
BA_ "FlexKomSigStartPos" SG_ 1005 VC_BU_MaxLdPressFtTr 7;
BA_ "FlexKomSigName" SG_ 1005 VC_BU_MaxLdPressFtTr "VehCfgBu2_Pkt";
BA_ "FlexKomSigLaenge" SG_ 1005 VC_BU_MaxLdPressFtTr 64;
BA_ "FlexKomSID" SG_ 1005 VC_BU_MaxLdPressFtTr 920;
BA_ "FlexKomIsMotorola" SG_ 1005 VC_BU_MaxLdPressFtTr 1;
BA_ "FlexKomComment" SG_ 1005 VC_BU_MaxLdPressFtTr "Vehicle Configuration Backup 2 Packet";
BA_ "GenSigStartValue" SG_ 1005 VC_BU_LgtLdPressRrTr 255;
BA_ "GenSigSNA" SG_ 1005 VC_BU_LgtLdPressRrTr "FFh";
BA_ "GenSigSendType" SG_ 1005 VC_BU_LgtLdPressRrTr 1;
BA_ "FlexKomSigStartValue" SG_ 1005 VC_BU_LgtLdPressRrTr "0300FF00FFFFFFFFh";
BA_ "FlexKomSigStartPos" SG_ 1005 VC_BU_LgtLdPressRrTr 7;
BA_ "FlexKomSigName" SG_ 1005 VC_BU_LgtLdPressRrTr "VehCfgBu2_Pkt";
BA_ "FlexKomSigLaenge" SG_ 1005 VC_BU_LgtLdPressRrTr 64;
BA_ "FlexKomSID" SG_ 1005 VC_BU_LgtLdPressRrTr 920;
BA_ "FlexKomIsMotorola" SG_ 1005 VC_BU_LgtLdPressRrTr 1;
BA_ "FlexKomComment" SG_ 1005 VC_BU_LgtLdPressRrTr "Vehicle Configuration Backup 2 Packet";
BA_ "GenSigStartValue" SG_ 1005 VC_BU_LgtLdPressFtTr 255;
BA_ "GenSigSNA" SG_ 1005 VC_BU_LgtLdPressFtTr "FFh";
BA_ "GenSigSendType" SG_ 1005 VC_BU_LgtLdPressFtTr 1;
BA_ "FlexKomSigStartValue" SG_ 1005 VC_BU_LgtLdPressFtTr "0300FF00FFFFFFFFh";
BA_ "FlexKomSigStartPos" SG_ 1005 VC_BU_LgtLdPressFtTr 7;
BA_ "FlexKomSigName" SG_ 1005 VC_BU_LgtLdPressFtTr "VehCfgBu2_Pkt";
BA_ "FlexKomSigLaenge" SG_ 1005 VC_BU_LgtLdPressFtTr 64;
BA_ "FlexKomSID" SG_ 1005 VC_BU_LgtLdPressFtTr 920;
BA_ "FlexKomIsMotorola" SG_ 1005 VC_BU_LgtLdPressFtTr 1;
BA_ "FlexKomComment" SG_ 1005 VC_BU_LgtLdPressFtTr "Vehicle Configuration Backup 2 Packet";
BA_ "GenSigSNA" SG_ 1005 VC_BU_SecPrkPrsnt "0h";
BA_ "GenSigSendType" SG_ 1005 VC_BU_SecPrkPrsnt 1;
BA_ "FlexKomSigStartValue" SG_ 1005 VC_BU_SecPrkPrsnt "0300FF00FFFFFFFFh";
BA_ "FlexKomSigStartPos" SG_ 1005 VC_BU_SecPrkPrsnt 7;
BA_ "FlexKomSigName" SG_ 1005 VC_BU_SecPrkPrsnt "VehCfgBu2_Pkt";
BA_ "FlexKomSigLaenge" SG_ 1005 VC_BU_SecPrkPrsnt 64;
BA_ "FlexKomSID" SG_ 1005 VC_BU_SecPrkPrsnt 920;
BA_ "FlexKomIsMotorola" SG_ 1005 VC_BU_SecPrkPrsnt 1;
BA_ "FlexKomComment" SG_ 1005 VC_BU_SecPrkPrsnt "Vehicle Configuration Backup 2 Packet";
BA_ "GenSigSNA" SG_ 1005 VC_BU_ShftInd_Prsnt "0h";
BA_ "GenSigSendType" SG_ 1005 VC_BU_ShftInd_Prsnt 1;
BA_ "FlexKomSigStartValue" SG_ 1005 VC_BU_ShftInd_Prsnt "0300FF00FFFFFFFFh";
BA_ "FlexKomSigStartPos" SG_ 1005 VC_BU_ShftInd_Prsnt 7;
BA_ "FlexKomSigName" SG_ 1005 VC_BU_ShftInd_Prsnt "VehCfgBu2_Pkt";
BA_ "FlexKomSigLaenge" SG_ 1005 VC_BU_ShftInd_Prsnt 64;
BA_ "FlexKomSID" SG_ 1005 VC_BU_ShftInd_Prsnt 920;
BA_ "FlexKomIsMotorola" SG_ 1005 VC_BU_ShftInd_Prsnt 1;
BA_ "FlexKomComment" SG_ 1005 VC_BU_ShftInd_Prsnt "Vehicle Configuration Backup 2 Packet";
BA_ "GenSigSNA" SG_ 1005 VC_BU_DRVMD_Prsnt "0h";
BA_ "GenSigSendType" SG_ 1005 VC_BU_DRVMD_Prsnt 1;
BA_ "FlexKomSigStartValue" SG_ 1005 VC_BU_DRVMD_Prsnt "0300FF00FFFFFFFFh";
BA_ "FlexKomSigStartPos" SG_ 1005 VC_BU_DRVMD_Prsnt 7;
BA_ "FlexKomSigName" SG_ 1005 VC_BU_DRVMD_Prsnt "VehCfgBu2_Pkt";
BA_ "FlexKomSigLaenge" SG_ 1005 VC_BU_DRVMD_Prsnt 64;
BA_ "FlexKomSID" SG_ 1005 VC_BU_DRVMD_Prsnt 920;
BA_ "FlexKomIsMotorola" SG_ 1005 VC_BU_DRVMD_Prsnt 1;
BA_ "FlexKomComment" SG_ 1005 VC_BU_DRVMD_Prsnt "Vehicle Configuration Backup 2 Packet";
BA_ "GenSigSNA" SG_ 1005 VC_BU_MemoryDRVMD_Prsnt "0h";
BA_ "GenSigSendType" SG_ 1005 VC_BU_MemoryDRVMD_Prsnt 1;
BA_ "FlexKomSigStartValue" SG_ 1005 VC_BU_MemoryDRVMD_Prsnt "0300FF00FFFFFFFFh";
BA_ "FlexKomSigStartPos" SG_ 1005 VC_BU_MemoryDRVMD_Prsnt 7;
BA_ "FlexKomSigName" SG_ 1005 VC_BU_MemoryDRVMD_Prsnt "VehCfgBu2_Pkt";
BA_ "FlexKomSigLaenge" SG_ 1005 VC_BU_MemoryDRVMD_Prsnt 64;
BA_ "FlexKomSID" SG_ 1005 VC_BU_MemoryDRVMD_Prsnt 920;
BA_ "FlexKomIsMotorola" SG_ 1005 VC_BU_MemoryDRVMD_Prsnt 1;
BA_ "FlexKomComment" SG_ 1005 VC_BU_MemoryDRVMD_Prsnt "Vehicle Configuration Backup 2 Packet";
BA_ "GenSigSNA" SG_ 1005 VC_BU_ESCDrvMd_Prsnt "0h";
BA_ "GenSigSendType" SG_ 1005 VC_BU_ESCDrvMd_Prsnt 1;
BA_ "FlexKomSigStartValue" SG_ 1005 VC_BU_ESCDrvMd_Prsnt "0300FF00FFFFFFFFh";
BA_ "FlexKomSigStartPos" SG_ 1005 VC_BU_ESCDrvMd_Prsnt 7;
BA_ "FlexKomSigName" SG_ 1005 VC_BU_ESCDrvMd_Prsnt "VehCfgBu2_Pkt";
BA_ "FlexKomSigLaenge" SG_ 1005 VC_BU_ESCDrvMd_Prsnt 64;
BA_ "FlexKomSID" SG_ 1005 VC_BU_ESCDrvMd_Prsnt 920;
BA_ "FlexKomIsMotorola" SG_ 1005 VC_BU_ESCDrvMd_Prsnt 1;
BA_ "FlexKomComment" SG_ 1005 VC_BU_ESCDrvMd_Prsnt "Vehicle Configuration Backup 2 Packet";
BA_ "GenSigStartValue" SG_ 1005 VC_BU_MaxLdPressRrTr 255;
BA_ "GenSigSNA" SG_ 1005 VC_BU_MaxLdPressRrTr "FFh";
BA_ "GenSigSendType" SG_ 1005 VC_BU_MaxLdPressRrTr 1;
BA_ "FlexKomSigStartValue" SG_ 1005 VC_BU_MaxLdPressRrTr "0300FF00FFFFFFFFh";
BA_ "FlexKomSigStartPos" SG_ 1005 VC_BU_MaxLdPressRrTr 7;
BA_ "FlexKomSigName" SG_ 1005 VC_BU_MaxLdPressRrTr "VehCfgBu2_Pkt";
BA_ "FlexKomSigLaenge" SG_ 1005 VC_BU_MaxLdPressRrTr 64;
BA_ "FlexKomSID" SG_ 1005 VC_BU_MaxLdPressRrTr 920;
BA_ "FlexKomIsMotorola" SG_ 1005 VC_BU_MaxLdPressRrTr 1;
BA_ "FlexKomComment" SG_ 1005 VC_BU_MaxLdPressRrTr "Vehicle Configuration Backup 2 Packet";
BA_ "GenSigSNA" SG_ 1005 VC_BU_OffRoad "0h";
BA_ "GenSigSendType" SG_ 1005 VC_BU_OffRoad 1;
BA_ "FlexKomSigStartValue" SG_ 1005 VC_BU_OffRoad "0300FF00FFFFFFFFh";
BA_ "FlexKomSigStartPos" SG_ 1005 VC_BU_OffRoad 7;
BA_ "FlexKomSigName" SG_ 1005 VC_BU_OffRoad "VehCfgBu2_Pkt";
BA_ "FlexKomSigLaenge" SG_ 1005 VC_BU_OffRoad 64;
BA_ "FlexKomSID" SG_ 1005 VC_BU_OffRoad 920;
BA_ "FlexKomIsMotorola" SG_ 1005 VC_BU_OffRoad 1;
BA_ "FlexKomComment" SG_ 1005 VC_BU_OffRoad "Vehicle Configuration Backup 2 Packet";
BA_ "GenSigSNA" SG_ 1005 VC_BU_PADS_Prsnt "0h";
BA_ "GenSigSendType" SG_ 1005 VC_BU_PADS_Prsnt 1;
BA_ "FlexKomSigStartValue" SG_ 1005 VC_BU_PADS_Prsnt "0300FF00FFFFFFFFh";
BA_ "FlexKomSigStartPos" SG_ 1005 VC_BU_PADS_Prsnt 7;
BA_ "FlexKomSigName" SG_ 1005 VC_BU_PADS_Prsnt "VehCfgBu2_Pkt";
BA_ "FlexKomSigLaenge" SG_ 1005 VC_BU_PADS_Prsnt 64;
BA_ "FlexKomSID" SG_ 1005 VC_BU_PADS_Prsnt 920;
BA_ "FlexKomIsMotorola" SG_ 1005 VC_BU_PADS_Prsnt 1;
BA_ "FlexKomComment" SG_ 1005 VC_BU_PADS_Prsnt "Vehicle Configuration Backup 2 Packet";
BA_ "GenSigSNA" SG_ 1005 VC_BU_RainSnsPrsnt "0h";
BA_ "GenSigSendType" SG_ 1005 VC_BU_RainSnsPrsnt 1;
BA_ "FlexKomSigStartValue" SG_ 1005 VC_BU_RainSnsPrsnt "0300FF00FFFFFFFFh";
BA_ "FlexKomSigStartPos" SG_ 1005 VC_BU_RainSnsPrsnt 7;
BA_ "FlexKomSigName" SG_ 1005 VC_BU_RainSnsPrsnt "VehCfgBu2_Pkt";
BA_ "FlexKomSigLaenge" SG_ 1005 VC_BU_RainSnsPrsnt 64;
BA_ "FlexKomSID" SG_ 1005 VC_BU_RainSnsPrsnt 920;
BA_ "FlexKomIsMotorola" SG_ 1005 VC_BU_RainSnsPrsnt 1;
BA_ "FlexKomComment" SG_ 1005 VC_BU_RainSnsPrsnt "Vehicle Configuration Backup 2 Packet";
BA_ "GenSigSNA" SG_ 1005 VC_BU_SKIM_PRSNT "0h";
BA_ "GenSigSendType" SG_ 1005 VC_BU_SKIM_PRSNT 1;
BA_ "FlexKomSigStartValue" SG_ 1005 VC_BU_SKIM_PRSNT "0300FF00FFFFFFFFh";
BA_ "FlexKomSigStartPos" SG_ 1005 VC_BU_SKIM_PRSNT 7;
BA_ "FlexKomSigName" SG_ 1005 VC_BU_SKIM_PRSNT "VehCfgBu2_Pkt";
BA_ "FlexKomSigLaenge" SG_ 1005 VC_BU_SKIM_PRSNT 64;
BA_ "FlexKomSID" SG_ 1005 VC_BU_SKIM_PRSNT 920;
BA_ "FlexKomIsMotorola" SG_ 1005 VC_BU_SKIM_PRSNT 1;
BA_ "FlexKomComment" SG_ 1005 VC_BU_SKIM_PRSNT "Vehicle Configuration Backup 2 Packet";
BA_ "GenSigSNA" SG_ 1005 VC_BU_AC_Prsnt "0h";
BA_ "GenSigSendType" SG_ 1005 VC_BU_AC_Prsnt 1;
BA_ "FlexKomSigStartValue" SG_ 1005 VC_BU_AC_Prsnt "0300FF00FFFFFFFFh";
BA_ "FlexKomSigStartPos" SG_ 1005 VC_BU_AC_Prsnt 7;
BA_ "FlexKomSigName" SG_ 1005 VC_BU_AC_Prsnt "VehCfgBu2_Pkt";
BA_ "FlexKomSigLaenge" SG_ 1005 VC_BU_AC_Prsnt 64;
BA_ "FlexKomSID" SG_ 1005 VC_BU_AC_Prsnt 920;
BA_ "FlexKomIsMotorola" SG_ 1005 VC_BU_AC_Prsnt 1;
BA_ "FlexKomComment" SG_ 1005 VC_BU_AC_Prsnt "Vehicle Configuration Backup 2 Packet";
BA_ "GenSigSNA" SG_ 1005 VC_BU_CRUISE_PRSNT "0h";
BA_ "GenSigSendType" SG_ 1005 VC_BU_CRUISE_PRSNT 1;
BA_ "FlexKomSigStartValue" SG_ 1005 VC_BU_CRUISE_PRSNT "0300FF00FFFFFFFFh";
BA_ "FlexKomSigStartPos" SG_ 1005 VC_BU_CRUISE_PRSNT 7;
BA_ "FlexKomSigName" SG_ 1005 VC_BU_CRUISE_PRSNT "VehCfgBu2_Pkt";
BA_ "FlexKomSigLaenge" SG_ 1005 VC_BU_CRUISE_PRSNT 64;
BA_ "FlexKomSID" SG_ 1005 VC_BU_CRUISE_PRSNT 920;
BA_ "FlexKomIsMotorola" SG_ 1005 VC_BU_CRUISE_PRSNT 1;
BA_ "FlexKomComment" SG_ 1005 VC_BU_CRUISE_PRSNT "Vehicle Configuration Backup 2 Packet";
BA_ "GenSigSNA" SG_ 1005 VC_BU_FG_PRSNT "0h";
BA_ "GenSigSendType" SG_ 1005 VC_BU_FG_PRSNT 1;
BA_ "FlexKomSigStartValue" SG_ 1005 VC_BU_FG_PRSNT "0300FF00FFFFFFFFh";
BA_ "FlexKomSigStartPos" SG_ 1005 VC_BU_FG_PRSNT 7;
BA_ "FlexKomSigName" SG_ 1005 VC_BU_FG_PRSNT "VehCfgBu2_Pkt";
BA_ "FlexKomSigLaenge" SG_ 1005 VC_BU_FG_PRSNT 64;
BA_ "FlexKomSID" SG_ 1005 VC_BU_FG_PRSNT 920;
BA_ "FlexKomIsMotorola" SG_ 1005 VC_BU_FG_PRSNT 1;
BA_ "FlexKomComment" SG_ 1005 VC_BU_FG_PRSNT "Vehicle Configuration Backup 2 Packet";
BA_ "GenSigSNA" SG_ 1005 VC_BU_ThatchamPrsnt "0h";
BA_ "GenSigSendType" SG_ 1005 VC_BU_ThatchamPrsnt 1;
BA_ "FlexKomSigStartValue" SG_ 1005 VC_BU_ThatchamPrsnt "0300FF00FFFFFFFFh";
BA_ "FlexKomSigStartPos" SG_ 1005 VC_BU_ThatchamPrsnt 7;
BA_ "FlexKomSigName" SG_ 1005 VC_BU_ThatchamPrsnt "VehCfgBu2_Pkt";
BA_ "FlexKomSigLaenge" SG_ 1005 VC_BU_ThatchamPrsnt 64;
BA_ "FlexKomSID" SG_ 1005 VC_BU_ThatchamPrsnt 920;
BA_ "FlexKomIsMotorola" SG_ 1005 VC_BU_ThatchamPrsnt 1;
BA_ "FlexKomComment" SG_ 1005 VC_BU_ThatchamPrsnt "Vehicle Configuration Backup 2 Packet";
BA_ "GenSigSNA" SG_ 1005 VC_BU_RunFlatTirePrsnt "0h";
BA_ "GenSigSendType" SG_ 1005 VC_BU_RunFlatTirePrsnt 1;
BA_ "FlexKomSigStartValue" SG_ 1005 VC_BU_RunFlatTirePrsnt "0300FF00FFFFFFFFh";
BA_ "FlexKomSigStartPos" SG_ 1005 VC_BU_RunFlatTirePrsnt 7;
BA_ "FlexKomSigName" SG_ 1005 VC_BU_RunFlatTirePrsnt "VehCfgBu2_Pkt";
BA_ "FlexKomSigLaenge" SG_ 1005 VC_BU_RunFlatTirePrsnt 64;
BA_ "FlexKomSID" SG_ 1005 VC_BU_RunFlatTirePrsnt 920;
BA_ "FlexKomIsMotorola" SG_ 1005 VC_BU_RunFlatTirePrsnt 1;
BA_ "FlexKomComment" SG_ 1005 VC_BU_RunFlatTirePrsnt "Vehicle Configuration Backup 2 Packet";
BA_ "GenSigStartValue" SG_ 1005 VC_BU_VehCfg2_Stat 3;
BA_ "GenSigSNA" SG_ 1005 VC_BU_VehCfg2_Stat "3h";
BA_ "GenSigSendType" SG_ 1005 VC_BU_VehCfg2_Stat 1;
BA_ "FlexKomSigStartValue" SG_ 1005 VC_BU_VehCfg2_Stat "0300FF00FFFFFFFFh";
BA_ "FlexKomSigStartPos" SG_ 1005 VC_BU_VehCfg2_Stat 7;
BA_ "FlexKomSigName" SG_ 1005 VC_BU_VehCfg2_Stat "VehCfgBu2_Pkt";
BA_ "FlexKomSigLaenge" SG_ 1005 VC_BU_VehCfg2_Stat 64;
BA_ "FlexKomSID" SG_ 1005 VC_BU_VehCfg2_Stat 920;
BA_ "FlexKomIsMotorola" SG_ 1005 VC_BU_VehCfg2_Stat 1;
BA_ "FlexKomComment" SG_ 1005 VC_BU_VehCfg2_Stat "Vehicle Configuration Backup 2 Packet";
BA_ "GenSigStartValue" SG_ 1005 VC_BU_SpecialPKG_IC 255;
BA_ "GenSigSNA" SG_ 1005 VC_BU_SpecialPKG_IC "FFh";
BA_ "GenSigSendType" SG_ 1005 VC_BU_SpecialPKG_IC 1;
BA_ "FlexKomSigStartValue" SG_ 1005 VC_BU_SpecialPKG_IC "0300FF00FFFFFFFFh";
BA_ "FlexKomSigStartPos" SG_ 1005 VC_BU_SpecialPKG_IC 7;
BA_ "FlexKomSigName" SG_ 1005 VC_BU_SpecialPKG_IC "VehCfgBu2_Pkt";
BA_ "FlexKomSigLaenge" SG_ 1005 VC_BU_SpecialPKG_IC 64;
BA_ "FlexKomSID" SG_ 1005 VC_BU_SpecialPKG_IC 920;
BA_ "FlexKomIsMotorola" SG_ 1005 VC_BU_SpecialPKG_IC 1;
BA_ "FlexKomComment" SG_ 1005 VC_BU_SpecialPKG_IC "Vehicle Configuration Backup 2 Packet";
BA_ "GenSigSNA" SG_ 1006 VC_BU_AutoParkPrsnt "0h";
BA_ "GenSigSendType" SG_ 1006 VC_BU_AutoParkPrsnt 1;
BA_ "FlexKomSigStartValue" SG_ 1006 VC_BU_AutoParkPrsnt "0370FF037FFF0000h";
BA_ "FlexKomSigStartPos" SG_ 1006 VC_BU_AutoParkPrsnt 7;
BA_ "FlexKomSigName" SG_ 1006 VC_BU_AutoParkPrsnt "VehCfgBu3_Pkt";
BA_ "FlexKomSigLaenge" SG_ 1006 VC_BU_AutoParkPrsnt 64;
BA_ "FlexKomSID" SG_ 1006 VC_BU_AutoParkPrsnt 921;
BA_ "FlexKomIsMotorola" SG_ 1006 VC_BU_AutoParkPrsnt 1;
BA_ "FlexKomComment" SG_ 1006 VC_BU_AutoParkPrsnt "Vehicle Configuration Backup 3 Packet";
BA_ "GenSigSNA" SG_ 1006 VC_BU_PE_Prsnt "0h";
BA_ "GenSigSendType" SG_ 1006 VC_BU_PE_Prsnt 1;
BA_ "FlexKomSigStartValue" SG_ 1006 VC_BU_PE_Prsnt "0370FF037FFF0000h";
BA_ "FlexKomSigStartPos" SG_ 1006 VC_BU_PE_Prsnt 7;
BA_ "FlexKomSigName" SG_ 1006 VC_BU_PE_Prsnt "VehCfgBu3_Pkt";
BA_ "FlexKomSigLaenge" SG_ 1006 VC_BU_PE_Prsnt 64;
BA_ "FlexKomSID" SG_ 1006 VC_BU_PE_Prsnt 921;
BA_ "FlexKomIsMotorola" SG_ 1006 VC_BU_PE_Prsnt 1;
BA_ "FlexKomComment" SG_ 1006 VC_BU_PE_Prsnt "Vehicle Configuration Backup 3 Packet";
BA_ "GenSigSNA" SG_ 1006 VC_BU_KG_Prsnt "0h";
BA_ "GenSigSendType" SG_ 1006 VC_BU_KG_Prsnt 1;
BA_ "FlexKomSigStartValue" SG_ 1006 VC_BU_KG_Prsnt "0370FF037FFF0000h";
BA_ "FlexKomSigStartPos" SG_ 1006 VC_BU_KG_Prsnt 7;
BA_ "FlexKomSigName" SG_ 1006 VC_BU_KG_Prsnt "VehCfgBu3_Pkt";
BA_ "FlexKomSigLaenge" SG_ 1006 VC_BU_KG_Prsnt 64;
BA_ "FlexKomSID" SG_ 1006 VC_BU_KG_Prsnt 921;
BA_ "FlexKomIsMotorola" SG_ 1006 VC_BU_KG_Prsnt 1;
BA_ "FlexKomComment" SG_ 1006 VC_BU_KG_Prsnt "Vehicle Configuration Backup 3 Packet";
BA_ "GenSigSNA" SG_ 1006 VC_BU_Prem_TPM "0h";
BA_ "GenSigSendType" SG_ 1006 VC_BU_Prem_TPM 1;
BA_ "FlexKomSigStartValue" SG_ 1006 VC_BU_Prem_TPM "0370FF037FFF0000h";
BA_ "FlexKomSigStartPos" SG_ 1006 VC_BU_Prem_TPM 7;
BA_ "FlexKomSigName" SG_ 1006 VC_BU_Prem_TPM "VehCfgBu3_Pkt";
BA_ "FlexKomSigLaenge" SG_ 1006 VC_BU_Prem_TPM 64;
BA_ "FlexKomSID" SG_ 1006 VC_BU_Prem_TPM 921;
BA_ "FlexKomIsMotorola" SG_ 1006 VC_BU_Prem_TPM 1;
BA_ "FlexKomComment" SG_ 1006 VC_BU_Prem_TPM "Vehicle Configuration Backup 3 Packet";
BA_ "GenSigSNA" SG_ 1006 VC_BU_PDDL_PRSNT "0h";
BA_ "GenSigSendType" SG_ 1006 VC_BU_PDDL_PRSNT 1;
BA_ "FlexKomSigStartValue" SG_ 1006 VC_BU_PDDL_PRSNT "0370FF037FFF0000h";
BA_ "FlexKomSigStartPos" SG_ 1006 VC_BU_PDDL_PRSNT 7;
BA_ "FlexKomSigName" SG_ 1006 VC_BU_PDDL_PRSNT "VehCfgBu3_Pkt";
BA_ "FlexKomSigLaenge" SG_ 1006 VC_BU_PDDL_PRSNT 64;
BA_ "FlexKomSID" SG_ 1006 VC_BU_PDDL_PRSNT 921;
BA_ "FlexKomIsMotorola" SG_ 1006 VC_BU_PDDL_PRSNT 1;
BA_ "FlexKomComment" SG_ 1006 VC_BU_PDDL_PRSNT "Vehicle Configuration Backup 3 Packet";
BA_ "GenSigSNA" SG_ 1006 VC_BU_CMS "0h";
BA_ "GenSigSendType" SG_ 1006 VC_BU_CMS 1;
BA_ "FlexKomSigStartValue" SG_ 1006 VC_BU_CMS "0370FF037FFF0000h";
BA_ "FlexKomSigStartPos" SG_ 1006 VC_BU_CMS 7;
BA_ "FlexKomSigName" SG_ 1006 VC_BU_CMS "VehCfgBu3_Pkt";
BA_ "FlexKomSigLaenge" SG_ 1006 VC_BU_CMS 64;
BA_ "FlexKomSID" SG_ 1006 VC_BU_CMS 921;
BA_ "FlexKomIsMotorola" SG_ 1006 VC_BU_CMS 1;
BA_ "FlexKomComment" SG_ 1006 VC_BU_CMS "Vehicle Configuration Backup 3 Packet";
BA_ "GenSigSNA" SG_ 1006 VC_BU_FCW "0h";
BA_ "GenSigSendType" SG_ 1006 VC_BU_FCW 1;
BA_ "FlexKomSigStartValue" SG_ 1006 VC_BU_FCW "0370FF037FFF0000h";
BA_ "FlexKomSigStartPos" SG_ 1006 VC_BU_FCW 7;
BA_ "FlexKomSigName" SG_ 1006 VC_BU_FCW "VehCfgBu3_Pkt";
BA_ "FlexKomSigLaenge" SG_ 1006 VC_BU_FCW 64;
BA_ "FlexKomSID" SG_ 1006 VC_BU_FCW 921;
BA_ "FlexKomIsMotorola" SG_ 1006 VC_BU_FCW 1;
BA_ "FlexKomComment" SG_ 1006 VC_BU_FCW "Vehicle Configuration Backup 3 Packet";
BA_ "GenSigSNA" SG_ 1006 VC_BU_SecLkPrsnt "0h";
BA_ "GenSigSendType" SG_ 1006 VC_BU_SecLkPrsnt 1;
BA_ "FlexKomSigStartValue" SG_ 1006 VC_BU_SecLkPrsnt "0370FF037FFF0000h";
BA_ "FlexKomSigStartPos" SG_ 1006 VC_BU_SecLkPrsnt 7;
BA_ "FlexKomSigName" SG_ 1006 VC_BU_SecLkPrsnt "VehCfgBu3_Pkt";
BA_ "FlexKomSigLaenge" SG_ 1006 VC_BU_SecLkPrsnt 64;
BA_ "FlexKomSID" SG_ 1006 VC_BU_SecLkPrsnt 921;
BA_ "FlexKomIsMotorola" SG_ 1006 VC_BU_SecLkPrsnt 1;
BA_ "FlexKomComment" SG_ 1006 VC_BU_SecLkPrsnt "Vehicle Configuration Backup 3 Packet";
BA_ "GenSigStartValue" SG_ 1006 VC_BU_VEH_BRAND 15;
BA_ "GenSigSNA" SG_ 1006 VC_BU_VEH_BRAND "Fh";
BA_ "GenSigSendType" SG_ 1006 VC_BU_VEH_BRAND 1;
BA_ "FlexKomSigStartValue" SG_ 1006 VC_BU_VEH_BRAND "0370FF037FFF0000h";
BA_ "FlexKomSigStartPos" SG_ 1006 VC_BU_VEH_BRAND 7;
BA_ "FlexKomSigName" SG_ 1006 VC_BU_VEH_BRAND "VehCfgBu3_Pkt";
BA_ "FlexKomSigLaenge" SG_ 1006 VC_BU_VEH_BRAND 64;
BA_ "FlexKomSID" SG_ 1006 VC_BU_VEH_BRAND 921;
BA_ "FlexKomIsMotorola" SG_ 1006 VC_BU_VEH_BRAND 1;
BA_ "FlexKomComment" SG_ 1006 VC_BU_VEH_BRAND "Vehicle Configuration Backup 3 Packet";
BA_ "GenSigSNA" SG_ 1006 VC_BU_CMP_DISP "0h";
BA_ "GenSigSendType" SG_ 1006 VC_BU_CMP_DISP 1;
BA_ "FlexKomSigStartValue" SG_ 1006 VC_BU_CMP_DISP "0370FF037FFF0000h";
BA_ "FlexKomSigStartPos" SG_ 1006 VC_BU_CMP_DISP 7;
BA_ "FlexKomSigName" SG_ 1006 VC_BU_CMP_DISP "VehCfgBu3_Pkt";
BA_ "FlexKomSigLaenge" SG_ 1006 VC_BU_CMP_DISP 64;
BA_ "FlexKomSID" SG_ 1006 VC_BU_CMP_DISP 921;
BA_ "FlexKomIsMotorola" SG_ 1006 VC_BU_CMP_DISP 1;
BA_ "FlexKomComment" SG_ 1006 VC_BU_CMP_DISP "Vehicle Configuration Backup 3 Packet";
BA_ "GenSigSNA" SG_ 1006 VC_BU_IntEC_MIRR "0h";
BA_ "GenSigSendType" SG_ 1006 VC_BU_IntEC_MIRR 1;
BA_ "FlexKomSigStartValue" SG_ 1006 VC_BU_IntEC_MIRR "0370FF037FFF0000h";
BA_ "FlexKomSigStartPos" SG_ 1006 VC_BU_IntEC_MIRR 7;
BA_ "FlexKomSigName" SG_ 1006 VC_BU_IntEC_MIRR "VehCfgBu3_Pkt";
BA_ "FlexKomSigLaenge" SG_ 1006 VC_BU_IntEC_MIRR 64;
BA_ "FlexKomSID" SG_ 1006 VC_BU_IntEC_MIRR 921;
BA_ "FlexKomIsMotorola" SG_ 1006 VC_BU_IntEC_MIRR 1;
BA_ "FlexKomComment" SG_ 1006 VC_BU_IntEC_MIRR "Vehicle Configuration Backup 3 Packet";
BA_ "GenSigSNA" SG_ 1006 VC_BU_ESCL_Prsnt "0h";
BA_ "GenSigSendType" SG_ 1006 VC_BU_ESCL_Prsnt 1;
BA_ "FlexKomSigStartValue" SG_ 1006 VC_BU_ESCL_Prsnt "0370FF037FFF0000h";
BA_ "FlexKomSigStartPos" SG_ 1006 VC_BU_ESCL_Prsnt 7;
BA_ "FlexKomSigName" SG_ 1006 VC_BU_ESCL_Prsnt "VehCfgBu3_Pkt";
BA_ "FlexKomSigLaenge" SG_ 1006 VC_BU_ESCL_Prsnt 64;
BA_ "FlexKomSID" SG_ 1006 VC_BU_ESCL_Prsnt 921;
BA_ "FlexKomIsMotorola" SG_ 1006 VC_BU_ESCL_Prsnt 1;
BA_ "FlexKomComment" SG_ 1006 VC_BU_ESCL_Prsnt "Vehicle Configuration Backup 3 Packet";
BA_ "GenSigSNA" SG_ 1006 VC_BU_DrAlrPrsnt "0h";
BA_ "GenSigSendType" SG_ 1006 VC_BU_DrAlrPrsnt 1;
BA_ "FlexKomSigStartValue" SG_ 1006 VC_BU_DrAlrPrsnt "0370FF037FFF0000h";
BA_ "FlexKomSigStartPos" SG_ 1006 VC_BU_DrAlrPrsnt 7;
BA_ "FlexKomSigName" SG_ 1006 VC_BU_DrAlrPrsnt "VehCfgBu3_Pkt";
BA_ "FlexKomSigLaenge" SG_ 1006 VC_BU_DrAlrPrsnt 64;
BA_ "FlexKomSID" SG_ 1006 VC_BU_DrAlrPrsnt 921;
BA_ "FlexKomIsMotorola" SG_ 1006 VC_BU_DrAlrPrsnt 1;
BA_ "FlexKomComment" SG_ 1006 VC_BU_DrAlrPrsnt "Vehicle Configuration Backup 3 Packet";
BA_ "GenSigSNA" SG_ 1006 VC_BU_DualFuelSens "0h";
BA_ "GenSigSendType" SG_ 1006 VC_BU_DualFuelSens 1;
BA_ "FlexKomSigStartValue" SG_ 1006 VC_BU_DualFuelSens "0370FF037FFF0000h";
BA_ "FlexKomSigStartPos" SG_ 1006 VC_BU_DualFuelSens 7;
BA_ "FlexKomSigName" SG_ 1006 VC_BU_DualFuelSens "VehCfgBu3_Pkt";
BA_ "FlexKomSigLaenge" SG_ 1006 VC_BU_DualFuelSens 64;
BA_ "FlexKomSID" SG_ 1006 VC_BU_DualFuelSens 921;
BA_ "FlexKomIsMotorola" SG_ 1006 VC_BU_DualFuelSens 1;
BA_ "FlexKomComment" SG_ 1006 VC_BU_DualFuelSens "Vehicle Configuration Backup 3 Packet";
BA_ "GenSigSNA" SG_ 1006 VC_BU_SRT_PRSNT "0h";
BA_ "GenSigSendType" SG_ 1006 VC_BU_SRT_PRSNT 1;
BA_ "FlexKomSigStartValue" SG_ 1006 VC_BU_SRT_PRSNT "0370FF037FFF0000h";
BA_ "FlexKomSigStartPos" SG_ 1006 VC_BU_SRT_PRSNT 7;
BA_ "FlexKomSigName" SG_ 1006 VC_BU_SRT_PRSNT "VehCfgBu3_Pkt";
BA_ "FlexKomSigLaenge" SG_ 1006 VC_BU_SRT_PRSNT 64;
BA_ "FlexKomSID" SG_ 1006 VC_BU_SRT_PRSNT 921;
BA_ "FlexKomIsMotorola" SG_ 1006 VC_BU_SRT_PRSNT 1;
BA_ "FlexKomComment" SG_ 1006 VC_BU_SRT_PRSNT "Vehicle Configuration Backup 3 Packet";
BA_ "GenSigSNA" SG_ 1006 VC_BU_DSBL_CLK_DISP "0h";
BA_ "GenSigSendType" SG_ 1006 VC_BU_DSBL_CLK_DISP 1;
BA_ "FlexKomSigStartValue" SG_ 1006 VC_BU_DSBL_CLK_DISP "0370FF037FFF0000h";
BA_ "FlexKomSigStartPos" SG_ 1006 VC_BU_DSBL_CLK_DISP 7;
BA_ "FlexKomSigName" SG_ 1006 VC_BU_DSBL_CLK_DISP "VehCfgBu3_Pkt";
BA_ "FlexKomSigLaenge" SG_ 1006 VC_BU_DSBL_CLK_DISP 64;
BA_ "FlexKomSID" SG_ 1006 VC_BU_DSBL_CLK_DISP 921;
BA_ "FlexKomIsMotorola" SG_ 1006 VC_BU_DSBL_CLK_DISP 1;
BA_ "FlexKomComment" SG_ 1006 VC_BU_DSBL_CLK_DISP "Vehicle Configuration Backup 3 Packet";
BA_ "GenSigStartValue" SG_ 1006 VC_BU_ChassisType 127;
BA_ "GenSigSNA" SG_ 1006 VC_BU_ChassisType "7Fh";
BA_ "GenSigSendType" SG_ 1006 VC_BU_ChassisType 1;
BA_ "FlexKomSigStartValue" SG_ 1006 VC_BU_ChassisType "0370FF037FFF0000h";
BA_ "FlexKomSigStartPos" SG_ 1006 VC_BU_ChassisType 7;
BA_ "FlexKomSigName" SG_ 1006 VC_BU_ChassisType "VehCfgBu3_Pkt";
BA_ "FlexKomSigLaenge" SG_ 1006 VC_BU_ChassisType 64;
BA_ "FlexKomSID" SG_ 1006 VC_BU_ChassisType 921;
BA_ "FlexKomIsMotorola" SG_ 1006 VC_BU_ChassisType 1;
BA_ "FlexKomComment" SG_ 1006 VC_BU_ChassisType "Vehicle Configuration Backup 3 Packet";
BA_ "GenSigSNA" SG_ 1006 VC_BU_TEMP_DISP "0h";
BA_ "GenSigSendType" SG_ 1006 VC_BU_TEMP_DISP 1;
BA_ "FlexKomSigStartValue" SG_ 1006 VC_BU_TEMP_DISP "0370FF037FFF0000h";
BA_ "FlexKomSigStartPos" SG_ 1006 VC_BU_TEMP_DISP 7;
BA_ "FlexKomSigName" SG_ 1006 VC_BU_TEMP_DISP "VehCfgBu3_Pkt";
BA_ "FlexKomSigLaenge" SG_ 1006 VC_BU_TEMP_DISP 64;
BA_ "FlexKomSID" SG_ 1006 VC_BU_TEMP_DISP 921;
BA_ "FlexKomIsMotorola" SG_ 1006 VC_BU_TEMP_DISP 1;
BA_ "FlexKomComment" SG_ 1006 VC_BU_TEMP_DISP "Vehicle Configuration Backup 3 Packet";
BA_ "GenSigSNA" SG_ 1006 VC_BU_RKE_PRSNT "0h";
BA_ "GenSigSendType" SG_ 1006 VC_BU_RKE_PRSNT 1;
BA_ "FlexKomSigStartValue" SG_ 1006 VC_BU_RKE_PRSNT "0370FF037FFF0000h";
BA_ "FlexKomSigStartPos" SG_ 1006 VC_BU_RKE_PRSNT 7;
BA_ "FlexKomSigName" SG_ 1006 VC_BU_RKE_PRSNT "VehCfgBu3_Pkt";
BA_ "FlexKomSigLaenge" SG_ 1006 VC_BU_RKE_PRSNT 64;
BA_ "FlexKomSID" SG_ 1006 VC_BU_RKE_PRSNT 921;
BA_ "FlexKomIsMotorola" SG_ 1006 VC_BU_RKE_PRSNT 1;
BA_ "FlexKomComment" SG_ 1006 VC_BU_RKE_PRSNT "Vehicle Configuration Backup 3 Packet";
BA_ "GenSigSNA" SG_ 1006 VC_BU_SunShade_Present "0h";
BA_ "GenSigSendType" SG_ 1006 VC_BU_SunShade_Present 1;
BA_ "FlexKomSigStartValue" SG_ 1006 VC_BU_SunShade_Present "0370FF037FFF0000h";
BA_ "FlexKomSigStartPos" SG_ 1006 VC_BU_SunShade_Present 7;
BA_ "FlexKomSigName" SG_ 1006 VC_BU_SunShade_Present "VehCfgBu3_Pkt";
BA_ "FlexKomSigLaenge" SG_ 1006 VC_BU_SunShade_Present 64;
BA_ "FlexKomSID" SG_ 1006 VC_BU_SunShade_Present 921;
BA_ "FlexKomIsMotorola" SG_ 1006 VC_BU_SunShade_Present 1;
BA_ "FlexKomComment" SG_ 1006 VC_BU_SunShade_Present "Vehicle Configuration Backup 3 Packet";
BA_ "GenSigSNA" SG_ 1006 VC_BU_PWR_LFT_GT "0h";
BA_ "GenSigSendType" SG_ 1006 VC_BU_PWR_LFT_GT 1;
BA_ "FlexKomSigStartValue" SG_ 1006 VC_BU_PWR_LFT_GT "0370FF037FFF0000h";
BA_ "FlexKomSigStartPos" SG_ 1006 VC_BU_PWR_LFT_GT 7;
BA_ "FlexKomSigName" SG_ 1006 VC_BU_PWR_LFT_GT "VehCfgBu3_Pkt";
BA_ "FlexKomSigLaenge" SG_ 1006 VC_BU_PWR_LFT_GT 64;
BA_ "FlexKomSID" SG_ 1006 VC_BU_PWR_LFT_GT 921;
BA_ "FlexKomIsMotorola" SG_ 1006 VC_BU_PWR_LFT_GT 1;
BA_ "FlexKomComment" SG_ 1006 VC_BU_PWR_LFT_GT "Vehicle Configuration Backup 3 Packet";
BA_ "GenSigSNA" SG_ 1006 VC_BU_PWR_RT_SLDR "0h";
BA_ "GenSigSendType" SG_ 1006 VC_BU_PWR_RT_SLDR 1;
BA_ "FlexKomSigStartValue" SG_ 1006 VC_BU_PWR_RT_SLDR "0370FF037FFF0000h";
BA_ "FlexKomSigStartPos" SG_ 1006 VC_BU_PWR_RT_SLDR 7;
BA_ "FlexKomSigName" SG_ 1006 VC_BU_PWR_RT_SLDR "VehCfgBu3_Pkt";
BA_ "FlexKomSigLaenge" SG_ 1006 VC_BU_PWR_RT_SLDR 64;
BA_ "FlexKomSID" SG_ 1006 VC_BU_PWR_RT_SLDR 921;
BA_ "FlexKomIsMotorola" SG_ 1006 VC_BU_PWR_RT_SLDR 1;
BA_ "FlexKomComment" SG_ 1006 VC_BU_PWR_RT_SLDR "Vehicle Configuration Backup 3 Packet";
BA_ "GenSigStartValue" SG_ 1006 VC_BU_VehCfg3_Stat 3;
BA_ "GenSigSNA" SG_ 1006 VC_BU_VehCfg3_Stat "3h";
BA_ "GenSigSendType" SG_ 1006 VC_BU_VehCfg3_Stat 1;
BA_ "FlexKomSigStartValue" SG_ 1006 VC_BU_VehCfg3_Stat "0370FF037FFF0000h";
BA_ "FlexKomSigStartPos" SG_ 1006 VC_BU_VehCfg3_Stat 7;
BA_ "FlexKomSigName" SG_ 1006 VC_BU_VehCfg3_Stat "VehCfgBu3_Pkt";
BA_ "FlexKomSigLaenge" SG_ 1006 VC_BU_VehCfg3_Stat 64;
BA_ "FlexKomSID" SG_ 1006 VC_BU_VehCfg3_Stat 921;
BA_ "FlexKomIsMotorola" SG_ 1006 VC_BU_VehCfg3_Stat 1;
BA_ "FlexKomComment" SG_ 1006 VC_BU_VehCfg3_Stat "Vehicle Configuration Backup 3 Packet";
BA_ "GenSigSNA" SG_ 1006 VC_BU_POLICE "0h";
BA_ "GenSigSendType" SG_ 1006 VC_BU_POLICE 1;
BA_ "FlexKomSigStartValue" SG_ 1006 VC_BU_POLICE "0370FF037FFF0000h";
BA_ "FlexKomSigStartPos" SG_ 1006 VC_BU_POLICE 7;
BA_ "FlexKomSigName" SG_ 1006 VC_BU_POLICE "VehCfgBu3_Pkt";
BA_ "FlexKomSigLaenge" SG_ 1006 VC_BU_POLICE 64;
BA_ "FlexKomSID" SG_ 1006 VC_BU_POLICE 921;
BA_ "FlexKomIsMotorola" SG_ 1006 VC_BU_POLICE 1;
BA_ "FlexKomComment" SG_ 1006 VC_BU_POLICE "Vehicle Configuration Backup 3 Packet";
BA_ "GenSigSNA" SG_ 1006 VC_BU_PWR_LT_SLDR "0h";
BA_ "GenSigSendType" SG_ 1006 VC_BU_PWR_LT_SLDR 1;
BA_ "FlexKomSigStartValue" SG_ 1006 VC_BU_PWR_LT_SLDR "0370FF037FFF0000h";
BA_ "FlexKomSigStartPos" SG_ 1006 VC_BU_PWR_LT_SLDR 7;
BA_ "FlexKomSigName" SG_ 1006 VC_BU_PWR_LT_SLDR "VehCfgBu3_Pkt";
BA_ "FlexKomSigLaenge" SG_ 1006 VC_BU_PWR_LT_SLDR 64;
BA_ "FlexKomSID" SG_ 1006 VC_BU_PWR_LT_SLDR 921;
BA_ "FlexKomIsMotorola" SG_ 1006 VC_BU_PWR_LT_SLDR 1;
BA_ "FlexKomComment" SG_ 1006 VC_BU_PWR_LT_SLDR "Vehicle Configuration Backup 3 Packet";
BA_ "GenSigStartValue" SG_ 1006 VC_BU_WHL_BASE 3;
BA_ "GenSigSNA" SG_ 1006 VC_BU_WHL_BASE "3h";
BA_ "GenSigSendType" SG_ 1006 VC_BU_WHL_BASE 1;
BA_ "FlexKomSigStartValue" SG_ 1006 VC_BU_WHL_BASE "0370FF037FFF0000h";
BA_ "FlexKomSigStartPos" SG_ 1006 VC_BU_WHL_BASE 7;
BA_ "FlexKomSigName" SG_ 1006 VC_BU_WHL_BASE "VehCfgBu3_Pkt";
BA_ "FlexKomSigLaenge" SG_ 1006 VC_BU_WHL_BASE 64;
BA_ "FlexKomSID" SG_ 1006 VC_BU_WHL_BASE 921;
BA_ "FlexKomIsMotorola" SG_ 1006 VC_BU_WHL_BASE 1;
BA_ "FlexKomComment" SG_ 1006 VC_BU_WHL_BASE "Vehicle Configuration Backup 3 Packet";
BA_ "GenSigSNA" SG_ 1006 VC_BU_AUTO_HL "0h";
BA_ "GenSigSendType" SG_ 1006 VC_BU_AUTO_HL 1;
BA_ "FlexKomSigStartValue" SG_ 1006 VC_BU_AUTO_HL "0370FF037FFF0000h";
BA_ "FlexKomSigStartPos" SG_ 1006 VC_BU_AUTO_HL 7;
BA_ "FlexKomSigName" SG_ 1006 VC_BU_AUTO_HL "VehCfgBu3_Pkt";
BA_ "FlexKomSigLaenge" SG_ 1006 VC_BU_AUTO_HL 64;
BA_ "FlexKomSID" SG_ 1006 VC_BU_AUTO_HL 921;
BA_ "FlexKomIsMotorola" SG_ 1006 VC_BU_AUTO_HL 1;
BA_ "FlexKomComment" SG_ 1006 VC_BU_AUTO_HL "Vehicle Configuration Backup 3 Packet";
BA_ "GenSigStartValue" SG_ 1006 VC_BU_HVAC_Config 15;
BA_ "GenSigSNA" SG_ 1006 VC_BU_HVAC_Config "Fh";
BA_ "GenSigSendType" SG_ 1006 VC_BU_HVAC_Config 1;
BA_ "FlexKomSigStartValue" SG_ 1006 VC_BU_HVAC_Config "0370FF037FFF0000h";
BA_ "FlexKomSigStartPos" SG_ 1006 VC_BU_HVAC_Config 7;
BA_ "FlexKomSigName" SG_ 1006 VC_BU_HVAC_Config "VehCfgBu3_Pkt";
BA_ "FlexKomSigLaenge" SG_ 1006 VC_BU_HVAC_Config 64;
BA_ "FlexKomSID" SG_ 1006 VC_BU_HVAC_Config 921;
BA_ "FlexKomIsMotorola" SG_ 1006 VC_BU_HVAC_Config 1;
BA_ "FlexKomComment" SG_ 1006 VC_BU_HVAC_Config "Vehicle Configuration Backup 3 Packet";
BA_ "GenSigSNA" SG_ 1006 VC_BU_HID_HL "0h";
BA_ "GenSigSendType" SG_ 1006 VC_BU_HID_HL 1;
BA_ "FlexKomSigStartValue" SG_ 1006 VC_BU_HID_HL "0370FF037FFF0000h";
BA_ "FlexKomSigStartPos" SG_ 1006 VC_BU_HID_HL 7;
BA_ "FlexKomSigName" SG_ 1006 VC_BU_HID_HL "VehCfgBu3_Pkt";
BA_ "FlexKomSigLaenge" SG_ 1006 VC_BU_HID_HL 64;
BA_ "FlexKomSID" SG_ 1006 VC_BU_HID_HL 921;
BA_ "FlexKomIsMotorola" SG_ 1006 VC_BU_HID_HL 1;
BA_ "FlexKomComment" SG_ 1006 VC_BU_HID_HL "Vehicle Configuration Backup 3 Packet";
BA_ "GenSigSNA" SG_ 1006 VC_BU_Liftgate_Trunk "3h";
BA_ "GenSigSendType" SG_ 1006 VC_BU_Liftgate_Trunk 1;
BA_ "FlexKomSigStartValue" SG_ 1006 VC_BU_Liftgate_Trunk "0370FF037FFF0000h";
BA_ "FlexKomSigStartPos" SG_ 1006 VC_BU_Liftgate_Trunk 7;
BA_ "FlexKomSigName" SG_ 1006 VC_BU_Liftgate_Trunk "VehCfgBu3_Pkt";
BA_ "FlexKomSigLaenge" SG_ 1006 VC_BU_Liftgate_Trunk 64;
BA_ "FlexKomSID" SG_ 1006 VC_BU_Liftgate_Trunk 921;
BA_ "FlexKomIsMotorola" SG_ 1006 VC_BU_Liftgate_Trunk 1;
BA_ "FlexKomComment" SG_ 1006 VC_BU_Liftgate_Trunk "Vehicle Configuration Backup 3 Packet";
BA_ "GenSigSNA" SG_ 1006 VC_BU_Base_TPM "0h";
BA_ "GenSigSendType" SG_ 1006 VC_BU_Base_TPM 1;
BA_ "FlexKomSigStartValue" SG_ 1006 VC_BU_Base_TPM "0370FF037FFF0000h";
BA_ "FlexKomSigStartPos" SG_ 1006 VC_BU_Base_TPM 7;
BA_ "FlexKomSigName" SG_ 1006 VC_BU_Base_TPM "VehCfgBu3_Pkt";
BA_ "FlexKomSigLaenge" SG_ 1006 VC_BU_Base_TPM 64;
BA_ "FlexKomSID" SG_ 1006 VC_BU_Base_TPM 921;
BA_ "FlexKomIsMotorola" SG_ 1006 VC_BU_Base_TPM 1;
BA_ "FlexKomComment" SG_ 1006 VC_BU_Base_TPM "Vehicle Configuration Backup 3 Packet";
BA_ "GenSigSNA" SG_ 1006 VC_BU_SPORT_PRSNT "0h";
BA_ "GenSigSendType" SG_ 1006 VC_BU_SPORT_PRSNT 1;
BA_ "FlexKomSigStartValue" SG_ 1006 VC_BU_SPORT_PRSNT "0370FF037FFF0000h";
BA_ "FlexKomSigStartPos" SG_ 1006 VC_BU_SPORT_PRSNT 7;
BA_ "FlexKomSigName" SG_ 1006 VC_BU_SPORT_PRSNT "VehCfgBu3_Pkt";
BA_ "FlexKomSigLaenge" SG_ 1006 VC_BU_SPORT_PRSNT 64;
BA_ "FlexKomSID" SG_ 1006 VC_BU_SPORT_PRSNT 921;
BA_ "FlexKomIsMotorola" SG_ 1006 VC_BU_SPORT_PRSNT 1;
BA_ "FlexKomComment" SG_ 1006 VC_BU_SPORT_PRSNT "Vehicle Configuration Backup 3 Packet";
BA_ "GenSigSNA" SG_ 1006 VC_BU_TcaseTyp "0h";
BA_ "GenSigSendType" SG_ 1006 VC_BU_TcaseTyp 1;
BA_ "FlexKomSigStartValue" SG_ 1006 VC_BU_TcaseTyp "0370FF037FFF0000h";
BA_ "FlexKomSigStartPos" SG_ 1006 VC_BU_TcaseTyp 7;
BA_ "FlexKomSigName" SG_ 1006 VC_BU_TcaseTyp "VehCfgBu3_Pkt";
BA_ "FlexKomSigLaenge" SG_ 1006 VC_BU_TcaseTyp 64;
BA_ "FlexKomSID" SG_ 1006 VC_BU_TcaseTyp 921;
BA_ "FlexKomIsMotorola" SG_ 1006 VC_BU_TcaseTyp 1;
BA_ "FlexKomComment" SG_ 1006 VC_BU_TcaseTyp "Vehicle Configuration Backup 3 Packet";
BA_ "GenSigStartValue" SG_ 1006 VC_BU_FOBIKsafeENBL 1;
BA_ "GenSigSNA" SG_ 1006 VC_BU_FOBIKsafeENBL "1h";
BA_ "GenSigSendType" SG_ 1006 VC_BU_FOBIKsafeENBL 1;
BA_ "FlexKomSigStartValue" SG_ 1006 VC_BU_FOBIKsafeENBL "0370FF037FFF0000h";
BA_ "FlexKomSigStartPos" SG_ 1006 VC_BU_FOBIKsafeENBL 7;
BA_ "FlexKomSigName" SG_ 1006 VC_BU_FOBIKsafeENBL "VehCfgBu3_Pkt";
BA_ "FlexKomSigLaenge" SG_ 1006 VC_BU_FOBIKsafeENBL 64;
BA_ "FlexKomSID" SG_ 1006 VC_BU_FOBIKsafeENBL 921;
BA_ "FlexKomIsMotorola" SG_ 1006 VC_BU_FOBIKsafeENBL 1;
BA_ "FlexKomComment" SG_ 1006 VC_BU_FOBIKsafeENBL "Vehicle Configuration Backup 3 Packet";
BA_ "GenSigSNA" SG_ 1006 VC_BU_ELV_PRSNT "0h";
BA_ "GenSigSendType" SG_ 1006 VC_BU_ELV_PRSNT 1;
BA_ "FlexKomSigStartValue" SG_ 1006 VC_BU_ELV_PRSNT "0370FF037FFF0000h";
BA_ "FlexKomSigStartPos" SG_ 1006 VC_BU_ELV_PRSNT 7;
BA_ "FlexKomSigName" SG_ 1006 VC_BU_ELV_PRSNT "VehCfgBu3_Pkt";
BA_ "FlexKomSigLaenge" SG_ 1006 VC_BU_ELV_PRSNT 64;
BA_ "FlexKomSID" SG_ 1006 VC_BU_ELV_PRSNT 921;
BA_ "FlexKomIsMotorola" SG_ 1006 VC_BU_ELV_PRSNT 1;
BA_ "FlexKomComment" SG_ 1006 VC_BU_ELV_PRSNT "Vehicle Configuration Backup 3 Packet";
BA_ "GenSigStartValue" SG_ 1006 VC_BU_FUEL_CAP 255;
BA_ "GenSigSNA" SG_ 1006 VC_BU_FUEL_CAP "FFh";
BA_ "GenSigSendType" SG_ 1006 VC_BU_FUEL_CAP 1;
BA_ "FlexKomSigStartValue" SG_ 1006 VC_BU_FUEL_CAP "0370FF037FFF0000h";
BA_ "FlexKomSigStartPos" SG_ 1006 VC_BU_FUEL_CAP 7;
BA_ "FlexKomSigName" SG_ 1006 VC_BU_FUEL_CAP "VehCfgBu3_Pkt";
BA_ "FlexKomSigLaenge" SG_ 1006 VC_BU_FUEL_CAP 64;
BA_ "FlexKomSID" SG_ 1006 VC_BU_FUEL_CAP 921;
BA_ "FlexKomIsMotorola" SG_ 1006 VC_BU_FUEL_CAP 1;
BA_ "FlexKomComment" SG_ 1006 VC_BU_FUEL_CAP "Vehicle Configuration Backup 3 Packet";
BA_ "GenSigStartValue" SG_ 1006 VC_BU_WIN_EXPR_FEAT 3;
BA_ "GenSigSNA" SG_ 1006 VC_BU_WIN_EXPR_FEAT "3h";
BA_ "GenSigSendType" SG_ 1006 VC_BU_WIN_EXPR_FEAT 1;
BA_ "FlexKomSigStartValue" SG_ 1006 VC_BU_WIN_EXPR_FEAT "0370FF037FFF0000h";
BA_ "FlexKomSigStartPos" SG_ 1006 VC_BU_WIN_EXPR_FEAT 7;
BA_ "FlexKomSigName" SG_ 1006 VC_BU_WIN_EXPR_FEAT "VehCfgBu3_Pkt";
BA_ "FlexKomSigLaenge" SG_ 1006 VC_BU_WIN_EXPR_FEAT 64;
BA_ "FlexKomSID" SG_ 1006 VC_BU_WIN_EXPR_FEAT 921;
BA_ "FlexKomIsMotorola" SG_ 1006 VC_BU_WIN_EXPR_FEAT 1;
BA_ "FlexKomComment" SG_ 1006 VC_BU_WIN_EXPR_FEAT "Vehicle Configuration Backup 3 Packet";
BA_ "GenSigSNA" SG_ 1006 VC_BU_ADJ_PDL_PRSNT "0h";
BA_ "GenSigSendType" SG_ 1006 VC_BU_ADJ_PDL_PRSNT 1;
BA_ "FlexKomSigStartValue" SG_ 1006 VC_BU_ADJ_PDL_PRSNT "0370FF037FFF0000h";
BA_ "FlexKomSigStartPos" SG_ 1006 VC_BU_ADJ_PDL_PRSNT 7;
BA_ "FlexKomSigName" SG_ 1006 VC_BU_ADJ_PDL_PRSNT "VehCfgBu3_Pkt";
BA_ "FlexKomSigLaenge" SG_ 1006 VC_BU_ADJ_PDL_PRSNT 64;
BA_ "FlexKomSID" SG_ 1006 VC_BU_ADJ_PDL_PRSNT 921;
BA_ "FlexKomIsMotorola" SG_ 1006 VC_BU_ADJ_PDL_PRSNT 1;
BA_ "FlexKomComment" SG_ 1006 VC_BU_ADJ_PDL_PRSNT "Vehicle Configuration Backup 3 Packet";
BA_ "GenSigStartValue" SG_ 1007 VC_BU_TCASE_HI_RATIO 16383;
BA_ "GenSigSNA" SG_ 1007 VC_BU_TCASE_HI_RATIO "3FFFh";
BA_ "GenSigSendType" SG_ 1007 VC_BU_TCASE_HI_RATIO 1;
BA_ "FlexKomSigStartValue" SG_ 1007 VC_BU_TCASE_HI_RATIO "FFFFFFFFFFFFFFFFh";
BA_ "FlexKomSigStartPos" SG_ 1007 VC_BU_TCASE_HI_RATIO 7;
BA_ "FlexKomSigName" SG_ 1007 VC_BU_TCASE_HI_RATIO "VehCfgBu4_Pkt";
BA_ "FlexKomSigLaenge" SG_ 1007 VC_BU_TCASE_HI_RATIO 64;
BA_ "FlexKomSID" SG_ 1007 VC_BU_TCASE_HI_RATIO 1036;
BA_ "FlexKomIsMotorola" SG_ 1007 VC_BU_TCASE_HI_RATIO 1;
BA_ "FlexKomComment" SG_ 1007 VC_BU_TCASE_HI_RATIO "Vehicle Configuration Backup 4 Packet";
BA_ "GenSigStartValue" SG_ 1007 VC_BU_VehCfg4_Stat 3;
BA_ "GenSigSNA" SG_ 1007 VC_BU_VehCfg4_Stat "3h";
BA_ "GenSigSendType" SG_ 1007 VC_BU_VehCfg4_Stat 1;
BA_ "FlexKomSigStartValue" SG_ 1007 VC_BU_VehCfg4_Stat "FFFFFFFFFFFFFFFFh";
BA_ "FlexKomSigStartPos" SG_ 1007 VC_BU_VehCfg4_Stat 7;
BA_ "FlexKomSigName" SG_ 1007 VC_BU_VehCfg4_Stat "VehCfgBu4_Pkt";
BA_ "FlexKomSigLaenge" SG_ 1007 VC_BU_VehCfg4_Stat 64;
BA_ "FlexKomSID" SG_ 1007 VC_BU_VehCfg4_Stat 1036;
BA_ "FlexKomIsMotorola" SG_ 1007 VC_BU_VehCfg4_Stat 1;
BA_ "FlexKomComment" SG_ 1007 VC_BU_VehCfg4_Stat "Vehicle Configuration Backup 4 Packet";
BA_ "GenSigStartValue" SG_ 1007 VC_BU_AXLE_RATIO 65535;
BA_ "GenSigSNA" SG_ 1007 VC_BU_AXLE_RATIO "FFFFh";
BA_ "GenSigSendType" SG_ 1007 VC_BU_AXLE_RATIO 1;
BA_ "FlexKomSigStartValue" SG_ 1007 VC_BU_AXLE_RATIO "FFFFFFFFFFFFFFFFh";
BA_ "FlexKomSigStartPos" SG_ 1007 VC_BU_AXLE_RATIO 7;
BA_ "FlexKomSigName" SG_ 1007 VC_BU_AXLE_RATIO "VehCfgBu4_Pkt";
BA_ "FlexKomSigLaenge" SG_ 1007 VC_BU_AXLE_RATIO 64;
BA_ "FlexKomSID" SG_ 1007 VC_BU_AXLE_RATIO 1036;
BA_ "FlexKomIsMotorola" SG_ 1007 VC_BU_AXLE_RATIO 1;
BA_ "FlexKomComment" SG_ 1007 VC_BU_AXLE_RATIO "Vehicle Configuration Backup 4 Packet";
BA_ "GenSigStartValue" SG_ 1007 VC_BU_TIRE_CIRCUMF 65535;
BA_ "GenSigSNA" SG_ 1007 VC_BU_TIRE_CIRCUMF "FFFFh";
BA_ "GenSigSendType" SG_ 1007 VC_BU_TIRE_CIRCUMF 1;
BA_ "FlexKomSigStartValue" SG_ 1007 VC_BU_TIRE_CIRCUMF "FFFFFFFFFFFFFFFFh";
BA_ "FlexKomSigStartPos" SG_ 1007 VC_BU_TIRE_CIRCUMF 7;
BA_ "FlexKomSigName" SG_ 1007 VC_BU_TIRE_CIRCUMF "VehCfgBu4_Pkt";
BA_ "FlexKomSigLaenge" SG_ 1007 VC_BU_TIRE_CIRCUMF 64;
BA_ "FlexKomSID" SG_ 1007 VC_BU_TIRE_CIRCUMF 1036;
BA_ "FlexKomIsMotorola" SG_ 1007 VC_BU_TIRE_CIRCUMF 1;
BA_ "FlexKomComment" SG_ 1007 VC_BU_TIRE_CIRCUMF "Vehicle Configuration Backup 4 Packet";
BA_ "GenSigStartValue" SG_ 1007 VC_BU_TCASE_LO_RATIO 65535;
BA_ "GenSigSNA" SG_ 1007 VC_BU_TCASE_LO_RATIO "FFFFh";
BA_ "GenSigSendType" SG_ 1007 VC_BU_TCASE_LO_RATIO 1;
BA_ "FlexKomSigStartValue" SG_ 1007 VC_BU_TCASE_LO_RATIO "FFFFFFFFFFFFFFFFh";
BA_ "FlexKomSigStartPos" SG_ 1007 VC_BU_TCASE_LO_RATIO 7;
BA_ "FlexKomSigName" SG_ 1007 VC_BU_TCASE_LO_RATIO "VehCfgBu4_Pkt";
BA_ "FlexKomSigLaenge" SG_ 1007 VC_BU_TCASE_LO_RATIO 64;
BA_ "FlexKomSID" SG_ 1007 VC_BU_TCASE_LO_RATIO 1036;
BA_ "FlexKomIsMotorola" SG_ 1007 VC_BU_TCASE_LO_RATIO 1;
BA_ "FlexKomComment" SG_ 1007 VC_BU_TCASE_LO_RATIO "Vehicle Configuration Backup 4 Packet";
BA_ "GenSigSNA" SG_ 1008 EC_CBC1A "0h";
BA_ "GenSigCycleTime" SG_ 1008 EC_CBC1A 2000;
BA_ "FlexKomSigStartValue" SG_ 1008 EC_CBC1A "00000000h";
BA_ "FlexKomSigStartPos" SG_ 1008 EC_CBC1A 7;
BA_ "FlexKomSigName" SG_ 1008 EC_CBC1A "EC_CBC1";
BA_ "FlexKomSigLaenge" SG_ 1008 EC_CBC1A 32;
BA_ "FlexKomSID" SG_ 1008 EC_CBC1A 899;
BA_ "FlexKomIsMotorola" SG_ 1008 EC_CBC1A 1;
BA_ "FlexKomComment" SG_ 1008 EC_CBC1A "CBC ecu configuration 1";
BA_ "GenSigSNA" SG_ 1008 EC_CBC1B "0h";
BA_ "GenSigCycleTime" SG_ 1008 EC_CBC1B 2000;
BA_ "FlexKomSigStartValue" SG_ 1008 EC_CBC1B "00000000h";
BA_ "FlexKomSigStartPos" SG_ 1008 EC_CBC1B 7;
BA_ "FlexKomSigName" SG_ 1008 EC_CBC1B "EC_CBC1";
BA_ "FlexKomSigLaenge" SG_ 1008 EC_CBC1B 32;
BA_ "FlexKomSID" SG_ 1008 EC_CBC1B 899;
BA_ "FlexKomIsMotorola" SG_ 1008 EC_CBC1B 1;
BA_ "FlexKomComment" SG_ 1008 EC_CBC1B "CBC ecu configuration 1";
BA_ "GenSigSNA" SG_ 1008 EC_CBC2 "0h";
BA_ "GenSigCycleTime" SG_ 1008 EC_CBC2 2000;
BA_ "FlexKomSigStartValue" SG_ 1008 EC_CBC2 "00000000h";
BA_ "FlexKomSigStartPos" SG_ 1008 EC_CBC2 39;
BA_ "FlexKomSigName" SG_ 1008 EC_CBC2 "EC_CBC2";
BA_ "FlexKomSigLaenge" SG_ 1008 EC_CBC2 32;
BA_ "FlexKomSID" SG_ 1008 EC_CBC2 900;
BA_ "FlexKomIsMotorola" SG_ 1008 EC_CBC2 1;
BA_ "FlexKomComment" SG_ 1008 EC_CBC2 "CBC ecu configuration 2";
BA_ "GenSigStartValue" SG_ 1008 EC_ECUCfg1_Stat 3;
BA_ "GenSigSNA" SG_ 1008 EC_ECUCfg1_Stat "3h";
BA_ "GenSigCycleTime" SG_ 1008 EC_ECUCfg1_Stat 2000;
BA_ "FlexKomSigStartValue" SG_ 1008 EC_ECUCfg1_Stat "03h";
BA_ "FlexKomSigStartPos" SG_ 1008 EC_ECUCfg1_Stat 1;
BA_ "FlexKomSigName" SG_ 1008 EC_ECUCfg1_Stat "EC_ECUCfg1_Stat";
BA_ "FlexKomSigLaenge" SG_ 1008 EC_ECUCfg1_Stat 2;
BA_ "FlexKomSID" SG_ 1008 EC_ECUCfg1_Stat 1058;
BA_ "FlexKomIsMotorola" SG_ 1008 EC_ECUCfg1_Stat 1;
BA_ "FlexKomComment" SG_ 1008 EC_ECUCfg1_Stat "ECU Configuration messages status 1";
BA_ "GenSigStartValue" SG_ 1009 EC_ECUCfg2_Stat 3;
BA_ "GenSigSNA" SG_ 1009 EC_ECUCfg2_Stat "3h";
BA_ "GenSigCycleTime" SG_ 1009 EC_ECUCfg2_Stat 2000;
BA_ "FlexKomSigStartValue" SG_ 1009 EC_ECUCfg2_Stat "03h";
BA_ "FlexKomSigStartPos" SG_ 1009 EC_ECUCfg2_Stat 1;
BA_ "FlexKomSigName" SG_ 1009 EC_ECUCfg2_Stat "EC_ECUCfg2_Stat";
BA_ "FlexKomSigLaenge" SG_ 1009 EC_ECUCfg2_Stat 2;
BA_ "FlexKomSID" SG_ 1009 EC_ECUCfg2_Stat 1059;
BA_ "FlexKomIsMotorola" SG_ 1009 EC_ECUCfg2_Stat 1;
BA_ "FlexKomComment" SG_ 1009 EC_ECUCfg2_Stat "ECU Configuration messages status 2";
BA_ "GenSigSNA" SG_ 1009 EC_CBC3A "0h";
BA_ "GenSigCycleTime" SG_ 1009 EC_CBC3A 2000;
BA_ "FlexKomSigStartValue" SG_ 1009 EC_CBC3A "00000000h";
BA_ "FlexKomSigStartPos" SG_ 1009 EC_CBC3A 7;
BA_ "FlexKomSigName" SG_ 1009 EC_CBC3A "EC_CBC3";
BA_ "FlexKomSigLaenge" SG_ 1009 EC_CBC3A 32;
BA_ "FlexKomSID" SG_ 1009 EC_CBC3A 901;
BA_ "FlexKomIsMotorola" SG_ 1009 EC_CBC3A 1;
BA_ "FlexKomComment" SG_ 1009 EC_CBC3A "CBC ecu configuration 3";
BA_ "GenSigSNA" SG_ 1009 EC_CBC3B "0h";
BA_ "GenSigCycleTime" SG_ 1009 EC_CBC3B 2000;
BA_ "FlexKomSigStartValue" SG_ 1009 EC_CBC3B "00000000h";
BA_ "FlexKomSigStartPos" SG_ 1009 EC_CBC3B 7;
BA_ "FlexKomSigName" SG_ 1009 EC_CBC3B "EC_CBC3";
BA_ "FlexKomSigLaenge" SG_ 1009 EC_CBC3B 32;
BA_ "FlexKomSID" SG_ 1009 EC_CBC3B 901;
BA_ "FlexKomIsMotorola" SG_ 1009 EC_CBC3B 1;
BA_ "FlexKomComment" SG_ 1009 EC_CBC3B "CBC ecu configuration 3";
BA_ "GenSigSNA" SG_ 1009 EC_CBC4 "0h";
BA_ "GenSigCycleTime" SG_ 1009 EC_CBC4 2000;
BA_ "FlexKomSigStartValue" SG_ 1009 EC_CBC4 "00000000h";
BA_ "FlexKomSigStartPos" SG_ 1009 EC_CBC4 39;
BA_ "FlexKomSigName" SG_ 1009 EC_CBC4 "EC_CBC4";
BA_ "FlexKomSigLaenge" SG_ 1009 EC_CBC4 32;
BA_ "FlexKomSID" SG_ 1009 EC_CBC4 902;
BA_ "FlexKomIsMotorola" SG_ 1009 EC_CBC4 1;
BA_ "FlexKomComment" SG_ 1009 EC_CBC4 "CBC ecu configuration 4";
BA_ "GenSigSNA" SG_ 1010 EC_AudTel1A "0h";
BA_ "GenSigSendType" SG_ 1010 EC_AudTel1A 5;
BA_ "GenSigCycleTime" SG_ 1010 EC_AudTel1A 2000;
BA_ "FlexKomSigStartValue" SG_ 1010 EC_AudTel1A "00000000h";
BA_ "FlexKomSigStartPos" SG_ 1010 EC_AudTel1A 7;
BA_ "FlexKomSigName" SG_ 1010 EC_AudTel1A "EC_AudTel1";
BA_ "FlexKomSigLaenge" SG_ 1010 EC_AudTel1A 32;
BA_ "FlexKomSID" SG_ 1010 EC_AudTel1A 897;
BA_ "FlexKomIsMotorola" SG_ 1010 EC_AudTel1A 1;
BA_ "FlexKomComment" SG_ 1010 EC_AudTel1A "Audio and telematics ecu configuration 1";
BA_ "GenSigSNA" SG_ 1010 EC_AudTel1B "0h";
BA_ "GenSigSendType" SG_ 1010 EC_AudTel1B 5;
BA_ "GenSigCycleTime" SG_ 1010 EC_AudTel1B 2000;
BA_ "FlexKomSigStartValue" SG_ 1010 EC_AudTel1B "00000000h";
BA_ "FlexKomSigStartPos" SG_ 1010 EC_AudTel1B 7;
BA_ "FlexKomSigName" SG_ 1010 EC_AudTel1B "EC_AudTel1";
BA_ "FlexKomSigLaenge" SG_ 1010 EC_AudTel1B 32;
BA_ "FlexKomSID" SG_ 1010 EC_AudTel1B 897;
BA_ "FlexKomIsMotorola" SG_ 1010 EC_AudTel1B 1;
BA_ "FlexKomComment" SG_ 1010 EC_AudTel1B "Audio and telematics ecu configuration 1";
BA_ "GenSigStartValue" SG_ 1010 EC_ECUCfg3_Stat 3;
BA_ "GenSigSNA" SG_ 1010 EC_ECUCfg3_Stat "3h";
BA_ "GenSigSendType" SG_ 1010 EC_ECUCfg3_Stat 5;
BA_ "GenSigCycleTime" SG_ 1010 EC_ECUCfg3_Stat 2000;
BA_ "FlexKomSigStartValue" SG_ 1010 EC_ECUCfg3_Stat "03h";
BA_ "FlexKomSigStartPos" SG_ 1010 EC_ECUCfg3_Stat 1;
BA_ "FlexKomSigName" SG_ 1010 EC_ECUCfg3_Stat "EC_ECUCfg3_Stat";
BA_ "FlexKomSigLaenge" SG_ 1010 EC_ECUCfg3_Stat 2;
BA_ "FlexKomSID" SG_ 1010 EC_ECUCfg3_Stat 1060;
BA_ "FlexKomIsMotorola" SG_ 1010 EC_ECUCfg3_Stat 1;
BA_ "FlexKomComment" SG_ 1010 EC_ECUCfg3_Stat "ECU Configuration messages status 3";
BA_ "GenSigSNA" SG_ 1010 EC_AudTel2 "0h";
BA_ "GenSigSendType" SG_ 1010 EC_AudTel2 5;
BA_ "GenSigCycleTime" SG_ 1010 EC_AudTel2 2000;
BA_ "FlexKomSigStartValue" SG_ 1010 EC_AudTel2 "00000000h";
BA_ "FlexKomSigStartPos" SG_ 1010 EC_AudTel2 39;
BA_ "FlexKomSigName" SG_ 1010 EC_AudTel2 "EC_AudTel2";
BA_ "FlexKomSigLaenge" SG_ 1010 EC_AudTel2 32;
BA_ "FlexKomSID" SG_ 1010 EC_AudTel2 898;
BA_ "FlexKomIsMotorola" SG_ 1010 EC_AudTel2 1;
BA_ "FlexKomComment" SG_ 1010 EC_AudTel2 "Audio and telematics ecu configuration 2";
BA_ "GenSigTimeout_IC" SG_ 1011 EC_ECUCfg4_Stat 21000;
BA_ "GenSigStartValue" SG_ 1011 EC_ECUCfg4_Stat 3;
BA_ "GenSigSNA" SG_ 1011 EC_ECUCfg4_Stat "3h";
BA_ "GenSigSendType" SG_ 1011 EC_ECUCfg4_Stat 5;
BA_ "GenSigCycleTime" SG_ 1011 EC_ECUCfg4_Stat 2000;
BA_ "FlexKomSigStartValue" SG_ 1011 EC_ECUCfg4_Stat "03h";
BA_ "FlexKomSigStartPos" SG_ 1011 EC_ECUCfg4_Stat 1;
BA_ "FlexKomSigName" SG_ 1011 EC_ECUCfg4_Stat "EC_ECUCfg4_Stat";
BA_ "FlexKomSigLaenge" SG_ 1011 EC_ECUCfg4_Stat 2;
BA_ "FlexKomSID" SG_ 1011 EC_ECUCfg4_Stat 1061;
BA_ "FlexKomIsMotorola" SG_ 1011 EC_ECUCfg4_Stat 1;
BA_ "FlexKomComment" SG_ 1011 EC_ECUCfg4_Stat "ECU Configuration messages status 4";
BA_ "GenSigTimeout_IC" SG_ 1011 EC_Cluster1A 21000;
BA_ "GenSigSNA" SG_ 1011 EC_Cluster1A "0h";
BA_ "GenSigSendType" SG_ 1011 EC_Cluster1A 5;
BA_ "GenSigCycleTime" SG_ 1011 EC_Cluster1A 2000;
BA_ "FlexKomSigStartValue" SG_ 1011 EC_Cluster1A "00000000h";
BA_ "FlexKomSigStartPos" SG_ 1011 EC_Cluster1A 7;
BA_ "FlexKomSigName" SG_ 1011 EC_Cluster1A "EC_Cluster1";
BA_ "FlexKomSigLaenge" SG_ 1011 EC_Cluster1A 32;
BA_ "FlexKomSID" SG_ 1011 EC_Cluster1A 896;
BA_ "FlexKomIsMotorola" SG_ 1011 EC_Cluster1A 1;
BA_ "FlexKomComment" SG_ 1011 EC_Cluster1A "Instrument cluster ecu configuration 1";
BA_ "GenSigTimeout_IC" SG_ 1011 EC_Cluster1B 21000;
BA_ "GenSigSNA" SG_ 1011 EC_Cluster1B "0h";
BA_ "GenSigSendType" SG_ 1011 EC_Cluster1B 5;
BA_ "GenSigCycleTime" SG_ 1011 EC_Cluster1B 2000;
BA_ "FlexKomSigStartValue" SG_ 1011 EC_Cluster1B "00000000h";
BA_ "FlexKomSigStartPos" SG_ 1011 EC_Cluster1B 7;
BA_ "FlexKomSigName" SG_ 1011 EC_Cluster1B "EC_Cluster1";
BA_ "FlexKomSigLaenge" SG_ 1011 EC_Cluster1B 32;
BA_ "FlexKomSID" SG_ 1011 EC_Cluster1B 896;
BA_ "FlexKomIsMotorola" SG_ 1011 EC_Cluster1B 1;
BA_ "FlexKomComment" SG_ 1011 EC_Cluster1B "Instrument cluster ecu configuration 1";
BA_ "GenSigTimeout_IC" SG_ 1011 EC_Cluster2 21000;
BA_ "GenSigSNA" SG_ 1011 EC_Cluster2 "0h";
BA_ "GenSigSendType" SG_ 1011 EC_Cluster2 5;
BA_ "GenSigCycleTime" SG_ 1011 EC_Cluster2 2000;
BA_ "FlexKomSigStartValue" SG_ 1011 EC_Cluster2 "00000000h";
BA_ "FlexKomSigStartPos" SG_ 1011 EC_Cluster2 39;
BA_ "FlexKomSigName" SG_ 1011 EC_Cluster2 "EC_Cluster2";
BA_ "FlexKomSigLaenge" SG_ 1011 EC_Cluster2 32;
BA_ "FlexKomSID" SG_ 1011 EC_Cluster2 903;
BA_ "FlexKomIsMotorola" SG_ 1011 EC_Cluster2 1;
BA_ "FlexKomComment" SG_ 1011 EC_Cluster2 "Instrument cluster ecu configuration 2";
BA_ "GenSigSNA" SG_ 1012 EC_WirelessB "0h";
BA_ "GenSigSendType" SG_ 1012 EC_WirelessB 5;
BA_ "GenSigCycleTime" SG_ 1012 EC_WirelessB 2000;
BA_ "FlexKomSigStartValue" SG_ 1012 EC_WirelessB "000000h";
BA_ "FlexKomSigStartPos" SG_ 1012 EC_WirelessB 7;
BA_ "FlexKomSigName" SG_ 1012 EC_WirelessB "EC_Wireless";
BA_ "FlexKomSigLaenge" SG_ 1012 EC_WirelessB 24;
BA_ "FlexKomSID" SG_ 1012 EC_WirelessB 895;
BA_ "FlexKomIsMotorola" SG_ 1012 EC_WirelessB 1;
BA_ "FlexKomComment" SG_ 1012 EC_WirelessB "Wireless ecu configuration";
BA_ "GenSigSNA" SG_ 1012 EC_Doors "0h";
BA_ "GenSigSendType" SG_ 1012 EC_Doors 5;
BA_ "GenSigCycleTime" SG_ 1012 EC_Doors 2000;
BA_ "FlexKomSigStartValue" SG_ 1012 EC_Doors "000000h";
BA_ "FlexKomSigStartPos" SG_ 1012 EC_Doors 31;
BA_ "FlexKomSigName" SG_ 1012 EC_Doors "EC_Doors";
BA_ "FlexKomSigLaenge" SG_ 1012 EC_Doors 24;
BA_ "FlexKomSID" SG_ 1012 EC_Doors 893;
BA_ "FlexKomIsMotorola" SG_ 1012 EC_Doors 1;
BA_ "FlexKomComment" SG_ 1012 EC_Doors "Doors ecu configuration";
BA_ "GenSigStartValue" SG_ 1012 EC_ECUCfg5_Stat 3;
BA_ "GenSigSNA" SG_ 1012 EC_ECUCfg5_Stat "3h";
BA_ "GenSigSendType" SG_ 1012 EC_ECUCfg5_Stat 5;
BA_ "GenSigCycleTime" SG_ 1012 EC_ECUCfg5_Stat 2000;
BA_ "FlexKomSigStartValue" SG_ 1012 EC_ECUCfg5_Stat "03h";
BA_ "FlexKomSigStartPos" SG_ 1012 EC_ECUCfg5_Stat 1;
BA_ "FlexKomSigName" SG_ 1012 EC_ECUCfg5_Stat "EC_ECUCfg5_Stat";
BA_ "FlexKomSigLaenge" SG_ 1012 EC_ECUCfg5_Stat 2;
BA_ "FlexKomSID" SG_ 1012 EC_ECUCfg5_Stat 1062;
BA_ "FlexKomIsMotorola" SG_ 1012 EC_ECUCfg5_Stat 1;
BA_ "FlexKomComment" SG_ 1012 EC_ECUCfg5_Stat "ECU Configuration messages status 5";
BA_ "GenSigSNA" SG_ 1012 EC_WirelessA "0h";
BA_ "GenSigSendType" SG_ 1012 EC_WirelessA 5;
BA_ "GenSigCycleTime" SG_ 1012 EC_WirelessA 2000;
BA_ "FlexKomSigStartValue" SG_ 1012 EC_WirelessA "000000h";
BA_ "FlexKomSigStartPos" SG_ 1012 EC_WirelessA 7;
BA_ "FlexKomSigName" SG_ 1012 EC_WirelessA "EC_Wireless";
BA_ "FlexKomSigLaenge" SG_ 1012 EC_WirelessA 24;
BA_ "FlexKomSID" SG_ 1012 EC_WirelessA 895;
BA_ "FlexKomIsMotorola" SG_ 1012 EC_WirelessA 1;
BA_ "FlexKomComment" SG_ 1012 EC_WirelessA "Wireless ecu configuration";
BA_ "GenSigSNA" SG_ 1012 EC_Memory "0h";
BA_ "GenSigSendType" SG_ 1012 EC_Memory 5;
BA_ "GenSigCycleTime" SG_ 1012 EC_Memory 2000;
BA_ "FlexKomSigStartValue" SG_ 1012 EC_Memory "0000h";
BA_ "FlexKomSigStartPos" SG_ 1012 EC_Memory 55;
BA_ "FlexKomSigName" SG_ 1012 EC_Memory "EC_Memory";
BA_ "FlexKomSigLaenge" SG_ 1012 EC_Memory 16;
BA_ "FlexKomSID" SG_ 1012 EC_Memory 894;
BA_ "FlexKomIsMotorola" SG_ 1012 EC_Memory 1;
BA_ "FlexKomComment" SG_ 1012 EC_Memory "Memory ecu configuration";
BA_ "GenSigTimeout_ORC" SG_ 1013 EC_Safety 7000;
BA_ "GenSigSNA" SG_ 1013 EC_Safety "0h";
BA_ "GenSigSendType" SG_ 1013 EC_Safety 5;
BA_ "GenSigCycleTime" SG_ 1013 EC_Safety 2000;
BA_ "FlexKomSigStartValue" SG_ 1013 EC_Safety "0000h";
BA_ "FlexKomSigStartPos" SG_ 1013 EC_Safety 55;
BA_ "FlexKomSigName" SG_ 1013 EC_Safety "EC_Safety";
BA_ "FlexKomSigLaenge" SG_ 1013 EC_Safety 16;
BA_ "FlexKomSID" SG_ 1013 EC_Safety 892;
BA_ "FlexKomIsMotorola" SG_ 1013 EC_Safety 1;
BA_ "FlexKomComment" SG_ 1013 EC_Safety "Safety ecu configuration";
BA_ "GenSigSNA" SG_ 1013 EC_BrakesB "0h";
BA_ "GenSigSendType" SG_ 1013 EC_BrakesB 5;
BA_ "GenSigCycleTime" SG_ 1013 EC_BrakesB 2000;
BA_ "FlexKomSigStartValue" SG_ 1013 EC_BrakesB "0000h";
BA_ "FlexKomSigStartPos" SG_ 1013 EC_BrakesB 7;
BA_ "FlexKomSigName" SG_ 1013 EC_BrakesB "EC_Brakes";
BA_ "FlexKomSigLaenge" SG_ 1013 EC_BrakesB 16;
BA_ "FlexKomSID" SG_ 1013 EC_BrakesB 889;
BA_ "FlexKomIsMotorola" SG_ 1013 EC_BrakesB 1;
BA_ "FlexKomComment" SG_ 1013 EC_BrakesB "Brake system ecu configuration";
BA_ "GenSigTimeout_ORC" SG_ 1013 EC_Steering 7000;
BA_ "GenSigSNA" SG_ 1013 EC_Steering "0h";
BA_ "GenSigSendType" SG_ 1013 EC_Steering 5;
BA_ "GenSigCycleTime" SG_ 1013 EC_Steering 2000;
BA_ "FlexKomSigStartValue" SG_ 1013 EC_Steering "0000h";
BA_ "FlexKomSigStartPos" SG_ 1013 EC_Steering 23;
BA_ "FlexKomSigName" SG_ 1013 EC_Steering "EC_Steering";
BA_ "FlexKomSigLaenge" SG_ 1013 EC_Steering 16;
BA_ "FlexKomSID" SG_ 1013 EC_Steering 1982;
BA_ "FlexKomIsMotorola" SG_ 1013 EC_Steering 1;
BA_ "FlexKomComment" SG_ 1013 EC_Steering "Steering ecu configuration";
BA_ "GenSigTimeout_ORC" SG_ 1013 EC_ECUCfg6_Stat 7000;
BA_ "GenSigStartValue" SG_ 1013 EC_ECUCfg6_Stat 3;
BA_ "GenSigSNA" SG_ 1013 EC_ECUCfg6_Stat "3h";
BA_ "GenSigSendType" SG_ 1013 EC_ECUCfg6_Stat 5;
BA_ "GenSigCycleTime" SG_ 1013 EC_ECUCfg6_Stat 2000;
BA_ "FlexKomSigStartValue" SG_ 1013 EC_ECUCfg6_Stat "03h";
BA_ "FlexKomSigStartPos" SG_ 1013 EC_ECUCfg6_Stat 1;
BA_ "FlexKomSigName" SG_ 1013 EC_ECUCfg6_Stat "EC_ECUCfg6_Stat";
BA_ "FlexKomSigLaenge" SG_ 1013 EC_ECUCfg6_Stat 2;
BA_ "FlexKomSID" SG_ 1013 EC_ECUCfg6_Stat 1063;
BA_ "FlexKomIsMotorola" SG_ 1013 EC_ECUCfg6_Stat 1;
BA_ "FlexKomComment" SG_ 1013 EC_ECUCfg6_Stat "ECU Configuration messages status 6";
BA_ "GenSigSNA" SG_ 1013 EC_BrakesA "0h";
BA_ "GenSigSendType" SG_ 1013 EC_BrakesA 5;
BA_ "GenSigCycleTime" SG_ 1013 EC_BrakesA 2000;
BA_ "FlexKomSigStartValue" SG_ 1013 EC_BrakesA "0000h";
BA_ "FlexKomSigStartPos" SG_ 1013 EC_BrakesA 7;
BA_ "FlexKomSigName" SG_ 1013 EC_BrakesA "EC_Brakes";
BA_ "FlexKomSigLaenge" SG_ 1013 EC_BrakesA 16;
BA_ "FlexKomSID" SG_ 1013 EC_BrakesA 889;
BA_ "FlexKomIsMotorola" SG_ 1013 EC_BrakesA 1;
BA_ "FlexKomComment" SG_ 1013 EC_BrakesA "Brake system ecu configuration";
BA_ "GenSigSNA" SG_ 1013 EC_Powertrain "0h";
BA_ "GenSigSendType" SG_ 1013 EC_Powertrain 5;
BA_ "GenSigCycleTime" SG_ 1013 EC_Powertrain 2000;
BA_ "FlexKomSigStartValue" SG_ 1013 EC_Powertrain "0000h";
BA_ "FlexKomSigStartPos" SG_ 1013 EC_Powertrain 39;
BA_ "FlexKomSigName" SG_ 1013 EC_Powertrain "EC_Powertrain";
BA_ "FlexKomSigLaenge" SG_ 1013 EC_Powertrain 16;
BA_ "FlexKomSID" SG_ 1013 EC_Powertrain 890;
BA_ "FlexKomIsMotorola" SG_ 1013 EC_Powertrain 1;
BA_ "FlexKomComment" SG_ 1013 EC_Powertrain "Powertrain ecu configuration";
BA_ "GenSigStartValue" SG_ 1014 EC_ECUCfg7_Stat 3;
BA_ "GenSigSNA" SG_ 1014 EC_ECUCfg7_Stat "3h";
BA_ "GenSigCycleTime" SG_ 1014 EC_ECUCfg7_Stat 2000;
BA_ "FlexKomSigStartValue" SG_ 1014 EC_ECUCfg7_Stat "03h";
BA_ "FlexKomSigStartPos" SG_ 1014 EC_ECUCfg7_Stat 1;
BA_ "FlexKomSigName" SG_ 1014 EC_ECUCfg7_Stat "EC_ECUCfg7_Stat";
BA_ "FlexKomSigLaenge" SG_ 1014 EC_ECUCfg7_Stat 2;
BA_ "FlexKomSID" SG_ 1014 EC_ECUCfg7_Stat 1102;
BA_ "FlexKomIsMotorola" SG_ 1014 EC_ECUCfg7_Stat 1;
BA_ "FlexKomComment" SG_ 1014 EC_ECUCfg7_Stat "ECU Configuration messages status 7";
BA_ "GenSigSNA" SG_ 1014 EC_CBC5B "0h";
BA_ "GenSigCycleTime" SG_ 1014 EC_CBC5B 2000;
BA_ "FlexKomSigStartValue" SG_ 1014 EC_CBC5B "00000000h";
BA_ "FlexKomSigStartPos" SG_ 1014 EC_CBC5B 7;
BA_ "FlexKomSigName" SG_ 1014 EC_CBC5B "EC_CBC5";
BA_ "FlexKomSigLaenge" SG_ 1014 EC_CBC5B 32;
BA_ "FlexKomSID" SG_ 1014 EC_CBC5B 1105;
BA_ "FlexKomIsMotorola" SG_ 1014 EC_CBC5B 1;
BA_ "FlexKomComment" SG_ 1014 EC_CBC5B "CBC ecu configuration 5";
BA_ "GenSigSNA" SG_ 1014 EC_CBC6 "0h";
BA_ "GenSigCycleTime" SG_ 1014 EC_CBC6 2000;
BA_ "FlexKomSigStartValue" SG_ 1014 EC_CBC6 "00000000h";
BA_ "FlexKomSigStartPos" SG_ 1014 EC_CBC6 39;
BA_ "FlexKomSigName" SG_ 1014 EC_CBC6 "EC_CBC6";
BA_ "FlexKomSigLaenge" SG_ 1014 EC_CBC6 32;
BA_ "FlexKomSID" SG_ 1014 EC_CBC6 1103;
BA_ "FlexKomIsMotorola" SG_ 1014 EC_CBC6 1;
BA_ "FlexKomComment" SG_ 1014 EC_CBC6 "CBC ecu configuration 6";
BA_ "GenSigSNA" SG_ 1014 EC_CBC5A "0h";
BA_ "GenSigCycleTime" SG_ 1014 EC_CBC5A 2000;
BA_ "FlexKomSigStartValue" SG_ 1014 EC_CBC5A "00000000h";
BA_ "FlexKomSigStartPos" SG_ 1014 EC_CBC5A 7;
BA_ "FlexKomSigName" SG_ 1014 EC_CBC5A "EC_CBC5";
BA_ "FlexKomSigLaenge" SG_ 1014 EC_CBC5A 32;
BA_ "FlexKomSID" SG_ 1014 EC_CBC5A 1105;
BA_ "FlexKomIsMotorola" SG_ 1014 EC_CBC5A 1;
BA_ "FlexKomComment" SG_ 1014 EC_CBC5A "CBC ecu configuration 5";
BA_ "GenSigStartValue" SG_ 1015 EC_ECUCfg8_Stat 3;
BA_ "GenSigSNA" SG_ 1015 EC_ECUCfg8_Stat "3h";
BA_ "GenSigCycleTime" SG_ 1015 EC_ECUCfg8_Stat 2000;
BA_ "FlexKomSigStartValue" SG_ 1015 EC_ECUCfg8_Stat "03h";
BA_ "FlexKomSigStartPos" SG_ 1015 EC_ECUCfg8_Stat 1;
BA_ "FlexKomSigName" SG_ 1015 EC_ECUCfg8_Stat "EC_ECUCfg8_Stat";
BA_ "FlexKomSigLaenge" SG_ 1015 EC_ECUCfg8_Stat 2;
BA_ "FlexKomSID" SG_ 1015 EC_ECUCfg8_Stat 1101;
BA_ "FlexKomIsMotorola" SG_ 1015 EC_ECUCfg8_Stat 1;
BA_ "FlexKomComment" SG_ 1015 EC_ECUCfg8_Stat "ECU Configuration messages status 8";
BA_ "GenSigSNA" SG_ 1015 EC_CBC7A "0h";
BA_ "GenSigCycleTime" SG_ 1015 EC_CBC7A 2000;
BA_ "FlexKomSigStartValue" SG_ 1015 EC_CBC7A "00000000h";
BA_ "FlexKomSigStartPos" SG_ 1015 EC_CBC7A 7;
BA_ "FlexKomSigName" SG_ 1015 EC_CBC7A "EC_CBC7";
BA_ "FlexKomSigLaenge" SG_ 1015 EC_CBC7A 32;
BA_ "FlexKomSID" SG_ 1015 EC_CBC7A 1106;
BA_ "FlexKomIsMotorola" SG_ 1015 EC_CBC7A 1;
BA_ "FlexKomComment" SG_ 1015 EC_CBC7A "CBC ecu configuration 7";
BA_ "GenSigSNA" SG_ 1015 EC_CBC7B "0h";
BA_ "GenSigCycleTime" SG_ 1015 EC_CBC7B 2000;
BA_ "FlexKomSigStartValue" SG_ 1015 EC_CBC7B "00000000h";
BA_ "FlexKomSigStartPos" SG_ 1015 EC_CBC7B 7;
BA_ "FlexKomSigName" SG_ 1015 EC_CBC7B "EC_CBC7";
BA_ "FlexKomSigLaenge" SG_ 1015 EC_CBC7B 32;
BA_ "FlexKomSID" SG_ 1015 EC_CBC7B 1106;
BA_ "FlexKomIsMotorola" SG_ 1015 EC_CBC7B 1;
BA_ "FlexKomComment" SG_ 1015 EC_CBC7B "CBC ecu configuration 7";
BA_ "GenSigSNA" SG_ 1015 EC_CBC8 "0h";
BA_ "GenSigCycleTime" SG_ 1015 EC_CBC8 2000;
BA_ "FlexKomSigStartValue" SG_ 1015 EC_CBC8 "00000000h";
BA_ "FlexKomSigStartPos" SG_ 1015 EC_CBC8 39;
BA_ "FlexKomSigName" SG_ 1015 EC_CBC8 "EC_CBC8";
BA_ "FlexKomSigLaenge" SG_ 1015 EC_CBC8 32;
BA_ "FlexKomSID" SG_ 1015 EC_CBC8 1104;
BA_ "FlexKomIsMotorola" SG_ 1015 EC_CBC8 1;
BA_ "FlexKomComment" SG_ 1015 EC_CBC8 "CBC ecu configuration 8";
BA_ "GenSigSNA" SG_ 1016 EC_BU_CBC1A "0h";
BA_ "GenSigSendType" SG_ 1016 EC_BU_CBC1A 1;
BA_ "FlexKomSigStartValue" SG_ 1016 EC_BU_CBC1A "00000000h";
BA_ "FlexKomSigStartPos" SG_ 1016 EC_BU_CBC1A 7;
BA_ "FlexKomSigName" SG_ 1016 EC_BU_CBC1A "EC_BU_CBC1";
BA_ "FlexKomSigLaenge" SG_ 1016 EC_BU_CBC1A 32;
BA_ "FlexKomSID" SG_ 1016 EC_BU_CBC1A 907;
BA_ "FlexKomIsMotorola" SG_ 1016 EC_BU_CBC1A 1;
BA_ "FlexKomComment" SG_ 1016 EC_BU_CBC1A "Backup for CBC ecu configuration 1";
BA_ "GenSigStartValue" SG_ 1016 EC_BU_ECUCfg1_Stat 3;
BA_ "GenSigSNA" SG_ 1016 EC_BU_ECUCfg1_Stat "3h";
BA_ "GenSigSendType" SG_ 1016 EC_BU_ECUCfg1_Stat 1;
BA_ "FlexKomSigStartValue" SG_ 1016 EC_BU_ECUCfg1_Stat "03h";
BA_ "FlexKomSigStartPos" SG_ 1016 EC_BU_ECUCfg1_Stat 1;
BA_ "FlexKomSigName" SG_ 1016 EC_BU_ECUCfg1_Stat "EC_BU_ECUCfg1_Stat";
BA_ "FlexKomSigLaenge" SG_ 1016 EC_BU_ECUCfg1_Stat 2;
BA_ "FlexKomSID" SG_ 1016 EC_BU_ECUCfg1_Stat 1064;
BA_ "FlexKomIsMotorola" SG_ 1016 EC_BU_ECUCfg1_Stat 1;
BA_ "FlexKomComment" SG_ 1016 EC_BU_ECUCfg1_Stat "Backup for ECU Configuration messages status 1";
BA_ "GenSigSNA" SG_ 1016 EC_BU_CBC1B "0h";
BA_ "GenSigSendType" SG_ 1016 EC_BU_CBC1B 1;
BA_ "FlexKomSigStartValue" SG_ 1016 EC_BU_CBC1B "00000000h";
BA_ "FlexKomSigStartPos" SG_ 1016 EC_BU_CBC1B 7;
BA_ "FlexKomSigName" SG_ 1016 EC_BU_CBC1B "EC_BU_CBC1";
BA_ "FlexKomSigLaenge" SG_ 1016 EC_BU_CBC1B 32;
BA_ "FlexKomSID" SG_ 1016 EC_BU_CBC1B 907;
BA_ "FlexKomIsMotorola" SG_ 1016 EC_BU_CBC1B 1;
BA_ "FlexKomComment" SG_ 1016 EC_BU_CBC1B "Backup for CBC ecu configuration 1";
BA_ "GenSigSNA" SG_ 1016 EC_BU_CBC2 "0h";
BA_ "GenSigSendType" SG_ 1016 EC_BU_CBC2 1;
BA_ "FlexKomSigStartValue" SG_ 1016 EC_BU_CBC2 "00000000h";
BA_ "FlexKomSigStartPos" SG_ 1016 EC_BU_CBC2 39;
BA_ "FlexKomSigName" SG_ 1016 EC_BU_CBC2 "EC_BU_CBC2";
BA_ "FlexKomSigLaenge" SG_ 1016 EC_BU_CBC2 32;
BA_ "FlexKomSID" SG_ 1016 EC_BU_CBC2 908;
BA_ "FlexKomIsMotorola" SG_ 1016 EC_BU_CBC2 1;
BA_ "FlexKomComment" SG_ 1016 EC_BU_CBC2 "Backup for CBC ecu configuration 2";
BA_ "GenSigStartValue" SG_ 1017 EC_BU_ECUCfg2_Stat 3;
BA_ "GenSigSNA" SG_ 1017 EC_BU_ECUCfg2_Stat "3h";
BA_ "GenSigSendType" SG_ 1017 EC_BU_ECUCfg2_Stat 1;
BA_ "FlexKomSigStartValue" SG_ 1017 EC_BU_ECUCfg2_Stat "03h";
BA_ "FlexKomSigStartPos" SG_ 1017 EC_BU_ECUCfg2_Stat 1;
BA_ "FlexKomSigName" SG_ 1017 EC_BU_ECUCfg2_Stat "EC_BU_ECUCfg2_Stat";
BA_ "FlexKomSigLaenge" SG_ 1017 EC_BU_ECUCfg2_Stat 2;
BA_ "FlexKomSID" SG_ 1017 EC_BU_ECUCfg2_Stat 1065;
BA_ "FlexKomIsMotorola" SG_ 1017 EC_BU_ECUCfg2_Stat 1;
BA_ "FlexKomComment" SG_ 1017 EC_BU_ECUCfg2_Stat "Backup for ECU Configuration messages status 2";
BA_ "GenSigSNA" SG_ 1017 EC_BU_CBC3A "0h";
BA_ "GenSigSendType" SG_ 1017 EC_BU_CBC3A 1;
BA_ "FlexKomSigStartValue" SG_ 1017 EC_BU_CBC3A "00000000h";
BA_ "FlexKomSigStartPos" SG_ 1017 EC_BU_CBC3A 7;
BA_ "FlexKomSigName" SG_ 1017 EC_BU_CBC3A "EC_BU_CBC3";
BA_ "FlexKomSigLaenge" SG_ 1017 EC_BU_CBC3A 32;
BA_ "FlexKomSID" SG_ 1017 EC_BU_CBC3A 909;
BA_ "FlexKomIsMotorola" SG_ 1017 EC_BU_CBC3A 1;
BA_ "FlexKomComment" SG_ 1017 EC_BU_CBC3A "Backup for CBC ecu configuration 3";
BA_ "GenSigSNA" SG_ 1017 EC_BU_CBC3B "0h";
BA_ "GenSigSendType" SG_ 1017 EC_BU_CBC3B 1;
BA_ "FlexKomSigStartValue" SG_ 1017 EC_BU_CBC3B "00000000h";
BA_ "FlexKomSigStartPos" SG_ 1017 EC_BU_CBC3B 7;
BA_ "FlexKomSigName" SG_ 1017 EC_BU_CBC3B "EC_BU_CBC3";
BA_ "FlexKomSigLaenge" SG_ 1017 EC_BU_CBC3B 32;
BA_ "FlexKomSID" SG_ 1017 EC_BU_CBC3B 909;
BA_ "FlexKomIsMotorola" SG_ 1017 EC_BU_CBC3B 1;
BA_ "FlexKomComment" SG_ 1017 EC_BU_CBC3B "Backup for CBC ecu configuration 3";
BA_ "GenSigSNA" SG_ 1017 EC_BU_CBC4 "0h";
BA_ "GenSigSendType" SG_ 1017 EC_BU_CBC4 1;
BA_ "FlexKomSigStartValue" SG_ 1017 EC_BU_CBC4 "00000000h";
BA_ "FlexKomSigStartPos" SG_ 1017 EC_BU_CBC4 39;
BA_ "FlexKomSigName" SG_ 1017 EC_BU_CBC4 "EC_BU_CBC4";
BA_ "FlexKomSigLaenge" SG_ 1017 EC_BU_CBC4 32;
BA_ "FlexKomSID" SG_ 1017 EC_BU_CBC4 910;
BA_ "FlexKomIsMotorola" SG_ 1017 EC_BU_CBC4 1;
BA_ "FlexKomComment" SG_ 1017 EC_BU_CBC4 "Backup for CBC ecu configuration 4";
BA_ "GenSigSNA" SG_ 1018 EC_BU_AudTel1A "0h";
BA_ "GenSigSendType" SG_ 1018 EC_BU_AudTel1A 1;
BA_ "FlexKomSigStartValue" SG_ 1018 EC_BU_AudTel1A "00000000h";
BA_ "FlexKomSigStartPos" SG_ 1018 EC_BU_AudTel1A 7;
BA_ "FlexKomSigName" SG_ 1018 EC_BU_AudTel1A "EC_BU_AudTel1";
BA_ "FlexKomSigLaenge" SG_ 1018 EC_BU_AudTel1A 32;
BA_ "FlexKomSID" SG_ 1018 EC_BU_AudTel1A 904;
BA_ "FlexKomIsMotorola" SG_ 1018 EC_BU_AudTel1A 1;
BA_ "FlexKomComment" SG_ 1018 EC_BU_AudTel1A "Backup for Audio and telematics ecu configuration ";
BA_ "GenSigSNA" SG_ 1018 EC_BU_AudTel2 "0h";
BA_ "GenSigSendType" SG_ 1018 EC_BU_AudTel2 1;
BA_ "FlexKomSigStartValue" SG_ 1018 EC_BU_AudTel2 "00000000h";
BA_ "FlexKomSigStartPos" SG_ 1018 EC_BU_AudTel2 39;
BA_ "FlexKomSigName" SG_ 1018 EC_BU_AudTel2 "EC_BU_AudTel2";
BA_ "FlexKomSigLaenge" SG_ 1018 EC_BU_AudTel2 32;
BA_ "FlexKomSID" SG_ 1018 EC_BU_AudTel2 905;
BA_ "FlexKomIsMotorola" SG_ 1018 EC_BU_AudTel2 1;
BA_ "FlexKomComment" SG_ 1018 EC_BU_AudTel2 "Backup for Audio and telematics ecu configuration ";
BA_ "GenSigSNA" SG_ 1018 EC_BU_AudTel1B "0h";
BA_ "GenSigSendType" SG_ 1018 EC_BU_AudTel1B 1;
BA_ "FlexKomSigStartValue" SG_ 1018 EC_BU_AudTel1B "00000000h";
BA_ "FlexKomSigStartPos" SG_ 1018 EC_BU_AudTel1B 7;
BA_ "FlexKomSigName" SG_ 1018 EC_BU_AudTel1B "EC_BU_AudTel1";
BA_ "FlexKomSigLaenge" SG_ 1018 EC_BU_AudTel1B 32;
BA_ "FlexKomSID" SG_ 1018 EC_BU_AudTel1B 904;
BA_ "FlexKomIsMotorola" SG_ 1018 EC_BU_AudTel1B 1;
BA_ "FlexKomComment" SG_ 1018 EC_BU_AudTel1B "Backup for Audio and telematics ecu configuration ";
BA_ "GenSigStartValue" SG_ 1018 EC_BU_ECUCfg3_Stat 3;
BA_ "GenSigSNA" SG_ 1018 EC_BU_ECUCfg3_Stat "3h";
BA_ "GenSigSendType" SG_ 1018 EC_BU_ECUCfg3_Stat 1;
BA_ "FlexKomSigStartValue" SG_ 1018 EC_BU_ECUCfg3_Stat "03h";
BA_ "FlexKomSigStartPos" SG_ 1018 EC_BU_ECUCfg3_Stat 1;
BA_ "FlexKomSigName" SG_ 1018 EC_BU_ECUCfg3_Stat "EC_BU_ECUCfg3_Stat";
BA_ "FlexKomSigLaenge" SG_ 1018 EC_BU_ECUCfg3_Stat 2;
BA_ "FlexKomSID" SG_ 1018 EC_BU_ECUCfg3_Stat 1066;
BA_ "FlexKomIsMotorola" SG_ 1018 EC_BU_ECUCfg3_Stat 1;
BA_ "FlexKomComment" SG_ 1018 EC_BU_ECUCfg3_Stat "Backup for ECU Configuration messages status 3";
BA_ "GenSigStartValue" SG_ 1019 EC_BU_ECUCfg4_Stat 3;
BA_ "GenSigSNA" SG_ 1019 EC_BU_ECUCfg4_Stat "3h";
BA_ "GenSigSendType" SG_ 1019 EC_BU_ECUCfg4_Stat 1;
BA_ "FlexKomSigStartValue" SG_ 1019 EC_BU_ECUCfg4_Stat "03h";
BA_ "FlexKomSigStartPos" SG_ 1019 EC_BU_ECUCfg4_Stat 1;
BA_ "FlexKomSigName" SG_ 1019 EC_BU_ECUCfg4_Stat "EC_BU_ECUCfg4_Stat";
BA_ "FlexKomSigLaenge" SG_ 1019 EC_BU_ECUCfg4_Stat 2;
BA_ "FlexKomSID" SG_ 1019 EC_BU_ECUCfg4_Stat 1067;
BA_ "FlexKomIsMotorola" SG_ 1019 EC_BU_ECUCfg4_Stat 1;
BA_ "FlexKomComment" SG_ 1019 EC_BU_ECUCfg4_Stat "Backup for ECU Configuration messages status 4";
BA_ "GenSigSNA" SG_ 1019 EC_BU_Cluster1A "0h";
BA_ "GenSigSendType" SG_ 1019 EC_BU_Cluster1A 1;
BA_ "FlexKomSigStartValue" SG_ 1019 EC_BU_Cluster1A "00000000h";
BA_ "FlexKomSigStartPos" SG_ 1019 EC_BU_Cluster1A 7;
BA_ "FlexKomSigName" SG_ 1019 EC_BU_Cluster1A "EC_BU_Cluster1";
BA_ "FlexKomSigLaenge" SG_ 1019 EC_BU_Cluster1A 32;
BA_ "FlexKomSID" SG_ 1019 EC_BU_Cluster1A 911;
BA_ "FlexKomIsMotorola" SG_ 1019 EC_BU_Cluster1A 1;
BA_ "FlexKomComment" SG_ 1019 EC_BU_Cluster1A "Backup for Instrument cluster ecu configuration 1";
BA_ "GenSigSNA" SG_ 1019 EC_BU_Cluster1B "0h";
BA_ "GenSigSendType" SG_ 1019 EC_BU_Cluster1B 1;
BA_ "FlexKomSigStartValue" SG_ 1019 EC_BU_Cluster1B "00000000h";
BA_ "FlexKomSigStartPos" SG_ 1019 EC_BU_Cluster1B 7;
BA_ "FlexKomSigName" SG_ 1019 EC_BU_Cluster1B "EC_BU_Cluster1";
BA_ "FlexKomSigLaenge" SG_ 1019 EC_BU_Cluster1B 32;
BA_ "FlexKomSID" SG_ 1019 EC_BU_Cluster1B 911;
BA_ "FlexKomIsMotorola" SG_ 1019 EC_BU_Cluster1B 1;
BA_ "FlexKomComment" SG_ 1019 EC_BU_Cluster1B "Backup for Instrument cluster ecu configuration 1";
BA_ "GenSigSNA" SG_ 1019 EC_BU_Cluster2 "0h";
BA_ "GenSigSendType" SG_ 1019 EC_BU_Cluster2 1;
BA_ "FlexKomSigStartValue" SG_ 1019 EC_BU_Cluster2 "00000000h";
BA_ "FlexKomSigStartPos" SG_ 1019 EC_BU_Cluster2 39;
BA_ "FlexKomSigName" SG_ 1019 EC_BU_Cluster2 "EC_BU_Cluster2";
BA_ "FlexKomSigLaenge" SG_ 1019 EC_BU_Cluster2 32;
BA_ "FlexKomSID" SG_ 1019 EC_BU_Cluster2 912;
BA_ "FlexKomIsMotorola" SG_ 1019 EC_BU_Cluster2 1;
BA_ "FlexKomComment" SG_ 1019 EC_BU_Cluster2 "Backup for Instrument cluster ecu configuration 2";
BA_ "GenSigSNA" SG_ 1020 EC_BU_WirelessA "0h";
BA_ "GenSigSendType" SG_ 1020 EC_BU_WirelessA 1;
BA_ "FlexKomSigStartValue" SG_ 1020 EC_BU_WirelessA "000000h";
BA_ "FlexKomSigStartPos" SG_ 1020 EC_BU_WirelessA 7;
BA_ "FlexKomSigName" SG_ 1020 EC_BU_WirelessA "EC_BU_Wireless";
BA_ "FlexKomSigLaenge" SG_ 1020 EC_BU_WirelessA 24;
BA_ "FlexKomSID" SG_ 1020 EC_BU_WirelessA 915;
BA_ "FlexKomIsMotorola" SG_ 1020 EC_BU_WirelessA 1;
BA_ "FlexKomComment" SG_ 1020 EC_BU_WirelessA "Backup for Wireless ecu configuration";
BA_ "GenSigSNA" SG_ 1020 EC_BU_WirelessB "0h";
BA_ "GenSigSendType" SG_ 1020 EC_BU_WirelessB 1;
BA_ "FlexKomSigStartValue" SG_ 1020 EC_BU_WirelessB "000000h";
BA_ "FlexKomSigStartPos" SG_ 1020 EC_BU_WirelessB 7;
BA_ "FlexKomSigName" SG_ 1020 EC_BU_WirelessB "EC_BU_Wireless";
BA_ "FlexKomSigLaenge" SG_ 1020 EC_BU_WirelessB 24;
BA_ "FlexKomSID" SG_ 1020 EC_BU_WirelessB 915;
BA_ "FlexKomIsMotorola" SG_ 1020 EC_BU_WirelessB 1;
BA_ "FlexKomComment" SG_ 1020 EC_BU_WirelessB "Backup for Wireless ecu configuration";
BA_ "GenSigSNA" SG_ 1020 EC_BU_Doors "0h";
BA_ "GenSigSendType" SG_ 1020 EC_BU_Doors 1;
BA_ "FlexKomSigStartValue" SG_ 1020 EC_BU_Doors "000000h";
BA_ "FlexKomSigStartPos" SG_ 1020 EC_BU_Doors 31;
BA_ "FlexKomSigName" SG_ 1020 EC_BU_Doors "EC_BU_Doors";
BA_ "FlexKomSigLaenge" SG_ 1020 EC_BU_Doors 24;
BA_ "FlexKomSID" SG_ 1020 EC_BU_Doors 913;
BA_ "FlexKomIsMotorola" SG_ 1020 EC_BU_Doors 1;
BA_ "FlexKomComment" SG_ 1020 EC_BU_Doors "Backup for Doors ecu configuration";
BA_ "GenSigSNA" SG_ 1020 EC_BU_Memory "0h";
BA_ "GenSigSendType" SG_ 1020 EC_BU_Memory 1;
BA_ "FlexKomSigStartValue" SG_ 1020 EC_BU_Memory "0000h";
BA_ "FlexKomSigStartPos" SG_ 1020 EC_BU_Memory 55;
BA_ "FlexKomSigName" SG_ 1020 EC_BU_Memory "EC_BU_Memory";
BA_ "FlexKomSigLaenge" SG_ 1020 EC_BU_Memory 16;
BA_ "FlexKomSID" SG_ 1020 EC_BU_Memory 916;
BA_ "FlexKomIsMotorola" SG_ 1020 EC_BU_Memory 1;
BA_ "FlexKomComment" SG_ 1020 EC_BU_Memory "Backup for Memory ecu configuration";
BA_ "GenSigStartValue" SG_ 1020 EC_BU_ECUCfg5_Stat 3;
BA_ "GenSigSNA" SG_ 1020 EC_BU_ECUCfg5_Stat "3h";
BA_ "GenSigSendType" SG_ 1020 EC_BU_ECUCfg5_Stat 1;
BA_ "FlexKomSigStartValue" SG_ 1020 EC_BU_ECUCfg5_Stat "03h";
BA_ "FlexKomSigStartPos" SG_ 1020 EC_BU_ECUCfg5_Stat 1;
BA_ "FlexKomSigName" SG_ 1020 EC_BU_ECUCfg5_Stat "EC_BU_ECUCfg5_Stat";
BA_ "FlexKomSigLaenge" SG_ 1020 EC_BU_ECUCfg5_Stat 2;
BA_ "FlexKomSID" SG_ 1020 EC_BU_ECUCfg5_Stat 1068;
BA_ "FlexKomIsMotorola" SG_ 1020 EC_BU_ECUCfg5_Stat 1;
BA_ "FlexKomComment" SG_ 1020 EC_BU_ECUCfg5_Stat "Backup for ECU Configuration messages status 5";
BA_ "GenSigSNA" SG_ 1021 EC_BU_Safety "0h";
BA_ "GenSigSendType" SG_ 1021 EC_BU_Safety 1;
BA_ "FlexKomSigStartValue" SG_ 1021 EC_BU_Safety "0000h";
BA_ "FlexKomSigStartPos" SG_ 1021 EC_BU_Safety 55;
BA_ "FlexKomSigName" SG_ 1021 EC_BU_Safety "EC_BU_Safety";
BA_ "FlexKomSigLaenge" SG_ 1021 EC_BU_Safety 16;
BA_ "FlexKomSID" SG_ 1021 EC_BU_Safety 918;
BA_ "FlexKomIsMotorola" SG_ 1021 EC_BU_Safety 1;
BA_ "FlexKomComment" SG_ 1021 EC_BU_Safety "Backup for Safety ecu configuration";
BA_ "GenSigSNA" SG_ 1021 EC_BU_BrakesA "0h";
BA_ "GenSigSendType" SG_ 1021 EC_BU_BrakesA 1;
BA_ "FlexKomSigStartValue" SG_ 1021 EC_BU_BrakesA "0000h";
BA_ "FlexKomSigStartPos" SG_ 1021 EC_BU_BrakesA 7;
BA_ "FlexKomSigName" SG_ 1021 EC_BU_BrakesA "EC_BU_Brakes";
BA_ "FlexKomSigLaenge" SG_ 1021 EC_BU_BrakesA 16;
BA_ "FlexKomSID" SG_ 1021 EC_BU_BrakesA 906;
BA_ "FlexKomIsMotorola" SG_ 1021 EC_BU_BrakesA 1;
BA_ "FlexKomComment" SG_ 1021 EC_BU_BrakesA "Backup for Brake system ecu configuration";
BA_ "GenSigSNA" SG_ 1021 EC_BU_BrakesB "0h";
BA_ "GenSigSendType" SG_ 1021 EC_BU_BrakesB 1;
BA_ "FlexKomSigStartValue" SG_ 1021 EC_BU_BrakesB "0000h";
BA_ "FlexKomSigStartPos" SG_ 1021 EC_BU_BrakesB 7;
BA_ "FlexKomSigName" SG_ 1021 EC_BU_BrakesB "EC_BU_Brakes";
BA_ "FlexKomSigLaenge" SG_ 1021 EC_BU_BrakesB 16;
BA_ "FlexKomSID" SG_ 1021 EC_BU_BrakesB 906;
BA_ "FlexKomIsMotorola" SG_ 1021 EC_BU_BrakesB 1;
BA_ "FlexKomComment" SG_ 1021 EC_BU_BrakesB "Backup for Brake system ecu configuration";
BA_ "GenSigSNA" SG_ 1021 EC_BU_Steering "0h";
BA_ "GenSigSendType" SG_ 1021 EC_BU_Steering 1;
BA_ "FlexKomSigStartValue" SG_ 1021 EC_BU_Steering "0000h";
BA_ "FlexKomSigStartPos" SG_ 1021 EC_BU_Steering 23;
BA_ "FlexKomSigName" SG_ 1021 EC_BU_Steering "EC_BU_Steering";
BA_ "FlexKomSigLaenge" SG_ 1021 EC_BU_Steering 16;
BA_ "FlexKomSID" SG_ 1021 EC_BU_Steering 1981;
BA_ "FlexKomIsMotorola" SG_ 1021 EC_BU_Steering 1;
BA_ "FlexKomComment" SG_ 1021 EC_BU_Steering "Backup for steering ecu configuration";
BA_ "GenSigStartValue" SG_ 1021 EC_BU_ECUCfg6_Stat 3;
BA_ "GenSigSNA" SG_ 1021 EC_BU_ECUCfg6_Stat "3h";
BA_ "GenSigSendType" SG_ 1021 EC_BU_ECUCfg6_Stat 1;
BA_ "FlexKomSigStartValue" SG_ 1021 EC_BU_ECUCfg6_Stat "03h";
BA_ "FlexKomSigStartPos" SG_ 1021 EC_BU_ECUCfg6_Stat 1;
BA_ "FlexKomSigName" SG_ 1021 EC_BU_ECUCfg6_Stat "EC_BU_ECUCfg6_Stat";
BA_ "FlexKomSigLaenge" SG_ 1021 EC_BU_ECUCfg6_Stat 2;
BA_ "FlexKomSID" SG_ 1021 EC_BU_ECUCfg6_Stat 1069;
BA_ "FlexKomIsMotorola" SG_ 1021 EC_BU_ECUCfg6_Stat 1;
BA_ "FlexKomComment" SG_ 1021 EC_BU_ECUCfg6_Stat "Backup for ECU Configuration messages status 6";
BA_ "GenSigSNA" SG_ 1021 EC_BU_Powertrain "0h";
BA_ "GenSigSendType" SG_ 1021 EC_BU_Powertrain 1;
BA_ "FlexKomSigStartValue" SG_ 1021 EC_BU_Powertrain "0000h";
BA_ "FlexKomSigStartPos" SG_ 1021 EC_BU_Powertrain 39;
BA_ "FlexKomSigName" SG_ 1021 EC_BU_Powertrain "EC_BU_Powertrain";
BA_ "FlexKomSigLaenge" SG_ 1021 EC_BU_Powertrain 16;
BA_ "FlexKomSID" SG_ 1021 EC_BU_Powertrain 917;
BA_ "FlexKomIsMotorola" SG_ 1021 EC_BU_Powertrain 1;
BA_ "FlexKomComment" SG_ 1021 EC_BU_Powertrain "Backup for Powertrain ecu configuration";
BA_ "GenSigSNA" SG_ 1022 EC_BU_CBC6 "0h";
BA_ "GenSigSendType" SG_ 1022 EC_BU_CBC6 1;
BA_ "FlexKomSigStartValue" SG_ 1022 EC_BU_CBC6 "00000000h";
BA_ "FlexKomSigStartPos" SG_ 1022 EC_BU_CBC6 39;
BA_ "FlexKomSigName" SG_ 1022 EC_BU_CBC6 "EC_BU_CBC6";
BA_ "FlexKomSigLaenge" SG_ 1022 EC_BU_CBC6 32;
BA_ "FlexKomSID" SG_ 1022 EC_BU_CBC6 1096;
BA_ "FlexKomIsMotorola" SG_ 1022 EC_BU_CBC6 1;
BA_ "FlexKomComment" SG_ 1022 EC_BU_CBC6 "Backup for CBC ecu configuration 6";
BA_ "GenSigStartValue" SG_ 1022 EC_BU_ECUCfg7_Stat 3;
BA_ "GenSigSNA" SG_ 1022 EC_BU_ECUCfg7_Stat "3h";
BA_ "GenSigSendType" SG_ 1022 EC_BU_ECUCfg7_Stat 1;
BA_ "FlexKomSigStartValue" SG_ 1022 EC_BU_ECUCfg7_Stat "03h";
BA_ "FlexKomSigStartPos" SG_ 1022 EC_BU_ECUCfg7_Stat 1;
BA_ "FlexKomSigName" SG_ 1022 EC_BU_ECUCfg7_Stat "EC_BU_ECUCfg7_Stat";
BA_ "FlexKomSigLaenge" SG_ 1022 EC_BU_ECUCfg7_Stat 2;
BA_ "FlexKomSID" SG_ 1022 EC_BU_ECUCfg7_Stat 1097;
BA_ "FlexKomIsMotorola" SG_ 1022 EC_BU_ECUCfg7_Stat 1;
BA_ "FlexKomComment" SG_ 1022 EC_BU_ECUCfg7_Stat "Backup for ECU Configuration messages status 7";
BA_ "GenSigSNA" SG_ 1022 EC_BU_CBC5A "0h";
BA_ "GenSigSendType" SG_ 1022 EC_BU_CBC5A 1;
BA_ "FlexKomSigStartValue" SG_ 1022 EC_BU_CBC5A "00000000h";
BA_ "FlexKomSigStartPos" SG_ 1022 EC_BU_CBC5A 7;
BA_ "FlexKomSigName" SG_ 1022 EC_BU_CBC5A "EC_BU_CBC5";
BA_ "FlexKomSigLaenge" SG_ 1022 EC_BU_CBC5A 32;
BA_ "FlexKomSID" SG_ 1022 EC_BU_CBC5A 1099;
BA_ "FlexKomIsMotorola" SG_ 1022 EC_BU_CBC5A 1;
BA_ "FlexKomComment" SG_ 1022 EC_BU_CBC5A "Backup for CBC ecu configuration 5";
BA_ "GenSigSNA" SG_ 1022 EC_BU_CBC5B "0h";
BA_ "GenSigSendType" SG_ 1022 EC_BU_CBC5B 1;
BA_ "FlexKomSigStartValue" SG_ 1022 EC_BU_CBC5B "00000000h";
BA_ "FlexKomSigStartPos" SG_ 1022 EC_BU_CBC5B 7;
BA_ "FlexKomSigName" SG_ 1022 EC_BU_CBC5B "EC_BU_CBC5";
BA_ "FlexKomSigLaenge" SG_ 1022 EC_BU_CBC5B 32;
BA_ "FlexKomSID" SG_ 1022 EC_BU_CBC5B 1099;
BA_ "FlexKomIsMotorola" SG_ 1022 EC_BU_CBC5B 1;
BA_ "FlexKomComment" SG_ 1022 EC_BU_CBC5B "Backup for CBC ecu configuration 5";
BA_ "GenSigStartValue" SG_ 1023 EC_BU_ECUCfg8_Stat 3;
BA_ "GenSigSNA" SG_ 1023 EC_BU_ECUCfg8_Stat "3h";
BA_ "GenSigSendType" SG_ 1023 EC_BU_ECUCfg8_Stat 1;
BA_ "FlexKomSigStartValue" SG_ 1023 EC_BU_ECUCfg8_Stat "03h";
BA_ "FlexKomSigStartPos" SG_ 1023 EC_BU_ECUCfg8_Stat 1;
BA_ "FlexKomSigName" SG_ 1023 EC_BU_ECUCfg8_Stat "EC_BU_ECUCfg8_Stat";
BA_ "FlexKomSigLaenge" SG_ 1023 EC_BU_ECUCfg8_Stat 2;
BA_ "FlexKomSID" SG_ 1023 EC_BU_ECUCfg8_Stat 1098;
BA_ "FlexKomIsMotorola" SG_ 1023 EC_BU_ECUCfg8_Stat 1;
BA_ "FlexKomComment" SG_ 1023 EC_BU_ECUCfg8_Stat "Backup for ECU Configuration messages status 8";
BA_ "GenSigSNA" SG_ 1023 EC_BU_CBC7A "0h";
BA_ "GenSigSendType" SG_ 1023 EC_BU_CBC7A 1;
BA_ "FlexKomSigStartValue" SG_ 1023 EC_BU_CBC7A "00000000h";
BA_ "FlexKomSigStartPos" SG_ 1023 EC_BU_CBC7A 7;
BA_ "FlexKomSigName" SG_ 1023 EC_BU_CBC7A "EC_BU_CBC7";
BA_ "FlexKomSigLaenge" SG_ 1023 EC_BU_CBC7A 32;
BA_ "FlexKomSID" SG_ 1023 EC_BU_CBC7A 1100;
BA_ "FlexKomIsMotorola" SG_ 1023 EC_BU_CBC7A 1;
BA_ "FlexKomComment" SG_ 1023 EC_BU_CBC7A "Backup for CBC ecu configuration 7";
BA_ "GenSigSNA" SG_ 1023 EC_BU_CBC7B "0h";
BA_ "GenSigSendType" SG_ 1023 EC_BU_CBC7B 1;
BA_ "FlexKomSigStartValue" SG_ 1023 EC_BU_CBC7B "00000000h";
BA_ "FlexKomSigStartPos" SG_ 1023 EC_BU_CBC7B 7;
BA_ "FlexKomSigName" SG_ 1023 EC_BU_CBC7B "EC_BU_CBC7";
BA_ "FlexKomSigLaenge" SG_ 1023 EC_BU_CBC7B 32;
BA_ "FlexKomSID" SG_ 1023 EC_BU_CBC7B 1100;
BA_ "FlexKomIsMotorola" SG_ 1023 EC_BU_CBC7B 1;
BA_ "FlexKomComment" SG_ 1023 EC_BU_CBC7B "Backup for CBC ecu configuration 7";
BA_ "GenSigSNA" SG_ 1023 EC_BU_CBC8 "0h";
BA_ "GenSigSendType" SG_ 1023 EC_BU_CBC8 1;
BA_ "FlexKomSigStartValue" SG_ 1023 EC_BU_CBC8 "00000000h";
BA_ "FlexKomSigStartPos" SG_ 1023 EC_BU_CBC8 39;
BA_ "FlexKomSigName" SG_ 1023 EC_BU_CBC8 "EC_BU_CBC8";
BA_ "FlexKomSigLaenge" SG_ 1023 EC_BU_CBC8 32;
BA_ "FlexKomSID" SG_ 1023 EC_BU_CBC8 1095;
BA_ "FlexKomIsMotorola" SG_ 1023 EC_BU_CBC8 1;
BA_ "FlexKomComment" SG_ 1023 EC_BU_CBC8 "Backup for CBC ecu configuration 8";
BA_ "GenSigStartValue" SG_ 1024 NM_Mode 255;
BA_ "GenSigSNA" SG_ 1024 NM_Mode "FFh";
BA_ "GenSigSendType" SG_ 1024 NM_Mode 1;
BA_ "FlexKomSigStartValue" SG_ 1024 NM_Mode "FFFFFFFFh";
BA_ "FlexKomSigStartPos" SG_ 1024 NM_Mode 7;
BA_ "FlexKomSigName" SG_ 1024 NM_Mode "NM";
BA_ "FlexKomSigLaenge" SG_ 1024 NM_Mode 32;
BA_ "FlexKomSID" SG_ 1024 NM_Mode 472;
BA_ "FlexKomIsMotorola" SG_ 1024 NM_Mode 1;
BA_ "FlexKomComment" SG_ 1024 NM_Mode "Network management state";
BA_ "GenSigStartValue" SG_ 1024 NM_Sleep_Ack 1;
BA_ "GenSigSNA" SG_ 1024 NM_Sleep_Ack "1h";
BA_ "GenSigSendType" SG_ 1024 NM_Sleep_Ack 1;
BA_ "FlexKomSigStartValue" SG_ 1024 NM_Sleep_Ack "FFFFFFFFh";
BA_ "FlexKomSigStartPos" SG_ 1024 NM_Sleep_Ack 7;
BA_ "FlexKomSigName" SG_ 1024 NM_Sleep_Ack "NM";
BA_ "FlexKomSigLaenge" SG_ 1024 NM_Sleep_Ack 32;
BA_ "FlexKomSID" SG_ 1024 NM_Sleep_Ack 472;
BA_ "FlexKomIsMotorola" SG_ 1024 NM_Sleep_Ack 1;
BA_ "FlexKomComment" SG_ 1024 NM_Sleep_Ack "Network management state";
BA_ "GenSigStartValue" SG_ 1024 WakeupCnt 255;
BA_ "GenSigSNA" SG_ 1024 WakeupCnt "FFh";
BA_ "GenSigSendType" SG_ 1024 WakeupCnt 1;
BA_ "FlexKomSigStartValue" SG_ 1024 WakeupCnt "FFFF00h";
BA_ "FlexKomSigStartPos" SG_ 1024 WakeupCnt 39;
BA_ "FlexKomSigName" SG_ 1024 WakeupCnt "Wakeup_RF_HUB";
BA_ "FlexKomSigLaenge" SG_ 1024 WakeupCnt 24;
BA_ "FlexKomSID" SG_ 1024 WakeupCnt 620;
BA_ "FlexKomIsMotorola" SG_ 1024 WakeupCnt 1;
BA_ "FlexKomComment" SG_ 1024 WakeupCnt "Mode 2 of NM_Ud_Srv";
BA_ "GenSigStartValue" SG_ 1024 Nw_Id 255;
BA_ "GenSigSNA" SG_ 1024 Nw_Id "FFh";
BA_ "GenSigSendType" SG_ 1024 Nw_Id 1;
BA_ "FlexKomSigStartValue" SG_ 1024 Nw_Id "FFh";
BA_ "FlexKomSigStartPos" SG_ 1024 Nw_Id 63;
BA_ "FlexKomSigName" SG_ 1024 Nw_Id "Nw_Id";
BA_ "FlexKomSigLaenge" SG_ 1024 Nw_Id 8;
BA_ "FlexKomSID" SG_ 1024 Nw_Id 535;
BA_ "FlexKomIsMotorola" SG_ 1024 Nw_Id 1;
BA_ "FlexKomComment" SG_ 1024 Nw_Id "Network identification no.";
BA_ "GenSigStartValue" SG_ 1024 NM_Sleep_Ind 1;
BA_ "GenSigSNA" SG_ 1024 NM_Sleep_Ind "1h";
BA_ "GenSigSendType" SG_ 1024 NM_Sleep_Ind 1;
BA_ "FlexKomSigStartValue" SG_ 1024 NM_Sleep_Ind "FFFFFFFFh";
BA_ "FlexKomSigStartPos" SG_ 1024 NM_Sleep_Ind 7;
BA_ "FlexKomSigName" SG_ 1024 NM_Sleep_Ind "NM";
BA_ "FlexKomSigLaenge" SG_ 1024 NM_Sleep_Ind 32;
BA_ "FlexKomSID" SG_ 1024 NM_Sleep_Ind 472;
BA_ "FlexKomIsMotorola" SG_ 1024 NM_Sleep_Ind 1;
BA_ "FlexKomComment" SG_ 1024 NM_Sleep_Ind "Network management state";
BA_ "GenSigStartValue" SG_ 1024 NM_Ud_Srv 255;
BA_ "GenSigSNA" SG_ 1024 NM_Ud_Srv "FFh";
BA_ "GenSigSendType" SG_ 1024 NM_Ud_Srv 1;
BA_ "FlexKomSigStartValue" SG_ 1024 NM_Ud_Srv "FFFFFFFFh";
BA_ "FlexKomSigStartPos" SG_ 1024 NM_Ud_Srv 7;
BA_ "FlexKomSigName" SG_ 1024 NM_Ud_Srv "NM";
BA_ "FlexKomSigLaenge" SG_ 1024 NM_Ud_Srv 32;
BA_ "FlexKomSID" SG_ 1024 NM_Ud_Srv 472;
BA_ "FlexKomIsMotorola" SG_ 1024 NM_Ud_Srv 1;
BA_ "FlexKomComment" SG_ 1024 NM_Ud_Srv "Network management state";
BA_ "GenSigSNA" SG_ 1024 Awake_NwSt "0h";
BA_ "GenSigSendType" SG_ 1024 Awake_NwSt 1;
BA_ "FlexKomSigStartValue" SG_ 1024 Awake_NwSt "000000h";
BA_ "FlexKomSigStartPos" SG_ 1024 Awake_NwSt 39;
BA_ "FlexKomSigName" SG_ 1024 Awake_NwSt "Awake_RF_HUB";
BA_ "FlexKomSigLaenge" SG_ 1024 Awake_NwSt 24;
BA_ "FlexKomSID" SG_ 1024 Awake_NwSt 619;
BA_ "FlexKomIsMotorola" SG_ 1024 Awake_NwSt 1;
BA_ "FlexKomComment" SG_ 1024 Awake_NwSt "Mode 15 of NM_Ud_Srv";
BA_ "GenSigStartValue" SG_ 1024 WakeupRsn_RF_HUB 255;
BA_ "GenSigSNA" SG_ 1024 WakeupRsn_RF_HUB "FFh";
BA_ "GenSigSendType" SG_ 1024 WakeupRsn_RF_HUB 1;
BA_ "FlexKomSigStartValue" SG_ 1024 WakeupRsn_RF_HUB "FFFF00h";
BA_ "FlexKomSigStartPos" SG_ 1024 WakeupRsn_RF_HUB 39;
BA_ "FlexKomSigName" SG_ 1024 WakeupRsn_RF_HUB "Wakeup_RF_HUB";
BA_ "FlexKomSigLaenge" SG_ 1024 WakeupRsn_RF_HUB 24;
BA_ "FlexKomSID" SG_ 1024 WakeupRsn_RF_HUB 620;
BA_ "FlexKomIsMotorola" SG_ 1024 WakeupRsn_RF_HUB 1;
BA_ "FlexKomComment" SG_ 1024 WakeupRsn_RF_HUB "Mode 2 of NM_Ud_Srv";
BA_ "GenSigSNA" SG_ 1024 Awake_Diag_Actv "0h";
BA_ "GenSigSendType" SG_ 1024 Awake_Diag_Actv 1;
BA_ "FlexKomSigStartValue" SG_ 1024 Awake_Diag_Actv "000000h";
BA_ "FlexKomSigStartPos" SG_ 1024 Awake_Diag_Actv 39;
BA_ "FlexKomSigName" SG_ 1024 Awake_Diag_Actv "Awake_RF_HUB";
BA_ "FlexKomSigLaenge" SG_ 1024 Awake_Diag_Actv 24;
BA_ "FlexKomSID" SG_ 1024 Awake_Diag_Actv 619;
BA_ "FlexKomIsMotorola" SG_ 1024 Awake_Diag_Actv 1;
BA_ "FlexKomComment" SG_ 1024 Awake_Diag_Actv "Mode 15 of NM_Ud_Srv";
BA_ "GenSigStartValue" SG_ 1024 NM_Successor 255;
BA_ "GenSigSNA" SG_ 1024 NM_Successor "FFh";
BA_ "GenSigSendType" SG_ 1024 NM_Successor 1;
BA_ "FlexKomSigStartValue" SG_ 1024 NM_Successor "FFFFFFFFh";
BA_ "FlexKomSigStartPos" SG_ 1024 NM_Successor 7;
BA_ "FlexKomSigName" SG_ 1024 NM_Successor "NM";
BA_ "FlexKomSigLaenge" SG_ 1024 NM_Successor 32;
BA_ "FlexKomSID" SG_ 1024 NM_Successor 472;
BA_ "FlexKomIsMotorola" SG_ 1024 NM_Successor 1;
BA_ "FlexKomComment" SG_ 1024 NM_Successor "Network management state";
BA_ "GenSigStartValue" SG_ 1024 NM_Ud_Launch 63;
BA_ "GenSigSNA" SG_ 1024 NM_Ud_Launch "3Fh";
BA_ "GenSigSendType" SG_ 1024 NM_Ud_Launch 1;
BA_ "FlexKomSigStartValue" SG_ 1024 NM_Ud_Launch "FFFFFFFFh";
BA_ "FlexKomSigStartPos" SG_ 1024 NM_Ud_Launch 7;
BA_ "FlexKomSigName" SG_ 1024 NM_Ud_Launch "NM";
BA_ "FlexKomSigLaenge" SG_ 1024 NM_Ud_Launch 32;
BA_ "FlexKomSID" SG_ 1024 NM_Ud_Launch 472;
BA_ "FlexKomIsMotorola" SG_ 1024 NM_Ud_Launch 1;
BA_ "FlexKomComment" SG_ 1024 NM_Ud_Launch "Network management state";
BA_ "GenSigStartValue" SG_ 1025 NM_Ud_Srv 255;
BA_ "GenSigSNA" SG_ 1025 NM_Ud_Srv "FFh";
BA_ "GenSigSendType" SG_ 1025 NM_Ud_Srv 1;
BA_ "FlexKomSigStartValue" SG_ 1025 NM_Ud_Srv "FFFFFFFFh";
BA_ "FlexKomSigStartPos" SG_ 1025 NM_Ud_Srv 7;
BA_ "FlexKomSigName" SG_ 1025 NM_Ud_Srv "NM";
BA_ "FlexKomSigLaenge" SG_ 1025 NM_Ud_Srv 32;
BA_ "FlexKomSID" SG_ 1025 NM_Ud_Srv 472;
BA_ "FlexKomIsMotorola" SG_ 1025 NM_Ud_Srv 1;
BA_ "FlexKomComment" SG_ 1025 NM_Ud_Srv "Network management state";
BA_ "GenSigStartValue" SG_ 1025 WakeupRsn_CBC 255;
BA_ "GenSigSNA" SG_ 1025 WakeupRsn_CBC "FFh";
BA_ "GenSigSendType" SG_ 1025 WakeupRsn_CBC 1;
BA_ "FlexKomSigStartValue" SG_ 1025 WakeupRsn_CBC "FFFF00h";
BA_ "FlexKomSigStartPos" SG_ 1025 WakeupRsn_CBC 39;
BA_ "FlexKomSigName" SG_ 1025 WakeupRsn_CBC "Wakeup_CBC";
BA_ "FlexKomSigLaenge" SG_ 1025 WakeupRsn_CBC 24;
BA_ "FlexKomSID" SG_ 1025 WakeupRsn_CBC 474;
BA_ "FlexKomIsMotorola" SG_ 1025 WakeupRsn_CBC 1;
BA_ "FlexKomComment" SG_ 1025 WakeupRsn_CBC "Mode 2 of NM_Ud_Srv";
BA_ "GenSigStartValue" SG_ 1025 NM_Mode 255;
BA_ "GenSigSNA" SG_ 1025 NM_Mode "FFh";
BA_ "GenSigSendType" SG_ 1025 NM_Mode 1;
BA_ "FlexKomSigStartValue" SG_ 1025 NM_Mode "FFFFFFFFh";
BA_ "FlexKomSigStartPos" SG_ 1025 NM_Mode 7;
BA_ "FlexKomSigName" SG_ 1025 NM_Mode "NM";
BA_ "FlexKomSigLaenge" SG_ 1025 NM_Mode 32;
BA_ "FlexKomSID" SG_ 1025 NM_Mode 472;
BA_ "FlexKomIsMotorola" SG_ 1025 NM_Mode 1;
BA_ "FlexKomComment" SG_ 1025 NM_Mode "Network management state";
BA_ "GenSigStartValue" SG_ 1025 NM_Successor 255;
BA_ "GenSigSNA" SG_ 1025 NM_Successor "FFh";
BA_ "GenSigSendType" SG_ 1025 NM_Successor 1;
BA_ "FlexKomSigStartValue" SG_ 1025 NM_Successor "FFFFFFFFh";
BA_ "FlexKomSigStartPos" SG_ 1025 NM_Successor 7;
BA_ "FlexKomSigName" SG_ 1025 NM_Successor "NM";
BA_ "FlexKomSigLaenge" SG_ 1025 NM_Successor 32;
BA_ "FlexKomSID" SG_ 1025 NM_Successor 472;
BA_ "FlexKomIsMotorola" SG_ 1025 NM_Successor 1;
BA_ "FlexKomComment" SG_ 1025 NM_Successor "Network management state";
BA_ "GenSigStartValue" SG_ 1025 NM_Ud_Launch 63;
BA_ "GenSigSNA" SG_ 1025 NM_Ud_Launch "3Fh";
BA_ "GenSigSendType" SG_ 1025 NM_Ud_Launch 1;
BA_ "FlexKomSigStartValue" SG_ 1025 NM_Ud_Launch "FFFFFFFFh";
BA_ "FlexKomSigStartPos" SG_ 1025 NM_Ud_Launch 7;
BA_ "FlexKomSigName" SG_ 1025 NM_Ud_Launch "NM";
BA_ "FlexKomSigLaenge" SG_ 1025 NM_Ud_Launch 32;
BA_ "FlexKomSID" SG_ 1025 NM_Ud_Launch 472;
BA_ "FlexKomIsMotorola" SG_ 1025 NM_Ud_Launch 1;
BA_ "FlexKomComment" SG_ 1025 NM_Ud_Launch "Network management state";
BA_ "GenSigStartValue" SG_ 1025 NM_Sleep_Ack 1;
BA_ "GenSigSNA" SG_ 1025 NM_Sleep_Ack "1h";
BA_ "GenSigSendType" SG_ 1025 NM_Sleep_Ack 1;
BA_ "FlexKomSigStartValue" SG_ 1025 NM_Sleep_Ack "FFFFFFFFh";
BA_ "FlexKomSigStartPos" SG_ 1025 NM_Sleep_Ack 7;
BA_ "FlexKomSigName" SG_ 1025 NM_Sleep_Ack "NM";
BA_ "FlexKomSigLaenge" SG_ 1025 NM_Sleep_Ack 32;
BA_ "FlexKomSID" SG_ 1025 NM_Sleep_Ack 472;
BA_ "FlexKomIsMotorola" SG_ 1025 NM_Sleep_Ack 1;
BA_ "FlexKomComment" SG_ 1025 NM_Sleep_Ack "Network management state";
BA_ "GenSigStartValue" SG_ 1025 NM_Sleep_Ind 1;
BA_ "GenSigSNA" SG_ 1025 NM_Sleep_Ind "1h";
BA_ "GenSigSendType" SG_ 1025 NM_Sleep_Ind 1;
BA_ "FlexKomSigStartValue" SG_ 1025 NM_Sleep_Ind "FFFFFFFFh";
BA_ "FlexKomSigStartPos" SG_ 1025 NM_Sleep_Ind 7;
BA_ "FlexKomSigName" SG_ 1025 NM_Sleep_Ind "NM";
BA_ "FlexKomSigLaenge" SG_ 1025 NM_Sleep_Ind 32;
BA_ "FlexKomSID" SG_ 1025 NM_Sleep_Ind 472;
BA_ "FlexKomIsMotorola" SG_ 1025 NM_Sleep_Ind 1;
BA_ "FlexKomComment" SG_ 1025 NM_Sleep_Ind "Network management state";
BA_ "GenSigSNA" SG_ 1025 Awake_NwSt "0h";
BA_ "GenSigSendType" SG_ 1025 Awake_NwSt 1;
BA_ "FlexKomSigStartValue" SG_ 1025 Awake_NwSt "000000h";
BA_ "FlexKomSigStartPos" SG_ 1025 Awake_NwSt 39;
BA_ "FlexKomSigName" SG_ 1025 Awake_NwSt "Awake_CBC";
BA_ "FlexKomSigLaenge" SG_ 1025 Awake_NwSt 24;
BA_ "FlexKomSID" SG_ 1025 Awake_NwSt 504;
BA_ "FlexKomIsMotorola" SG_ 1025 Awake_NwSt 1;
BA_ "FlexKomComment" SG_ 1025 Awake_NwSt "Mode 15 of NM_Ud_Srv";
BA_ "GenSigSNA" SG_ 1025 Awake_Diag_Actv "0h";
BA_ "GenSigSendType" SG_ 1025 Awake_Diag_Actv 1;
BA_ "FlexKomSigStartValue" SG_ 1025 Awake_Diag_Actv "000000h";
BA_ "FlexKomSigStartPos" SG_ 1025 Awake_Diag_Actv 39;
BA_ "FlexKomSigName" SG_ 1025 Awake_Diag_Actv "Awake_CBC";
BA_ "FlexKomSigLaenge" SG_ 1025 Awake_Diag_Actv 24;
BA_ "FlexKomSID" SG_ 1025 Awake_Diag_Actv 504;
BA_ "FlexKomIsMotorola" SG_ 1025 Awake_Diag_Actv 1;
BA_ "FlexKomComment" SG_ 1025 Awake_Diag_Actv "Mode 15 of NM_Ud_Srv";
BA_ "GenSigStartValue" SG_ 1025 WakeupCnt 255;
BA_ "GenSigSNA" SG_ 1025 WakeupCnt "FFh";
BA_ "GenSigSendType" SG_ 1025 WakeupCnt 1;
BA_ "FlexKomSigStartValue" SG_ 1025 WakeupCnt "FFFF00h";
BA_ "FlexKomSigStartPos" SG_ 1025 WakeupCnt 39;
BA_ "FlexKomSigName" SG_ 1025 WakeupCnt "Wakeup_CBC";
BA_ "FlexKomSigLaenge" SG_ 1025 WakeupCnt 24;
BA_ "FlexKomSID" SG_ 1025 WakeupCnt 474;
BA_ "FlexKomIsMotorola" SG_ 1025 WakeupCnt 1;
BA_ "FlexKomComment" SG_ 1025 WakeupCnt "Mode 2 of NM_Ud_Srv";
BA_ "GenSigStartValue" SG_ 1025 Nw_Id 255;
BA_ "GenSigSNA" SG_ 1025 Nw_Id "FFh";
BA_ "GenSigSendType" SG_ 1025 Nw_Id 1;
BA_ "FlexKomSigStartValue" SG_ 1025 Nw_Id "FFh";
BA_ "FlexKomSigStartPos" SG_ 1025 Nw_Id 63;
BA_ "FlexKomSigName" SG_ 1025 Nw_Id "Nw_Id";
BA_ "FlexKomSigLaenge" SG_ 1025 Nw_Id 8;
BA_ "FlexKomSID" SG_ 1025 Nw_Id 535;
BA_ "FlexKomIsMotorola" SG_ 1025 Nw_Id 1;
BA_ "FlexKomComment" SG_ 1025 Nw_Id "Network identification no.";
BA_ "GenSigStartValue" SG_ 1026 NM_Ud_Launch 63;
BA_ "GenSigSNA" SG_ 1026 NM_Ud_Launch "3Fh";
BA_ "GenSigSendType" SG_ 1026 NM_Ud_Launch 1;
BA_ "FlexKomSigStartValue" SG_ 1026 NM_Ud_Launch "FFFFFFFFh";
BA_ "FlexKomSigStartPos" SG_ 1026 NM_Ud_Launch 7;
BA_ "FlexKomSigName" SG_ 1026 NM_Ud_Launch "NM";
BA_ "FlexKomSigLaenge" SG_ 1026 NM_Ud_Launch 32;
BA_ "FlexKomSID" SG_ 1026 NM_Ud_Launch 472;
BA_ "FlexKomIsMotorola" SG_ 1026 NM_Ud_Launch 1;
BA_ "FlexKomComment" SG_ 1026 NM_Ud_Launch "Network management state";
BA_ "GenSigStartValue" SG_ 1026 WakeupRsn_IC 255;
BA_ "GenSigSNA" SG_ 1026 WakeupRsn_IC "FFh";
BA_ "GenSigSendType" SG_ 1026 WakeupRsn_IC 1;
BA_ "FlexKomSigStartValue" SG_ 1026 WakeupRsn_IC "FFFF00h";
BA_ "FlexKomSigStartPos" SG_ 1026 WakeupRsn_IC 39;
BA_ "FlexKomSigName" SG_ 1026 WakeupRsn_IC "Wakeup_IC";
BA_ "FlexKomSigLaenge" SG_ 1026 WakeupRsn_IC 24;
BA_ "FlexKomSID" SG_ 1026 WakeupRsn_IC 482;
BA_ "FlexKomIsMotorola" SG_ 1026 WakeupRsn_IC 1;
BA_ "FlexKomComment" SG_ 1026 WakeupRsn_IC "Mode 2 of NM_Ud_Srv";
BA_ "GenSigStartValue" SG_ 1026 NM_Sleep_Ack 1;
BA_ "GenSigSNA" SG_ 1026 NM_Sleep_Ack "1h";
BA_ "GenSigSendType" SG_ 1026 NM_Sleep_Ack 1;
BA_ "FlexKomSigStartValue" SG_ 1026 NM_Sleep_Ack "FFFFFFFFh";
BA_ "FlexKomSigStartPos" SG_ 1026 NM_Sleep_Ack 7;
BA_ "FlexKomSigName" SG_ 1026 NM_Sleep_Ack "NM";
BA_ "FlexKomSigLaenge" SG_ 1026 NM_Sleep_Ack 32;
BA_ "FlexKomSID" SG_ 1026 NM_Sleep_Ack 472;
BA_ "FlexKomIsMotorola" SG_ 1026 NM_Sleep_Ack 1;
BA_ "FlexKomComment" SG_ 1026 NM_Sleep_Ack "Network management state";
BA_ "GenSigStartValue" SG_ 1026 NM_Sleep_Ind 1;
BA_ "GenSigSNA" SG_ 1026 NM_Sleep_Ind "1h";
BA_ "GenSigSendType" SG_ 1026 NM_Sleep_Ind 1;
BA_ "FlexKomSigStartValue" SG_ 1026 NM_Sleep_Ind "FFFFFFFFh";
BA_ "FlexKomSigStartPos" SG_ 1026 NM_Sleep_Ind 7;
BA_ "FlexKomSigName" SG_ 1026 NM_Sleep_Ind "NM";
BA_ "FlexKomSigLaenge" SG_ 1026 NM_Sleep_Ind 32;
BA_ "FlexKomSID" SG_ 1026 NM_Sleep_Ind 472;
BA_ "FlexKomIsMotorola" SG_ 1026 NM_Sleep_Ind 1;
BA_ "FlexKomComment" SG_ 1026 NM_Sleep_Ind "Network management state";
BA_ "GenSigStartValue" SG_ 1026 NM_Ud_Srv 255;
BA_ "GenSigSNA" SG_ 1026 NM_Ud_Srv "FFh";
BA_ "GenSigSendType" SG_ 1026 NM_Ud_Srv 1;
BA_ "FlexKomSigStartValue" SG_ 1026 NM_Ud_Srv "FFFFFFFFh";
BA_ "FlexKomSigStartPos" SG_ 1026 NM_Ud_Srv 7;
BA_ "FlexKomSigName" SG_ 1026 NM_Ud_Srv "NM";
BA_ "FlexKomSigLaenge" SG_ 1026 NM_Ud_Srv 32;
BA_ "FlexKomSID" SG_ 1026 NM_Ud_Srv 472;
BA_ "FlexKomIsMotorola" SG_ 1026 NM_Ud_Srv 1;
BA_ "FlexKomComment" SG_ 1026 NM_Ud_Srv "Network management state";
BA_ "GenSigSNA" SG_ 1026 Awake_NwSt "0h";
BA_ "GenSigSendType" SG_ 1026 Awake_NwSt 1;
BA_ "FlexKomSigStartValue" SG_ 1026 Awake_NwSt "000000h";
BA_ "FlexKomSigStartPos" SG_ 1026 Awake_NwSt 39;
BA_ "FlexKomSigName" SG_ 1026 Awake_NwSt "Awake_IC";
BA_ "FlexKomSigLaenge" SG_ 1026 Awake_NwSt 24;
BA_ "FlexKomSID" SG_ 1026 Awake_NwSt 512;
BA_ "FlexKomIsMotorola" SG_ 1026 Awake_NwSt 1;
BA_ "FlexKomComment" SG_ 1026 Awake_NwSt "Mode 15 of NM_Ud_Srv";
BA_ "GenSigSNA" SG_ 1026 Awake_Diag_Actv "0h";
BA_ "GenSigSendType" SG_ 1026 Awake_Diag_Actv 1;
BA_ "FlexKomSigStartValue" SG_ 1026 Awake_Diag_Actv "000000h";
BA_ "FlexKomSigStartPos" SG_ 1026 Awake_Diag_Actv 39;
BA_ "FlexKomSigName" SG_ 1026 Awake_Diag_Actv "Awake_IC";
BA_ "FlexKomSigLaenge" SG_ 1026 Awake_Diag_Actv 24;
BA_ "FlexKomSID" SG_ 1026 Awake_Diag_Actv 512;
BA_ "FlexKomIsMotorola" SG_ 1026 Awake_Diag_Actv 1;
BA_ "FlexKomComment" SG_ 1026 Awake_Diag_Actv "Mode 15 of NM_Ud_Srv";
BA_ "GenSigStartValue" SG_ 1026 WakeupCnt 255;
BA_ "GenSigSNA" SG_ 1026 WakeupCnt "FFh";
BA_ "GenSigSendType" SG_ 1026 WakeupCnt 1;
BA_ "FlexKomSigStartValue" SG_ 1026 WakeupCnt "FFFF00h";
BA_ "FlexKomSigStartPos" SG_ 1026 WakeupCnt 39;
BA_ "FlexKomSigName" SG_ 1026 WakeupCnt "Wakeup_IC";
BA_ "FlexKomSigLaenge" SG_ 1026 WakeupCnt 24;
BA_ "FlexKomSID" SG_ 1026 WakeupCnt 482;
BA_ "FlexKomIsMotorola" SG_ 1026 WakeupCnt 1;
BA_ "FlexKomComment" SG_ 1026 WakeupCnt "Mode 2 of NM_Ud_Srv";
BA_ "GenSigStartValue" SG_ 1026 Nw_Id 255;
BA_ "GenSigSNA" SG_ 1026 Nw_Id "FFh";
BA_ "GenSigSendType" SG_ 1026 Nw_Id 1;
BA_ "FlexKomSigStartValue" SG_ 1026 Nw_Id "FFh";
BA_ "FlexKomSigStartPos" SG_ 1026 Nw_Id 63;
BA_ "FlexKomSigName" SG_ 1026 Nw_Id "Nw_Id";
BA_ "FlexKomSigLaenge" SG_ 1026 Nw_Id 8;
BA_ "FlexKomSID" SG_ 1026 Nw_Id 535;
BA_ "FlexKomIsMotorola" SG_ 1026 Nw_Id 1;
BA_ "FlexKomComment" SG_ 1026 Nw_Id "Network identification no.";
BA_ "GenSigStartValue" SG_ 1026 NM_Mode 255;
BA_ "GenSigSNA" SG_ 1026 NM_Mode "FFh";
BA_ "GenSigSendType" SG_ 1026 NM_Mode 1;
BA_ "FlexKomSigStartValue" SG_ 1026 NM_Mode "FFFFFFFFh";
BA_ "FlexKomSigStartPos" SG_ 1026 NM_Mode 7;
BA_ "FlexKomSigName" SG_ 1026 NM_Mode "NM";
BA_ "FlexKomSigLaenge" SG_ 1026 NM_Mode 32;
BA_ "FlexKomSID" SG_ 1026 NM_Mode 472;
BA_ "FlexKomIsMotorola" SG_ 1026 NM_Mode 1;
BA_ "FlexKomComment" SG_ 1026 NM_Mode "Network management state";
BA_ "GenSigStartValue" SG_ 1026 NM_Successor 255;
BA_ "GenSigSNA" SG_ 1026 NM_Successor "FFh";
BA_ "GenSigSendType" SG_ 1026 NM_Successor 1;
BA_ "FlexKomSigStartValue" SG_ 1026 NM_Successor "FFFFFFFFh";
BA_ "FlexKomSigStartPos" SG_ 1026 NM_Successor 7;
BA_ "FlexKomSigName" SG_ 1026 NM_Successor "NM";
BA_ "FlexKomSigLaenge" SG_ 1026 NM_Successor 32;
BA_ "FlexKomSID" SG_ 1026 NM_Successor 472;
BA_ "FlexKomIsMotorola" SG_ 1026 NM_Successor 1;
BA_ "FlexKomComment" SG_ 1026 NM_Successor "Network management state";
BA_ "GenSigStartValue" SG_ 1031 NM_Mode 255;
BA_ "GenSigSNA" SG_ 1031 NM_Mode "FFh";
BA_ "GenSigSendType" SG_ 1031 NM_Mode 1;
BA_ "FlexKomSigStartValue" SG_ 1031 NM_Mode "FFFFFFFFh";
BA_ "FlexKomSigStartPos" SG_ 1031 NM_Mode 7;
BA_ "FlexKomSigName" SG_ 1031 NM_Mode "NM";
BA_ "FlexKomSigLaenge" SG_ 1031 NM_Mode 32;
BA_ "FlexKomSID" SG_ 1031 NM_Mode 472;
BA_ "FlexKomIsMotorola" SG_ 1031 NM_Mode 1;
BA_ "FlexKomComment" SG_ 1031 NM_Mode "Network management state";
BA_ "GenSigStartValue" SG_ 1031 NM_Sleep_Ind 1;
BA_ "GenSigSNA" SG_ 1031 NM_Sleep_Ind "1h";
BA_ "GenSigSendType" SG_ 1031 NM_Sleep_Ind 1;
BA_ "FlexKomSigStartValue" SG_ 1031 NM_Sleep_Ind "FFFFFFFFh";
BA_ "FlexKomSigStartPos" SG_ 1031 NM_Sleep_Ind 7;
BA_ "FlexKomSigName" SG_ 1031 NM_Sleep_Ind "NM";
BA_ "FlexKomSigLaenge" SG_ 1031 NM_Sleep_Ind 32;
BA_ "FlexKomSID" SG_ 1031 NM_Sleep_Ind 472;
BA_ "FlexKomIsMotorola" SG_ 1031 NM_Sleep_Ind 1;
BA_ "FlexKomComment" SG_ 1031 NM_Sleep_Ind "Network management state";
BA_ "GenSigSNA" SG_ 1031 Awake_NwSt "0h";
BA_ "GenSigSendType" SG_ 1031 Awake_NwSt 1;
BA_ "FlexKomSigStartValue" SG_ 1031 Awake_NwSt "000000h";
BA_ "FlexKomSigStartPos" SG_ 1031 Awake_NwSt 39;
BA_ "FlexKomSigName" SG_ 1031 Awake_NwSt "Awake_ESC";
BA_ "FlexKomSigLaenge" SG_ 1031 Awake_NwSt 24;
BA_ "FlexKomSID" SG_ 1031 Awake_NwSt 961;
BA_ "FlexKomIsMotorola" SG_ 1031 Awake_NwSt 1;
BA_ "FlexKomComment" SG_ 1031 Awake_NwSt "Mode 15 of NM_Ud_Srv";
BA_ "GenSigStartValue" SG_ 1031 WakeupCnt 255;
BA_ "GenSigSNA" SG_ 1031 WakeupCnt "FFh";
BA_ "GenSigSendType" SG_ 1031 WakeupCnt 1;
BA_ "FlexKomSigStartValue" SG_ 1031 WakeupCnt "FFFF00h";
BA_ "FlexKomSigStartPos" SG_ 1031 WakeupCnt 39;
BA_ "FlexKomSigName" SG_ 1031 WakeupCnt "Wakeup_ESC";
BA_ "FlexKomSigLaenge" SG_ 1031 WakeupCnt 24;
BA_ "FlexKomSID" SG_ 1031 WakeupCnt 962;
BA_ "FlexKomIsMotorola" SG_ 1031 WakeupCnt 1;
BA_ "FlexKomComment" SG_ 1031 WakeupCnt "Mode 2 of NM_Ud_Srv";
BA_ "GenSigStartValue" SG_ 1031 Nw_Id 255;
BA_ "GenSigSNA" SG_ 1031 Nw_Id "FFh";
BA_ "GenSigSendType" SG_ 1031 Nw_Id 1;
BA_ "FlexKomSigStartValue" SG_ 1031 Nw_Id "FFh";
BA_ "FlexKomSigStartPos" SG_ 1031 Nw_Id 63;
BA_ "FlexKomSigName" SG_ 1031 Nw_Id "Nw_Id";
BA_ "FlexKomSigLaenge" SG_ 1031 Nw_Id 8;
BA_ "FlexKomSID" SG_ 1031 Nw_Id 535;
BA_ "FlexKomIsMotorola" SG_ 1031 Nw_Id 1;
BA_ "FlexKomComment" SG_ 1031 Nw_Id "Network identification no.";
BA_ "GenSigStartValue" SG_ 1031 NM_Ud_Srv 255;
BA_ "GenSigSNA" SG_ 1031 NM_Ud_Srv "FFh";
BA_ "GenSigSendType" SG_ 1031 NM_Ud_Srv 1;
BA_ "FlexKomSigStartValue" SG_ 1031 NM_Ud_Srv "FFFFFFFFh";
BA_ "FlexKomSigStartPos" SG_ 1031 NM_Ud_Srv 7;
BA_ "FlexKomSigName" SG_ 1031 NM_Ud_Srv "NM";
BA_ "FlexKomSigLaenge" SG_ 1031 NM_Ud_Srv 32;
BA_ "FlexKomSID" SG_ 1031 NM_Ud_Srv 472;
BA_ "FlexKomIsMotorola" SG_ 1031 NM_Ud_Srv 1;
BA_ "FlexKomComment" SG_ 1031 NM_Ud_Srv "Network management state";
BA_ "GenSigStartValue" SG_ 1031 WakeupRsn_ESC 255;
BA_ "GenSigSNA" SG_ 1031 WakeupRsn_ESC "FFh";
BA_ "GenSigSendType" SG_ 1031 WakeupRsn_ESC 1;
BA_ "FlexKomSigStartValue" SG_ 1031 WakeupRsn_ESC "FFFF00h";
BA_ "FlexKomSigStartPos" SG_ 1031 WakeupRsn_ESC 39;
BA_ "FlexKomSigName" SG_ 1031 WakeupRsn_ESC "Wakeup_ESC";
BA_ "FlexKomSigLaenge" SG_ 1031 WakeupRsn_ESC 24;
BA_ "FlexKomSID" SG_ 1031 WakeupRsn_ESC 962;
BA_ "FlexKomIsMotorola" SG_ 1031 WakeupRsn_ESC 1;
BA_ "FlexKomComment" SG_ 1031 WakeupRsn_ESC "Mode 2 of NM_Ud_Srv";
BA_ "GenSigSNA" SG_ 1031 Awake_Diag_Actv "0h";
BA_ "GenSigSendType" SG_ 1031 Awake_Diag_Actv 1;
BA_ "FlexKomSigStartValue" SG_ 1031 Awake_Diag_Actv "000000h";
BA_ "FlexKomSigStartPos" SG_ 1031 Awake_Diag_Actv 39;
BA_ "FlexKomSigName" SG_ 1031 Awake_Diag_Actv "Awake_ESC";
BA_ "FlexKomSigLaenge" SG_ 1031 Awake_Diag_Actv 24;
BA_ "FlexKomSID" SG_ 1031 Awake_Diag_Actv 961;
BA_ "FlexKomIsMotorola" SG_ 1031 Awake_Diag_Actv 1;
BA_ "FlexKomComment" SG_ 1031 Awake_Diag_Actv "Mode 15 of NM_Ud_Srv";
BA_ "GenSigSNA" SG_ 1031 Awake_Brake_Pedal_Pressed "0h";
BA_ "GenSigSendType" SG_ 1031 Awake_Brake_Pedal_Pressed 1;
BA_ "FlexKomSigStartValue" SG_ 1031 Awake_Brake_Pedal_Pressed "000000h";
BA_ "FlexKomSigStartPos" SG_ 1031 Awake_Brake_Pedal_Pressed 39;
BA_ "FlexKomSigName" SG_ 1031 Awake_Brake_Pedal_Pressed "Awake_ESC";
BA_ "FlexKomSigLaenge" SG_ 1031 Awake_Brake_Pedal_Pressed 24;
BA_ "FlexKomSID" SG_ 1031 Awake_Brake_Pedal_Pressed 961;
BA_ "FlexKomIsMotorola" SG_ 1031 Awake_Brake_Pedal_Pressed 1;
BA_ "FlexKomComment" SG_ 1031 Awake_Brake_Pedal_Pressed "Mode 15 of NM_Ud_Srv";
BA_ "GenSigSNA" SG_ 1031 Awake_Vehicle_Speed "0h";
BA_ "GenSigSendType" SG_ 1031 Awake_Vehicle_Speed 1;
BA_ "FlexKomSigStartValue" SG_ 1031 Awake_Vehicle_Speed "000000h";
BA_ "FlexKomSigStartPos" SG_ 1031 Awake_Vehicle_Speed 39;
BA_ "FlexKomSigName" SG_ 1031 Awake_Vehicle_Speed "Awake_ESC";
BA_ "FlexKomSigLaenge" SG_ 1031 Awake_Vehicle_Speed 24;
BA_ "FlexKomSID" SG_ 1031 Awake_Vehicle_Speed 961;
BA_ "FlexKomIsMotorola" SG_ 1031 Awake_Vehicle_Speed 1;
BA_ "FlexKomComment" SG_ 1031 Awake_Vehicle_Speed "Mode 15 of NM_Ud_Srv";
BA_ "GenSigSNA" SG_ 1031 Awake_EPB_Switch_Wakeup "0h";
BA_ "GenSigSendType" SG_ 1031 Awake_EPB_Switch_Wakeup 1;
BA_ "FlexKomSigStartValue" SG_ 1031 Awake_EPB_Switch_Wakeup "000000h";
BA_ "FlexKomSigStartPos" SG_ 1031 Awake_EPB_Switch_Wakeup 39;
BA_ "FlexKomSigName" SG_ 1031 Awake_EPB_Switch_Wakeup "Awake_ESC";
BA_ "FlexKomSigLaenge" SG_ 1031 Awake_EPB_Switch_Wakeup 24;
BA_ "FlexKomSID" SG_ 1031 Awake_EPB_Switch_Wakeup 961;
BA_ "FlexKomIsMotorola" SG_ 1031 Awake_EPB_Switch_Wakeup 1;
BA_ "FlexKomComment" SG_ 1031 Awake_EPB_Switch_Wakeup "Mode 15 of NM_Ud_Srv";
BA_ "GenSigSNA" SG_ 1031 Awake_Hardwire_Ignition "0h";
BA_ "GenSigSendType" SG_ 1031 Awake_Hardwire_Ignition 1;
BA_ "FlexKomSigStartValue" SG_ 1031 Awake_Hardwire_Ignition "000000h";
BA_ "FlexKomSigStartPos" SG_ 1031 Awake_Hardwire_Ignition 39;
BA_ "FlexKomSigName" SG_ 1031 Awake_Hardwire_Ignition "Awake_ESC";
BA_ "FlexKomSigLaenge" SG_ 1031 Awake_Hardwire_Ignition 24;
BA_ "FlexKomSID" SG_ 1031 Awake_Hardwire_Ignition 961;
BA_ "FlexKomIsMotorola" SG_ 1031 Awake_Hardwire_Ignition 1;
BA_ "FlexKomComment" SG_ 1031 Awake_Hardwire_Ignition "Mode 15 of NM_Ud_Srv";
BA_ "GenSigStartValue" SG_ 1031 NM_Successor 255;
BA_ "GenSigSNA" SG_ 1031 NM_Successor "FFh";
BA_ "GenSigSendType" SG_ 1031 NM_Successor 1;
BA_ "FlexKomSigStartValue" SG_ 1031 NM_Successor "FFFFFFFFh";
BA_ "FlexKomSigStartPos" SG_ 1031 NM_Successor 7;
BA_ "FlexKomSigName" SG_ 1031 NM_Successor "NM";
BA_ "FlexKomSigLaenge" SG_ 1031 NM_Successor 32;
BA_ "FlexKomSID" SG_ 1031 NM_Successor 472;
BA_ "FlexKomIsMotorola" SG_ 1031 NM_Successor 1;
BA_ "FlexKomComment" SG_ 1031 NM_Successor "Network management state";
BA_ "GenSigStartValue" SG_ 1031 NM_Ud_Launch 63;
BA_ "GenSigSNA" SG_ 1031 NM_Ud_Launch "3Fh";
BA_ "GenSigSendType" SG_ 1031 NM_Ud_Launch 1;
BA_ "FlexKomSigStartValue" SG_ 1031 NM_Ud_Launch "FFFFFFFFh";
BA_ "FlexKomSigStartPos" SG_ 1031 NM_Ud_Launch 7;
BA_ "FlexKomSigName" SG_ 1031 NM_Ud_Launch "NM";
BA_ "FlexKomSigLaenge" SG_ 1031 NM_Ud_Launch 32;
BA_ "FlexKomSID" SG_ 1031 NM_Ud_Launch 472;
BA_ "FlexKomIsMotorola" SG_ 1031 NM_Ud_Launch 1;
BA_ "FlexKomComment" SG_ 1031 NM_Ud_Launch "Network management state";
BA_ "GenSigStartValue" SG_ 1031 NM_Sleep_Ack 1;
BA_ "GenSigSNA" SG_ 1031 NM_Sleep_Ack "1h";
BA_ "GenSigSendType" SG_ 1031 NM_Sleep_Ack 1;
BA_ "FlexKomSigStartValue" SG_ 1031 NM_Sleep_Ack "FFFFFFFFh";
BA_ "FlexKomSigStartPos" SG_ 1031 NM_Sleep_Ack 7;
BA_ "FlexKomSigName" SG_ 1031 NM_Sleep_Ack "NM";
BA_ "FlexKomSigLaenge" SG_ 1031 NM_Sleep_Ack 32;
BA_ "FlexKomSID" SG_ 1031 NM_Sleep_Ack 472;
BA_ "FlexKomIsMotorola" SG_ 1031 NM_Sleep_Ack 1;
BA_ "FlexKomComment" SG_ 1031 NM_Sleep_Ack "Network management state";
BA_ "GenSigSNA" SG_ 1032 Awake_NwSt "0h";
BA_ "GenSigSendType" SG_ 1032 Awake_NwSt 1;
BA_ "FlexKomSigStartValue" SG_ 1032 Awake_NwSt "000000h";
BA_ "FlexKomSigStartPos" SG_ 1032 Awake_NwSt 39;
BA_ "FlexKomSigName" SG_ 1032 Awake_NwSt "Awake_ESL";
BA_ "FlexKomSigLaenge" SG_ 1032 Awake_NwSt 24;
BA_ "FlexKomSID" SG_ 1032 Awake_NwSt 2343;
BA_ "FlexKomIsMotorola" SG_ 1032 Awake_NwSt 1;
BA_ "FlexKomComment" SG_ 1032 Awake_NwSt "Mode 15 of NM_Ud_Srv";
BA_ "GenSigStartValue" SG_ 1032 WakeupCnt 255;
BA_ "GenSigSNA" SG_ 1032 WakeupCnt "FFh";
BA_ "GenSigSendType" SG_ 1032 WakeupCnt 1;
BA_ "FlexKomSigStartValue" SG_ 1032 WakeupCnt "FFFF00h";
BA_ "FlexKomSigStartPos" SG_ 1032 WakeupCnt 39;
BA_ "FlexKomSigName" SG_ 1032 WakeupCnt "Wakeup_ESL";
BA_ "FlexKomSigLaenge" SG_ 1032 WakeupCnt 24;
BA_ "FlexKomSID" SG_ 1032 WakeupCnt 2344;
BA_ "FlexKomIsMotorola" SG_ 1032 WakeupCnt 1;
BA_ "FlexKomComment" SG_ 1032 WakeupCnt "Mode 2 of NM_Ud_Srv";
BA_ "GenSigStartValue" SG_ 1032 Nw_Id 255;
BA_ "GenSigSNA" SG_ 1032 Nw_Id "FFh";
BA_ "GenSigSendType" SG_ 1032 Nw_Id 1;
BA_ "FlexKomSigStartValue" SG_ 1032 Nw_Id "FFh";
BA_ "FlexKomSigStartPos" SG_ 1032 Nw_Id 63;
BA_ "FlexKomSigName" SG_ 1032 Nw_Id "Nw_Id";
BA_ "FlexKomSigLaenge" SG_ 1032 Nw_Id 8;
BA_ "FlexKomSID" SG_ 1032 Nw_Id 535;
BA_ "FlexKomIsMotorola" SG_ 1032 Nw_Id 1;
BA_ "FlexKomComment" SG_ 1032 Nw_Id "Network identification no.";
BA_ "GenSigStartValue" SG_ 1032 NM_Mode 255;
BA_ "GenSigSNA" SG_ 1032 NM_Mode "FFh";
BA_ "GenSigSendType" SG_ 1032 NM_Mode 1;
BA_ "FlexKomSigStartValue" SG_ 1032 NM_Mode "FFFFFFFFh";
BA_ "FlexKomSigStartPos" SG_ 1032 NM_Mode 7;
BA_ "FlexKomSigName" SG_ 1032 NM_Mode "NM";
BA_ "FlexKomSigLaenge" SG_ 1032 NM_Mode 32;
BA_ "FlexKomSID" SG_ 1032 NM_Mode 472;
BA_ "FlexKomIsMotorola" SG_ 1032 NM_Mode 1;
BA_ "FlexKomComment" SG_ 1032 NM_Mode "Network management state";
BA_ "GenSigStartValue" SG_ 1032 NM_Successor 255;
BA_ "GenSigSNA" SG_ 1032 NM_Successor "FFh";
BA_ "GenSigSendType" SG_ 1032 NM_Successor 1;
BA_ "FlexKomSigStartValue" SG_ 1032 NM_Successor "FFFFFFFFh";
BA_ "FlexKomSigStartPos" SG_ 1032 NM_Successor 7;
BA_ "FlexKomSigName" SG_ 1032 NM_Successor "NM";
BA_ "FlexKomSigLaenge" SG_ 1032 NM_Successor 32;
BA_ "FlexKomSID" SG_ 1032 NM_Successor 472;
BA_ "FlexKomIsMotorola" SG_ 1032 NM_Successor 1;
BA_ "FlexKomComment" SG_ 1032 NM_Successor "Network management state";
BA_ "GenSigStartValue" SG_ 1032 NM_Ud_Launch 63;
BA_ "GenSigSNA" SG_ 1032 NM_Ud_Launch "3Fh";
BA_ "GenSigSendType" SG_ 1032 NM_Ud_Launch 1;
BA_ "FlexKomSigStartValue" SG_ 1032 NM_Ud_Launch "FFFFFFFFh";
BA_ "FlexKomSigStartPos" SG_ 1032 NM_Ud_Launch 7;
BA_ "FlexKomSigName" SG_ 1032 NM_Ud_Launch "NM";
BA_ "FlexKomSigLaenge" SG_ 1032 NM_Ud_Launch 32;
BA_ "FlexKomSID" SG_ 1032 NM_Ud_Launch 472;
BA_ "FlexKomIsMotorola" SG_ 1032 NM_Ud_Launch 1;
BA_ "FlexKomComment" SG_ 1032 NM_Ud_Launch "Network management state";
BA_ "GenSigStartValue" SG_ 1032 NM_Sleep_Ack 1;
BA_ "GenSigSNA" SG_ 1032 NM_Sleep_Ack "1h";
BA_ "GenSigSendType" SG_ 1032 NM_Sleep_Ack 1;
BA_ "FlexKomSigStartValue" SG_ 1032 NM_Sleep_Ack "FFFFFFFFh";
BA_ "FlexKomSigStartPos" SG_ 1032 NM_Sleep_Ack 7;
BA_ "FlexKomSigName" SG_ 1032 NM_Sleep_Ack "NM";
BA_ "FlexKomSigLaenge" SG_ 1032 NM_Sleep_Ack 32;
BA_ "FlexKomSID" SG_ 1032 NM_Sleep_Ack 472;
BA_ "FlexKomIsMotorola" SG_ 1032 NM_Sleep_Ack 1;
BA_ "FlexKomComment" SG_ 1032 NM_Sleep_Ack "Network management state";
BA_ "GenSigStartValue" SG_ 1032 NM_Sleep_Ind 1;
BA_ "GenSigSNA" SG_ 1032 NM_Sleep_Ind "1h";
BA_ "GenSigSendType" SG_ 1032 NM_Sleep_Ind 1;
BA_ "FlexKomSigStartValue" SG_ 1032 NM_Sleep_Ind "FFFFFFFFh";
BA_ "FlexKomSigStartPos" SG_ 1032 NM_Sleep_Ind 7;
BA_ "FlexKomSigName" SG_ 1032 NM_Sleep_Ind "NM";
BA_ "FlexKomSigLaenge" SG_ 1032 NM_Sleep_Ind 32;
BA_ "FlexKomSID" SG_ 1032 NM_Sleep_Ind 472;
BA_ "FlexKomIsMotorola" SG_ 1032 NM_Sleep_Ind 1;
BA_ "FlexKomComment" SG_ 1032 NM_Sleep_Ind "Network management state";
BA_ "GenSigStartValue" SG_ 1032 NM_Ud_Srv 255;
BA_ "GenSigSNA" SG_ 1032 NM_Ud_Srv "FFh";
BA_ "GenSigSendType" SG_ 1032 NM_Ud_Srv 1;
BA_ "FlexKomSigStartValue" SG_ 1032 NM_Ud_Srv "FFFFFFFFh";
BA_ "FlexKomSigStartPos" SG_ 1032 NM_Ud_Srv 7;
BA_ "FlexKomSigName" SG_ 1032 NM_Ud_Srv "NM";
BA_ "FlexKomSigLaenge" SG_ 1032 NM_Ud_Srv 32;
BA_ "FlexKomSID" SG_ 1032 NM_Ud_Srv 472;
BA_ "FlexKomIsMotorola" SG_ 1032 NM_Ud_Srv 1;
BA_ "FlexKomComment" SG_ 1032 NM_Ud_Srv "Network management state";
BA_ "GenSigStartValue" SG_ 1032 WakeupRsn_ESL 255;
BA_ "GenSigSNA" SG_ 1032 WakeupRsn_ESL "FFh";
BA_ "GenSigSendType" SG_ 1032 WakeupRsn_ESL 1;
BA_ "FlexKomSigStartValue" SG_ 1032 WakeupRsn_ESL "FFFF00h";
BA_ "FlexKomSigStartPos" SG_ 1032 WakeupRsn_ESL 39;
BA_ "FlexKomSigName" SG_ 1032 WakeupRsn_ESL "Wakeup_ESL";
BA_ "FlexKomSigLaenge" SG_ 1032 WakeupRsn_ESL 24;
BA_ "FlexKomSID" SG_ 1032 WakeupRsn_ESL 2344;
BA_ "FlexKomIsMotorola" SG_ 1032 WakeupRsn_ESL 1;
BA_ "FlexKomComment" SG_ 1032 WakeupRsn_ESL "Mode 2 of NM_Ud_Srv";
BA_ "GenSigSNA" SG_ 1032 Awake_Diag_Actv "0h";
BA_ "GenSigSendType" SG_ 1032 Awake_Diag_Actv 1;
BA_ "FlexKomSigStartValue" SG_ 1032 Awake_Diag_Actv "000000h";
BA_ "FlexKomSigStartPos" SG_ 1032 Awake_Diag_Actv 39;
BA_ "FlexKomSigName" SG_ 1032 Awake_Diag_Actv "Awake_ESL";
BA_ "FlexKomSigLaenge" SG_ 1032 Awake_Diag_Actv 24;
BA_ "FlexKomSID" SG_ 1032 Awake_Diag_Actv 2343;
BA_ "FlexKomIsMotorola" SG_ 1032 Awake_Diag_Actv 1;
BA_ "FlexKomComment" SG_ 1032 Awake_Diag_Actv "Mode 15 of NM_Ud_Srv";
BA_ "GenSigSNA" SG_ 1032 Awake_Ign_RunStart "0h";
BA_ "GenSigSendType" SG_ 1032 Awake_Ign_RunStart 1;
BA_ "FlexKomSigStartValue" SG_ 1032 Awake_Ign_RunStart "000000h";
BA_ "FlexKomSigStartPos" SG_ 1032 Awake_Ign_RunStart 39;
BA_ "FlexKomSigName" SG_ 1032 Awake_Ign_RunStart "Awake_ESL";
BA_ "FlexKomSigLaenge" SG_ 1032 Awake_Ign_RunStart 24;
BA_ "FlexKomSID" SG_ 1032 Awake_Ign_RunStart 2343;
BA_ "FlexKomIsMotorola" SG_ 1032 Awake_Ign_RunStart 1;
BA_ "FlexKomComment" SG_ 1032 Awake_Ign_RunStart "Mode 15 of NM_Ud_Srv";
BA_ "GenSigSNA" SG_ 1032 Awake_Lock_Unlock "0h";
BA_ "GenSigSendType" SG_ 1032 Awake_Lock_Unlock 1;
BA_ "FlexKomSigStartValue" SG_ 1032 Awake_Lock_Unlock "000000h";
BA_ "FlexKomSigStartPos" SG_ 1032 Awake_Lock_Unlock 39;
BA_ "FlexKomSigName" SG_ 1032 Awake_Lock_Unlock "Awake_ESL";
BA_ "FlexKomSigLaenge" SG_ 1032 Awake_Lock_Unlock 24;
BA_ "FlexKomSID" SG_ 1032 Awake_Lock_Unlock 2343;
BA_ "FlexKomIsMotorola" SG_ 1032 Awake_Lock_Unlock 1;
BA_ "FlexKomComment" SG_ 1032 Awake_Lock_Unlock "Mode 15 of NM_Ud_Srv";
BA_ "GenSigStartValue" SG_ 1033 NM_Sleep_Ack 1;
BA_ "GenSigSNA" SG_ 1033 NM_Sleep_Ack "1h";
BA_ "GenSigSendType" SG_ 1033 NM_Sleep_Ack 1;
BA_ "FlexKomSigStartValue" SG_ 1033 NM_Sleep_Ack "FFFFFFFFh";
BA_ "FlexKomSigStartPos" SG_ 1033 NM_Sleep_Ack 7;
BA_ "FlexKomSigName" SG_ 1033 NM_Sleep_Ack "NM";
BA_ "FlexKomSigLaenge" SG_ 1033 NM_Sleep_Ack 32;
BA_ "FlexKomSID" SG_ 1033 NM_Sleep_Ack 472;
BA_ "FlexKomIsMotorola" SG_ 1033 NM_Sleep_Ack 1;
BA_ "FlexKomComment" SG_ 1033 NM_Sleep_Ack "Network management state";
BA_ "GenSigSNA" SG_ 1033 Awake_Ignition_On "0h";
BA_ "GenSigSendType" SG_ 1033 Awake_Ignition_On 1;
BA_ "FlexKomSigStartValue" SG_ 1033 Awake_Ignition_On "000000h";
BA_ "FlexKomSigStartPos" SG_ 1033 Awake_Ignition_On 39;
BA_ "FlexKomSigName" SG_ 1033 Awake_Ignition_On "Awake_SBWM";
BA_ "FlexKomSigLaenge" SG_ 1033 Awake_Ignition_On 24;
BA_ "FlexKomSID" SG_ 1033 Awake_Ignition_On 1370;
BA_ "FlexKomIsMotorola" SG_ 1033 Awake_Ignition_On 1;
BA_ "FlexKomComment" SG_ 1033 Awake_Ignition_On "Mode 15 of NM_Ud_Srv";
BA_ "GenSigStartValue" SG_ 1033 Nw_Id 255;
BA_ "GenSigSNA" SG_ 1033 Nw_Id "FFh";
BA_ "GenSigSendType" SG_ 1033 Nw_Id 1;
BA_ "FlexKomSigStartValue" SG_ 1033 Nw_Id "FFh";
BA_ "FlexKomSigStartPos" SG_ 1033 Nw_Id 63;
BA_ "FlexKomSigName" SG_ 1033 Nw_Id "Nw_Id";
BA_ "FlexKomSigLaenge" SG_ 1033 Nw_Id 8;
BA_ "FlexKomSID" SG_ 1033 Nw_Id 535;
BA_ "FlexKomIsMotorola" SG_ 1033 Nw_Id 1;
BA_ "FlexKomComment" SG_ 1033 Nw_Id "Network identification no.";
BA_ "GenSigStartValue" SG_ 1033 NM_Sleep_Ind 1;
BA_ "GenSigSNA" SG_ 1033 NM_Sleep_Ind "1h";
BA_ "GenSigSendType" SG_ 1033 NM_Sleep_Ind 1;
BA_ "FlexKomSigStartValue" SG_ 1033 NM_Sleep_Ind "FFFFFFFFh";
BA_ "FlexKomSigStartPos" SG_ 1033 NM_Sleep_Ind 7;
BA_ "FlexKomSigName" SG_ 1033 NM_Sleep_Ind "NM";
BA_ "FlexKomSigLaenge" SG_ 1033 NM_Sleep_Ind 32;
BA_ "FlexKomSID" SG_ 1033 NM_Sleep_Ind 472;
BA_ "FlexKomIsMotorola" SG_ 1033 NM_Sleep_Ind 1;
BA_ "FlexKomComment" SG_ 1033 NM_Sleep_Ind "Network management state";
BA_ "GenSigStartValue" SG_ 1033 NM_Ud_Srv 255;
BA_ "GenSigSNA" SG_ 1033 NM_Ud_Srv "FFh";
BA_ "GenSigSendType" SG_ 1033 NM_Ud_Srv 1;
BA_ "FlexKomSigStartValue" SG_ 1033 NM_Ud_Srv "FFFFFFFFh";
BA_ "FlexKomSigStartPos" SG_ 1033 NM_Ud_Srv 7;
BA_ "FlexKomSigName" SG_ 1033 NM_Ud_Srv "NM";
BA_ "FlexKomSigLaenge" SG_ 1033 NM_Ud_Srv 32;
BA_ "FlexKomSID" SG_ 1033 NM_Ud_Srv 472;
BA_ "FlexKomIsMotorola" SG_ 1033 NM_Ud_Srv 1;
BA_ "FlexKomComment" SG_ 1033 NM_Ud_Srv "Network management state";
BA_ "GenSigSNA" SG_ 1033 Awake_NwSt "0h";
BA_ "GenSigSendType" SG_ 1033 Awake_NwSt 1;
BA_ "FlexKomSigStartValue" SG_ 1033 Awake_NwSt "000000h";
BA_ "FlexKomSigStartPos" SG_ 1033 Awake_NwSt 39;
BA_ "FlexKomSigName" SG_ 1033 Awake_NwSt "Awake_SBWM";
BA_ "FlexKomSigLaenge" SG_ 1033 Awake_NwSt 24;
BA_ "FlexKomSID" SG_ 1033 Awake_NwSt 1370;
BA_ "FlexKomIsMotorola" SG_ 1033 Awake_NwSt 1;
BA_ "FlexKomComment" SG_ 1033 Awake_NwSt "Mode 15 of NM_Ud_Srv";
BA_ "GenSigStartValue" SG_ 1033 WakeupRsn_SBWM 255;
BA_ "GenSigSNA" SG_ 1033 WakeupRsn_SBWM "FFh";
BA_ "GenSigSendType" SG_ 1033 WakeupRsn_SBWM 1;
BA_ "FlexKomSigStartValue" SG_ 1033 WakeupRsn_SBWM "FFFF00h";
BA_ "FlexKomSigStartPos" SG_ 1033 WakeupRsn_SBWM 39;
BA_ "FlexKomSigName" SG_ 1033 WakeupRsn_SBWM "Wakeup_SBWM";
BA_ "FlexKomSigLaenge" SG_ 1033 WakeupRsn_SBWM 24;
BA_ "FlexKomSID" SG_ 1033 WakeupRsn_SBWM 1371;
BA_ "FlexKomIsMotorola" SG_ 1033 WakeupRsn_SBWM 1;
BA_ "FlexKomComment" SG_ 1033 WakeupRsn_SBWM "Mode 2 of NM_Ud_Srv";
BA_ "GenSigSNA" SG_ 1033 Awake_Diag_Actv "0h";
BA_ "GenSigSendType" SG_ 1033 Awake_Diag_Actv 1;
BA_ "FlexKomSigStartValue" SG_ 1033 Awake_Diag_Actv "000000h";
BA_ "FlexKomSigStartPos" SG_ 1033 Awake_Diag_Actv 39;
BA_ "FlexKomSigName" SG_ 1033 Awake_Diag_Actv "Awake_SBWM";
BA_ "FlexKomSigLaenge" SG_ 1033 Awake_Diag_Actv 24;
BA_ "FlexKomSID" SG_ 1033 Awake_Diag_Actv 1370;
BA_ "FlexKomIsMotorola" SG_ 1033 Awake_Diag_Actv 1;
BA_ "FlexKomComment" SG_ 1033 Awake_Diag_Actv "Mode 15 of NM_Ud_Srv";
BA_ "GenSigSNA" SG_ 1033 Awake_EEPROM "0h";
BA_ "GenSigSendType" SG_ 1033 Awake_EEPROM 1;
BA_ "FlexKomSigStartValue" SG_ 1033 Awake_EEPROM "000000h";
BA_ "FlexKomSigStartPos" SG_ 1033 Awake_EEPROM 39;
BA_ "FlexKomSigName" SG_ 1033 Awake_EEPROM "Awake_SBWM";
BA_ "FlexKomSigLaenge" SG_ 1033 Awake_EEPROM 24;
BA_ "FlexKomSID" SG_ 1033 Awake_EEPROM 1370;
BA_ "FlexKomIsMotorola" SG_ 1033 Awake_EEPROM 1;
BA_ "FlexKomComment" SG_ 1033 Awake_EEPROM "Mode 15 of NM_Ud_Srv";
BA_ "GenSigSNA" SG_ 1033 Awake_URS "0h";
BA_ "GenSigSendType" SG_ 1033 Awake_URS 1;
BA_ "FlexKomSigStartValue" SG_ 1033 Awake_URS "000000h";
BA_ "FlexKomSigStartPos" SG_ 1033 Awake_URS 39;
BA_ "FlexKomSigName" SG_ 1033 Awake_URS "Awake_SBWM";
BA_ "FlexKomSigLaenge" SG_ 1033 Awake_URS 24;
BA_ "FlexKomSID" SG_ 1033 Awake_URS 1370;
BA_ "FlexKomIsMotorola" SG_ 1033 Awake_URS 1;
BA_ "FlexKomComment" SG_ 1033 Awake_URS "Mode 15 of NM_Ud_Srv";
BA_ "GenSigStartValue" SG_ 1033 WakeupCnt 255;
BA_ "GenSigSNA" SG_ 1033 WakeupCnt "FFh";
BA_ "GenSigSendType" SG_ 1033 WakeupCnt 1;
BA_ "FlexKomSigStartValue" SG_ 1033 WakeupCnt "FFFF00h";
BA_ "FlexKomSigStartPos" SG_ 1033 WakeupCnt 39;
BA_ "FlexKomSigName" SG_ 1033 WakeupCnt "Wakeup_SBWM";
BA_ "FlexKomSigLaenge" SG_ 1033 WakeupCnt 24;
BA_ "FlexKomSID" SG_ 1033 WakeupCnt 1371;
BA_ "FlexKomIsMotorola" SG_ 1033 WakeupCnt 1;
BA_ "FlexKomComment" SG_ 1033 WakeupCnt "Mode 2 of NM_Ud_Srv";
BA_ "GenSigStartValue" SG_ 1033 NM_Mode 255;
BA_ "GenSigSNA" SG_ 1033 NM_Mode "FFh";
BA_ "GenSigSendType" SG_ 1033 NM_Mode 1;
BA_ "FlexKomSigStartValue" SG_ 1033 NM_Mode "FFFFFFFFh";
BA_ "FlexKomSigStartPos" SG_ 1033 NM_Mode 7;
BA_ "FlexKomSigName" SG_ 1033 NM_Mode "NM";
BA_ "FlexKomSigLaenge" SG_ 1033 NM_Mode 32;
BA_ "FlexKomSID" SG_ 1033 NM_Mode 472;
BA_ "FlexKomIsMotorola" SG_ 1033 NM_Mode 1;
BA_ "FlexKomComment" SG_ 1033 NM_Mode "Network management state";
BA_ "GenSigStartValue" SG_ 1033 NM_Successor 255;
BA_ "GenSigSNA" SG_ 1033 NM_Successor "FFh";
BA_ "GenSigSendType" SG_ 1033 NM_Successor 1;
BA_ "FlexKomSigStartValue" SG_ 1033 NM_Successor "FFFFFFFFh";
BA_ "FlexKomSigStartPos" SG_ 1033 NM_Successor 7;
BA_ "FlexKomSigName" SG_ 1033 NM_Successor "NM";
BA_ "FlexKomSigLaenge" SG_ 1033 NM_Successor 32;
BA_ "FlexKomSID" SG_ 1033 NM_Successor 472;
BA_ "FlexKomIsMotorola" SG_ 1033 NM_Successor 1;
BA_ "FlexKomComment" SG_ 1033 NM_Successor "Network management state";
BA_ "GenSigStartValue" SG_ 1033 NM_Ud_Launch 63;
BA_ "GenSigSNA" SG_ 1033 NM_Ud_Launch "3Fh";
BA_ "GenSigSendType" SG_ 1033 NM_Ud_Launch 1;
BA_ "FlexKomSigStartValue" SG_ 1033 NM_Ud_Launch "FFFFFFFFh";
BA_ "FlexKomSigStartPos" SG_ 1033 NM_Ud_Launch 7;
BA_ "FlexKomSigName" SG_ 1033 NM_Ud_Launch "NM";
BA_ "FlexKomSigLaenge" SG_ 1033 NM_Ud_Launch 32;
BA_ "FlexKomSID" SG_ 1033 NM_Ud_Launch 472;
BA_ "FlexKomIsMotorola" SG_ 1033 NM_Ud_Launch 1;
BA_ "FlexKomComment" SG_ 1033 NM_Ud_Launch "Network management state";
BA_ "GenSigStartValue" SG_ 1050 NM_Successor 255;
BA_ "GenSigSNA" SG_ 1050 NM_Successor "FFh";
BA_ "GenSigSendType" SG_ 1050 NM_Successor 1;
BA_ "FlexKomSigStartValue" SG_ 1050 NM_Successor "FFFFFFFFh";
BA_ "FlexKomSigStartPos" SG_ 1050 NM_Successor 7;
BA_ "FlexKomSigName" SG_ 1050 NM_Successor "NM";
BA_ "FlexKomSigLaenge" SG_ 1050 NM_Successor 32;
BA_ "FlexKomSID" SG_ 1050 NM_Successor 472;
BA_ "FlexKomIsMotorola" SG_ 1050 NM_Successor 1;
BA_ "FlexKomComment" SG_ 1050 NM_Successor "Network management state";
BA_ "GenSigStartValue" SG_ 1050 NM_Sleep_Ack 1;
BA_ "GenSigSNA" SG_ 1050 NM_Sleep_Ack "1h";
BA_ "GenSigSendType" SG_ 1050 NM_Sleep_Ack 1;
BA_ "FlexKomSigStartValue" SG_ 1050 NM_Sleep_Ack "FFFFFFFFh";
BA_ "FlexKomSigStartPos" SG_ 1050 NM_Sleep_Ack 7;
BA_ "FlexKomSigName" SG_ 1050 NM_Sleep_Ack "NM";
BA_ "FlexKomSigLaenge" SG_ 1050 NM_Sleep_Ack 32;
BA_ "FlexKomSID" SG_ 1050 NM_Sleep_Ack 472;
BA_ "FlexKomIsMotorola" SG_ 1050 NM_Sleep_Ack 1;
BA_ "FlexKomComment" SG_ 1050 NM_Sleep_Ack "Network management state";
BA_ "GenSigSNA" SG_ 1050 Awake_NwSt "0h";
BA_ "GenSigSendType" SG_ 1050 Awake_NwSt 1;
BA_ "FlexKomSigStartValue" SG_ 1050 Awake_NwSt "000000h";
BA_ "FlexKomSigStartPos" SG_ 1050 Awake_NwSt 39;
BA_ "FlexKomSigName" SG_ 1050 Awake_NwSt "Awake_EPS";
BA_ "FlexKomSigLaenge" SG_ 1050 Awake_NwSt 24;
BA_ "FlexKomSID" SG_ 1050 Awake_NwSt 1274;
BA_ "FlexKomIsMotorola" SG_ 1050 Awake_NwSt 1;
BA_ "FlexKomComment" SG_ 1050 Awake_NwSt "Mode 15 of NM_Ud_Srv";
BA_ "GenSigSNA" SG_ 1050 Awake_VSS_high "0h";
BA_ "GenSigSendType" SG_ 1050 Awake_VSS_high 1;
BA_ "FlexKomSigStartValue" SG_ 1050 Awake_VSS_high "000000h";
BA_ "FlexKomSigStartPos" SG_ 1050 Awake_VSS_high 39;
BA_ "FlexKomSigName" SG_ 1050 Awake_VSS_high "Awake_EPS";
BA_ "FlexKomSigLaenge" SG_ 1050 Awake_VSS_high 24;
BA_ "FlexKomSID" SG_ 1050 Awake_VSS_high 1274;
BA_ "FlexKomIsMotorola" SG_ 1050 Awake_VSS_high 1;
BA_ "FlexKomComment" SG_ 1050 Awake_VSS_high "Mode 15 of NM_Ud_Srv";
BA_ "GenSigSNA" SG_ 1050 Awake_IgnHigh "0h";
BA_ "GenSigSendType" SG_ 1050 Awake_IgnHigh 1;
BA_ "FlexKomSigStartValue" SG_ 1050 Awake_IgnHigh "000000h";
BA_ "FlexKomSigStartPos" SG_ 1050 Awake_IgnHigh 39;
BA_ "FlexKomSigName" SG_ 1050 Awake_IgnHigh "Awake_EPS";
BA_ "FlexKomSigLaenge" SG_ 1050 Awake_IgnHigh 24;
BA_ "FlexKomSID" SG_ 1050 Awake_IgnHigh 1274;
BA_ "FlexKomIsMotorola" SG_ 1050 Awake_IgnHigh 1;
BA_ "FlexKomComment" SG_ 1050 Awake_IgnHigh "Mode 15 of NM_Ud_Srv";
BA_ "GenSigStartValue" SG_ 1050 WakeupCnt 255;
BA_ "GenSigSNA" SG_ 1050 WakeupCnt "FFh";
BA_ "GenSigSendType" SG_ 1050 WakeupCnt 1;
BA_ "FlexKomSigStartValue" SG_ 1050 WakeupCnt "FFFF00h";
BA_ "FlexKomSigStartPos" SG_ 1050 WakeupCnt 39;
BA_ "FlexKomSigName" SG_ 1050 WakeupCnt "Wakeup_EPS";
BA_ "FlexKomSigLaenge" SG_ 1050 WakeupCnt 24;
BA_ "FlexKomSID" SG_ 1050 WakeupCnt 1273;
BA_ "FlexKomIsMotorola" SG_ 1050 WakeupCnt 1;
BA_ "FlexKomComment" SG_ 1050 WakeupCnt "Mode 2 of NM_Ud_Srv";
BA_ "GenSigStartValue" SG_ 1050 Nw_Id 255;
BA_ "GenSigSNA" SG_ 1050 Nw_Id "FFh";
BA_ "GenSigSendType" SG_ 1050 Nw_Id 1;
BA_ "FlexKomSigStartValue" SG_ 1050 Nw_Id "FFh";
BA_ "FlexKomSigStartPos" SG_ 1050 Nw_Id 63;
BA_ "FlexKomSigName" SG_ 1050 Nw_Id "Nw_Id";
BA_ "FlexKomSigLaenge" SG_ 1050 Nw_Id 8;
BA_ "FlexKomSID" SG_ 1050 Nw_Id 535;
BA_ "FlexKomIsMotorola" SG_ 1050 Nw_Id 1;
BA_ "FlexKomComment" SG_ 1050 Nw_Id "Network identification no.";
BA_ "GenSigSNA" SG_ 1050 Awake_EngRPM_high "0h";
BA_ "GenSigSendType" SG_ 1050 Awake_EngRPM_high 1;
BA_ "FlexKomSigStartValue" SG_ 1050 Awake_EngRPM_high "000000h";
BA_ "FlexKomSigStartPos" SG_ 1050 Awake_EngRPM_high 39;
BA_ "FlexKomSigName" SG_ 1050 Awake_EngRPM_high "Awake_EPS";
BA_ "FlexKomSigLaenge" SG_ 1050 Awake_EngRPM_high 24;
BA_ "FlexKomSID" SG_ 1050 Awake_EngRPM_high 1274;
BA_ "FlexKomIsMotorola" SG_ 1050 Awake_EngRPM_high 1;
BA_ "FlexKomComment" SG_ 1050 Awake_EngRPM_high "Mode 15 of NM_Ud_Srv";
BA_ "GenSigStartValue" SG_ 1050 NM_Sleep_Ind 1;
BA_ "GenSigSNA" SG_ 1050 NM_Sleep_Ind "1h";
BA_ "GenSigSendType" SG_ 1050 NM_Sleep_Ind 1;
BA_ "FlexKomSigStartValue" SG_ 1050 NM_Sleep_Ind "FFFFFFFFh";
BA_ "FlexKomSigStartPos" SG_ 1050 NM_Sleep_Ind 7;
BA_ "FlexKomSigName" SG_ 1050 NM_Sleep_Ind "NM";
BA_ "FlexKomSigLaenge" SG_ 1050 NM_Sleep_Ind 32;
BA_ "FlexKomSID" SG_ 1050 NM_Sleep_Ind 472;
BA_ "FlexKomIsMotorola" SG_ 1050 NM_Sleep_Ind 1;
BA_ "FlexKomComment" SG_ 1050 NM_Sleep_Ind "Network management state";
BA_ "GenSigStartValue" SG_ 1050 NM_Ud_Srv 255;
BA_ "GenSigSNA" SG_ 1050 NM_Ud_Srv "FFh";
BA_ "GenSigSendType" SG_ 1050 NM_Ud_Srv 1;
BA_ "FlexKomSigStartValue" SG_ 1050 NM_Ud_Srv "FFFFFFFFh";
BA_ "FlexKomSigStartPos" SG_ 1050 NM_Ud_Srv 7;
BA_ "FlexKomSigName" SG_ 1050 NM_Ud_Srv "NM";
BA_ "FlexKomSigLaenge" SG_ 1050 NM_Ud_Srv 32;
BA_ "FlexKomSID" SG_ 1050 NM_Ud_Srv 472;
BA_ "FlexKomIsMotorola" SG_ 1050 NM_Ud_Srv 1;
BA_ "FlexKomComment" SG_ 1050 NM_Ud_Srv "Network management state";
BA_ "GenSigStartValue" SG_ 1050 NM_Ud_Launch 63;
BA_ "GenSigSNA" SG_ 1050 NM_Ud_Launch "3Fh";
BA_ "GenSigSendType" SG_ 1050 NM_Ud_Launch 1;
BA_ "FlexKomSigStartValue" SG_ 1050 NM_Ud_Launch "FFFFFFFFh";
BA_ "FlexKomSigStartPos" SG_ 1050 NM_Ud_Launch 7;
BA_ "FlexKomSigName" SG_ 1050 NM_Ud_Launch "NM";
BA_ "FlexKomSigLaenge" SG_ 1050 NM_Ud_Launch 32;
BA_ "FlexKomSID" SG_ 1050 NM_Ud_Launch 472;
BA_ "FlexKomIsMotorola" SG_ 1050 NM_Ud_Launch 1;
BA_ "FlexKomComment" SG_ 1050 NM_Ud_Launch "Network management state";
BA_ "GenSigStartValue" SG_ 1050 WakeupRsn_EPS 255;
BA_ "GenSigSNA" SG_ 1050 WakeupRsn_EPS "FFh";
BA_ "GenSigSendType" SG_ 1050 WakeupRsn_EPS 1;
BA_ "FlexKomSigStartValue" SG_ 1050 WakeupRsn_EPS "FFFF00h";
BA_ "FlexKomSigStartPos" SG_ 1050 WakeupRsn_EPS 39;
BA_ "FlexKomSigName" SG_ 1050 WakeupRsn_EPS "Wakeup_EPS";
BA_ "FlexKomSigLaenge" SG_ 1050 WakeupRsn_EPS 24;
BA_ "FlexKomSID" SG_ 1050 WakeupRsn_EPS 1273;
BA_ "FlexKomIsMotorola" SG_ 1050 WakeupRsn_EPS 1;
BA_ "FlexKomComment" SG_ 1050 WakeupRsn_EPS "Mode 2 of NM_Ud_Srv";
BA_ "GenSigSNA" SG_ 1050 Awake_Diag_Actv "0h";
BA_ "GenSigSendType" SG_ 1050 Awake_Diag_Actv 1;
BA_ "FlexKomSigStartValue" SG_ 1050 Awake_Diag_Actv "000000h";
BA_ "FlexKomSigStartPos" SG_ 1050 Awake_Diag_Actv 39;
BA_ "FlexKomSigName" SG_ 1050 Awake_Diag_Actv "Awake_EPS";
BA_ "FlexKomSigLaenge" SG_ 1050 Awake_Diag_Actv 24;
BA_ "FlexKomSID" SG_ 1050 Awake_Diag_Actv 1274;
BA_ "FlexKomIsMotorola" SG_ 1050 Awake_Diag_Actv 1;
BA_ "FlexKomComment" SG_ 1050 Awake_Diag_Actv "Mode 15 of NM_Ud_Srv";
BA_ "GenSigSNA" SG_ 1050 Awake_Rampout "0h";
BA_ "GenSigSendType" SG_ 1050 Awake_Rampout 1;
BA_ "FlexKomSigStartValue" SG_ 1050 Awake_Rampout "000000h";
BA_ "FlexKomSigStartPos" SG_ 1050 Awake_Rampout 39;
BA_ "FlexKomSigName" SG_ 1050 Awake_Rampout "Awake_EPS";
BA_ "FlexKomSigLaenge" SG_ 1050 Awake_Rampout 24;
BA_ "FlexKomSID" SG_ 1050 Awake_Rampout 1274;
BA_ "FlexKomIsMotorola" SG_ 1050 Awake_Rampout 1;
BA_ "FlexKomComment" SG_ 1050 Awake_Rampout "Mode 15 of NM_Ud_Srv";
BA_ "GenSigStartValue" SG_ 1050 NM_Mode 255;
BA_ "GenSigSNA" SG_ 1050 NM_Mode "FFh";
BA_ "GenSigSendType" SG_ 1050 NM_Mode 1;
BA_ "FlexKomSigStartValue" SG_ 1050 NM_Mode "FFFFFFFFh";
BA_ "FlexKomSigStartPos" SG_ 1050 NM_Mode 7;
BA_ "FlexKomSigName" SG_ 1050 NM_Mode "NM";
BA_ "FlexKomSigLaenge" SG_ 1050 NM_Mode 32;
BA_ "FlexKomSID" SG_ 1050 NM_Mode 472;
BA_ "FlexKomIsMotorola" SG_ 1050 NM_Mode 1;
BA_ "FlexKomComment" SG_ 1050 NM_Mode "Network management state";
BA_ "GenSigStartValue" SG_ 1059 NM_Sleep_Ind 1;
BA_ "GenSigSNA" SG_ 1059 NM_Sleep_Ind "1h";
BA_ "GenSigSendType" SG_ 1059 NM_Sleep_Ind 1;
BA_ "FlexKomSigStartValue" SG_ 1059 NM_Sleep_Ind "FFFFFFFFh";
BA_ "FlexKomSigStartPos" SG_ 1059 NM_Sleep_Ind 7;
BA_ "FlexKomSigName" SG_ 1059 NM_Sleep_Ind "NM";
BA_ "FlexKomSigLaenge" SG_ 1059 NM_Sleep_Ind 32;
BA_ "FlexKomSID" SG_ 1059 NM_Sleep_Ind 472;
BA_ "FlexKomIsMotorola" SG_ 1059 NM_Sleep_Ind 1;
BA_ "FlexKomComment" SG_ 1059 NM_Sleep_Ind "Network management state";
BA_ "GenSigStartValue" SG_ 1059 WakeupRsn_SCCM 255;
BA_ "GenSigSNA" SG_ 1059 WakeupRsn_SCCM "FFh";
BA_ "GenSigSendType" SG_ 1059 WakeupRsn_SCCM 1;
BA_ "FlexKomSigStartValue" SG_ 1059 WakeupRsn_SCCM "FFFF00h";
BA_ "FlexKomSigStartPos" SG_ 1059 WakeupRsn_SCCM 39;
BA_ "FlexKomSigName" SG_ 1059 WakeupRsn_SCCM "Wakeup_SCCM_Pkt";
BA_ "FlexKomSigLaenge" SG_ 1059 WakeupRsn_SCCM 24;
BA_ "FlexKomSID" SG_ 1059 WakeupRsn_SCCM 494;
BA_ "FlexKomIsMotorola" SG_ 1059 WakeupRsn_SCCM 1;
BA_ "FlexKomComment" SG_ 1059 WakeupRsn_SCCM "Mode 2 of NM_Ud_Srv";
BA_ "GenSigSNA" SG_ 1059 Awake_StwSw_Actv "0h";
BA_ "GenSigSendType" SG_ 1059 Awake_StwSw_Actv 1;
BA_ "FlexKomSigStartValue" SG_ 1059 Awake_StwSw_Actv "000000h";
BA_ "FlexKomSigStartPos" SG_ 1059 Awake_StwSw_Actv 39;
BA_ "FlexKomSigName" SG_ 1059 Awake_StwSw_Actv "Awake_SCCM_Pkt";
BA_ "FlexKomSigLaenge" SG_ 1059 Awake_StwSw_Actv 24;
BA_ "FlexKomSID" SG_ 1059 Awake_StwSw_Actv 524;
BA_ "FlexKomIsMotorola" SG_ 1059 Awake_StwSw_Actv 1;
BA_ "FlexKomComment" SG_ 1059 Awake_StwSw_Actv "Mode 15 of NM_Ud_Srv";
BA_ "GenSigSNA" SG_ 1059 Awake_EEPROM "0h";
BA_ "GenSigSendType" SG_ 1059 Awake_EEPROM 1;
BA_ "FlexKomSigStartValue" SG_ 1059 Awake_EEPROM "000000h";
BA_ "FlexKomSigStartPos" SG_ 1059 Awake_EEPROM 39;
BA_ "FlexKomSigName" SG_ 1059 Awake_EEPROM "Awake_SCCM_Pkt";
BA_ "FlexKomSigLaenge" SG_ 1059 Awake_EEPROM 24;
BA_ "FlexKomSID" SG_ 1059 Awake_EEPROM 524;
BA_ "FlexKomIsMotorola" SG_ 1059 Awake_EEPROM 1;
BA_ "FlexKomComment" SG_ 1059 Awake_EEPROM "Mode 15 of NM_Ud_Srv";
BA_ "GenSigSNA" SG_ 1059 Awake_FTP_Psd "0h";
BA_ "GenSigSendType" SG_ 1059 Awake_FTP_Psd 1;
BA_ "FlexKomSigStartValue" SG_ 1059 Awake_FTP_Psd "000000h";
BA_ "FlexKomSigStartPos" SG_ 1059 Awake_FTP_Psd 39;
BA_ "FlexKomSigName" SG_ 1059 Awake_FTP_Psd "Awake_SCCM_Pkt";
BA_ "FlexKomSigLaenge" SG_ 1059 Awake_FTP_Psd 24;
BA_ "FlexKomSID" SG_ 1059 Awake_FTP_Psd 524;
BA_ "FlexKomIsMotorola" SG_ 1059 Awake_FTP_Psd 1;
BA_ "FlexKomComment" SG_ 1059 Awake_FTP_Psd "Mode 15 of NM_Ud_Srv";
BA_ "GenSigSNA" SG_ 1059 Awake_tilt_tel_Psd "0h";
BA_ "GenSigSendType" SG_ 1059 Awake_tilt_tel_Psd 1;
BA_ "FlexKomSigStartValue" SG_ 1059 Awake_tilt_tel_Psd "000000h";
BA_ "FlexKomSigStartPos" SG_ 1059 Awake_tilt_tel_Psd 39;
BA_ "FlexKomSigName" SG_ 1059 Awake_tilt_tel_Psd "Awake_SCCM_Pkt";
BA_ "FlexKomSigLaenge" SG_ 1059 Awake_tilt_tel_Psd 24;
BA_ "FlexKomSID" SG_ 1059 Awake_tilt_tel_Psd 524;
BA_ "FlexKomIsMotorola" SG_ 1059 Awake_tilt_tel_Psd 1;
BA_ "FlexKomComment" SG_ 1059 Awake_tilt_tel_Psd "Mode 15 of NM_Ud_Srv";
BA_ "GenSigSNA" SG_ 1059 Awake_HrnSwt_Actv "0h";
BA_ "GenSigSendType" SG_ 1059 Awake_HrnSwt_Actv 1;
BA_ "FlexKomSigStartValue" SG_ 1059 Awake_HrnSwt_Actv "000000h";
BA_ "FlexKomSigStartPos" SG_ 1059 Awake_HrnSwt_Actv 39;
BA_ "FlexKomSigName" SG_ 1059 Awake_HrnSwt_Actv "Awake_SCCM_Pkt";
BA_ "FlexKomSigLaenge" SG_ 1059 Awake_HrnSwt_Actv 24;
BA_ "FlexKomSID" SG_ 1059 Awake_HrnSwt_Actv 524;
BA_ "FlexKomIsMotorola" SG_ 1059 Awake_HrnSwt_Actv 1;
BA_ "FlexKomComment" SG_ 1059 Awake_HrnSwt_Actv "Mode 15 of NM_Ud_Srv";
BA_ "GenSigStartValue" SG_ 1059 WakeupCnt 255;
BA_ "GenSigSNA" SG_ 1059 WakeupCnt "FFh";
BA_ "GenSigSendType" SG_ 1059 WakeupCnt 1;
BA_ "FlexKomSigStartValue" SG_ 1059 WakeupCnt "FFFF00h";
BA_ "FlexKomSigStartPos" SG_ 1059 WakeupCnt 39;
BA_ "FlexKomSigName" SG_ 1059 WakeupCnt "Wakeup_SCCM_Pkt";
BA_ "FlexKomSigLaenge" SG_ 1059 WakeupCnt 24;
BA_ "FlexKomSID" SG_ 1059 WakeupCnt 494;
BA_ "FlexKomIsMotorola" SG_ 1059 WakeupCnt 1;
BA_ "FlexKomComment" SG_ 1059 WakeupCnt "Mode 2 of NM_Ud_Srv";
BA_ "GenSigStartValue" SG_ 1059 Nw_Id 255;
BA_ "GenSigSNA" SG_ 1059 Nw_Id "FFh";
BA_ "GenSigSendType" SG_ 1059 Nw_Id 1;
BA_ "FlexKomSigStartValue" SG_ 1059 Nw_Id "FFh";
BA_ "FlexKomSigStartPos" SG_ 1059 Nw_Id 63;
BA_ "FlexKomSigName" SG_ 1059 Nw_Id "Nw_Id";
BA_ "FlexKomSigLaenge" SG_ 1059 Nw_Id 8;
BA_ "FlexKomSID" SG_ 1059 Nw_Id 535;
BA_ "FlexKomIsMotorola" SG_ 1059 Nw_Id 1;
BA_ "FlexKomComment" SG_ 1059 Nw_Id "Network identification no.";
BA_ "GenSigSNA" SG_ 1059 Awake_Diag_Actv "0h";
BA_ "GenSigSendType" SG_ 1059 Awake_Diag_Actv 1;
BA_ "FlexKomSigStartValue" SG_ 1059 Awake_Diag_Actv "000000h";
BA_ "FlexKomSigStartPos" SG_ 1059 Awake_Diag_Actv 39;
BA_ "FlexKomSigName" SG_ 1059 Awake_Diag_Actv "Awake_SCCM_Pkt";
BA_ "FlexKomSigLaenge" SG_ 1059 Awake_Diag_Actv 24;
BA_ "FlexKomSID" SG_ 1059 Awake_Diag_Actv 524;
BA_ "FlexKomIsMotorola" SG_ 1059 Awake_Diag_Actv 1;
BA_ "FlexKomComment" SG_ 1059 Awake_Diag_Actv "Mode 15 of NM_Ud_Srv";
BA_ "GenSigSNA" SG_ 1059 Awake_Ignition_On "0h";
BA_ "GenSigSendType" SG_ 1059 Awake_Ignition_On 1;
BA_ "FlexKomSigStartValue" SG_ 1059 Awake_Ignition_On "000000h";
BA_ "FlexKomSigStartPos" SG_ 1059 Awake_Ignition_On 39;
BA_ "FlexKomSigName" SG_ 1059 Awake_Ignition_On "Awake_SCCM_Pkt";
BA_ "FlexKomSigLaenge" SG_ 1059 Awake_Ignition_On 24;
BA_ "FlexKomSID" SG_ 1059 Awake_Ignition_On 524;
BA_ "FlexKomIsMotorola" SG_ 1059 Awake_Ignition_On 1;
BA_ "FlexKomComment" SG_ 1059 Awake_Ignition_On "Mode 15 of NM_Ud_Srv";
BA_ "GenSigStartValue" SG_ 1059 NM_Ud_Srv 255;
BA_ "GenSigSNA" SG_ 1059 NM_Ud_Srv "FFh";
BA_ "GenSigSendType" SG_ 1059 NM_Ud_Srv 1;
BA_ "FlexKomSigStartValue" SG_ 1059 NM_Ud_Srv "FFFFFFFFh";
BA_ "FlexKomSigStartPos" SG_ 1059 NM_Ud_Srv 7;
BA_ "FlexKomSigName" SG_ 1059 NM_Ud_Srv "NM";
BA_ "FlexKomSigLaenge" SG_ 1059 NM_Ud_Srv 32;
BA_ "FlexKomSID" SG_ 1059 NM_Ud_Srv 472;
BA_ "FlexKomIsMotorola" SG_ 1059 NM_Ud_Srv 1;
BA_ "FlexKomComment" SG_ 1059 NM_Ud_Srv "Network management state";
BA_ "GenSigSNA" SG_ 1059 Awake_NwSt "0h";
BA_ "GenSigSendType" SG_ 1059 Awake_NwSt 1;
BA_ "FlexKomSigStartValue" SG_ 1059 Awake_NwSt "000000h";
BA_ "FlexKomSigStartPos" SG_ 1059 Awake_NwSt 39;
BA_ "FlexKomSigName" SG_ 1059 Awake_NwSt "Awake_SCCM_Pkt";
BA_ "FlexKomSigLaenge" SG_ 1059 Awake_NwSt 24;
BA_ "FlexKomSID" SG_ 1059 Awake_NwSt 524;
BA_ "FlexKomIsMotorola" SG_ 1059 Awake_NwSt 1;
BA_ "FlexKomComment" SG_ 1059 Awake_NwSt "Mode 15 of NM_Ud_Srv";
BA_ "GenSigStartValue" SG_ 1059 NM_Mode 255;
BA_ "GenSigSNA" SG_ 1059 NM_Mode "FFh";
BA_ "GenSigSendType" SG_ 1059 NM_Mode 1;
BA_ "FlexKomSigStartValue" SG_ 1059 NM_Mode "FFFFFFFFh";
BA_ "FlexKomSigStartPos" SG_ 1059 NM_Mode 7;
BA_ "FlexKomSigName" SG_ 1059 NM_Mode "NM";
BA_ "FlexKomSigLaenge" SG_ 1059 NM_Mode 32;
BA_ "FlexKomSID" SG_ 1059 NM_Mode 472;
BA_ "FlexKomIsMotorola" SG_ 1059 NM_Mode 1;
BA_ "FlexKomComment" SG_ 1059 NM_Mode "Network management state";
BA_ "GenSigStartValue" SG_ 1059 NM_Successor 255;
BA_ "GenSigSNA" SG_ 1059 NM_Successor "FFh";
BA_ "GenSigSendType" SG_ 1059 NM_Successor 1;
BA_ "FlexKomSigStartValue" SG_ 1059 NM_Successor "FFFFFFFFh";
BA_ "FlexKomSigStartPos" SG_ 1059 NM_Successor 7;
BA_ "FlexKomSigName" SG_ 1059 NM_Successor "NM";
BA_ "FlexKomSigLaenge" SG_ 1059 NM_Successor 32;
BA_ "FlexKomSID" SG_ 1059 NM_Successor 472;
BA_ "FlexKomIsMotorola" SG_ 1059 NM_Successor 1;
BA_ "FlexKomComment" SG_ 1059 NM_Successor "Network management state";
BA_ "GenSigStartValue" SG_ 1059 NM_Ud_Launch 63;
BA_ "GenSigSNA" SG_ 1059 NM_Ud_Launch "3Fh";
BA_ "GenSigSendType" SG_ 1059 NM_Ud_Launch 1;
BA_ "FlexKomSigStartValue" SG_ 1059 NM_Ud_Launch "FFFFFFFFh";
BA_ "FlexKomSigStartPos" SG_ 1059 NM_Ud_Launch 7;
BA_ "FlexKomSigName" SG_ 1059 NM_Ud_Launch "NM";
BA_ "FlexKomSigLaenge" SG_ 1059 NM_Ud_Launch 32;
BA_ "FlexKomSID" SG_ 1059 NM_Ud_Launch 472;
BA_ "FlexKomIsMotorola" SG_ 1059 NM_Ud_Launch 1;
BA_ "FlexKomComment" SG_ 1059 NM_Ud_Launch "Network management state";
BA_ "GenSigStartValue" SG_ 1059 NM_Sleep_Ack 1;
BA_ "GenSigSNA" SG_ 1059 NM_Sleep_Ack "1h";
BA_ "GenSigSendType" SG_ 1059 NM_Sleep_Ack 1;
BA_ "FlexKomSigStartValue" SG_ 1059 NM_Sleep_Ack "FFFFFFFFh";
BA_ "FlexKomSigStartPos" SG_ 1059 NM_Sleep_Ack 7;
BA_ "FlexKomSigName" SG_ 1059 NM_Sleep_Ack "NM";
BA_ "FlexKomSigLaenge" SG_ 1059 NM_Sleep_Ack 32;
BA_ "FlexKomSID" SG_ 1059 NM_Sleep_Ack 472;
BA_ "FlexKomIsMotorola" SG_ 1059 NM_Sleep_Ack 1;
BA_ "FlexKomComment" SG_ 1059 NM_Sleep_Ack "Network management state";
BA_ "GenSigSNA" SG_ 1089 DG_RQ_GLOBAL_UDS "0h";
BA_ "FlexKomSigStartValue" SG_ 1089 DG_RQ_GLOBAL_UDS "0000000000000000h";
BA_ "FlexKomSigStartPos" SG_ 1089 DG_RQ_GLOBAL_UDS 7;
BA_ "FlexKomSigName" SG_ 1089 DG_RQ_GLOBAL_UDS "DG_RQ_GLOBAL_UDS";
BA_ "FlexKomSigLaenge" SG_ 1089 DG_RQ_GLOBAL_UDS 64;
BA_ "FlexKomSID" SG_ 1089 DG_RQ_GLOBAL_UDS 393;
BA_ "FlexKomIsMotorola" SG_ 1089 DG_RQ_GLOBAL_UDS 1;
BA_ "FlexKomComment" SG_ 1089 DG_RQ_GLOBAL_UDS "Diagnostic-Request";
VAL_ 1005 VC_BU_PwrIvtrTyp 0 "NoPwrIvtr" 1 "MtrySw" 2 "LchSw" ;
VAL_ 1005 VC_BU_MaseratiMd 0 "NORMAL" 1 "GTS" 2 "RACE" 3 "SNA" ;
VAL_ 1005 VC_BU_MaxLdPressFtTr 255 "SNA" ;
VAL_ 1005 VC_BU_LgtLdPressRrTr 255 "SNA" ;
VAL_ 1005 VC_BU_LgtLdPressFtTr 255 "SNA" ;
VAL_ 1005 VC_BU_ShftInd_Prsnt 0 "NONE" 1 "GSI" 2 "PSI" 3 "PGSI" ;
VAL_ 1005 VC_BU_MaxLdPressRrTr 255 "SNA" ;
VAL_ 1005 VC_BU_VehCfg2_Stat 0 "NA" 1 "PROGAMMED" 2 "NA1" 3 "SNA" ;
VAL_ 1005 VC_BU_SpecialPKG_IC 0 "NONE" 1 "PKG_70JP" 2 "PKG_300S" 3 "PKG_BEATS" 4 "PKG_SUPERBEE" 5 "MOPAR" 6 "Hellcat" 7 "Shaker" 8 "Scat" 9 "ADR" 10 "Scat_Drag" 11 "High_Output" 12 "Hellcat_HO" 16 "LARAMIE" 17 "BIGHORN" 18 "LONGHORN" 19 "LONESTAR" 20 "LIMITED" 21 "MOSSY_OAK" 22 "ORT" 23 "POWERWAGON" 24 "HD_DX" 25 "SPORT" 26 "PWGN_Laramie" 27 "RAM_1500" 28 "PWGN_GOODYEAR" 29 "LONGHORN_BLACK" 30 "LONGHORN_BROWN" 31 "RAM_2500" 32 "RAM_3500" 33 "RAM_4500" 34 "RAM_5500" 35 "RAM_TRX21" 36 "VOYAGER" 37 "PACIFICA" 38 "GRAND_CARAVAN" 39 "50th_Anniversary" 40 "80th_Anniversary" 41 "J9_Splash_Screen" 42 "Hellcat_LA" 100 "WRANGLER_SPORT" 101 "WRANGLER_SAHARA" 102 "WRANGLER_RUBICON" 103 "JEEP_SPORT" 104 "JEEP_SPORT_X" 105 "JEEP_RUBICON" 106 "JEEP_PRO_FIGHTER" 107 "10th_Anniversary" 108 "Limited_10th_Anniversary" 109 "TRX_Ignition" 110 "RED" 150 "TRAILHAWK_SUPERCHARGED" 151 "TRX_Final_Edition" 246 "DODGE_100" 247 "VARVATOS" 255 "SNA" ;
VAL_ 1006 VC_BU_VEH_BRAND 1 "CHRYSLER" 2 "DODGE" 3 "JEEP" 4 "MERCEDES_BENZ" 5 "MITSUBISHI" 6 "VOLKSWAGEN" 7 "FREIGHTLINER" 8 "ALPHA" 9 "FIAT" 10 "LANCIA" 11 "MASERATI" 12 "RAM" 15 "SNA" ;
VAL_ 1006 VC_BU_ChassisType 127 "SNA" ;
VAL_ 1006 VC_BU_VehCfg3_Stat 0 "NA" 1 "PROGAMMED" 2 "NA1" 3 "SNA" ;
VAL_ 1006 VC_BU_WHL_BASE 0 "SHORT" 1 "LONG" 2 "XLONG" 3 "SNA" ;
VAL_ 1006 VC_BU_HVAC_Config 0 "1_ZN_MTC" 1 "1_ZN_MTC_p_RR" 2 "1_ZN_ATC" 3 "2_ZN_MTC" 4 "2_ZN_ATC" 5 "2_ZN_ATC_p_RR" 6 "2_ZN_MTC_p_RR" 15 "SNA" ;
VAL_ 1006 VC_BU_Liftgate_Trunk 0 "TRUNK" 1 "PLG" 2 "MANUAL_LG" 3 "SNA" ;
VAL_ 1006 VC_BU_TcaseTyp 0 "NOT_PRSNT" 1 "TCASE_143_144" 2 "BW4445_46_48_WS" 3 "Tcase_253_1522" 4 "Tcase_BW4444" 5 "Tcase_BW4446" 6 "Tcase_MPT3025C" 7 "Tcase_241_MPT1222C" 8 "BW4447_WOS" 9 "Tcase_243" 10 "BW4447_49_WS" 11 "Tcase_273" 12 "Tcase_MAS_ATC" 13 "Tcase_BW4440" 14 "Tcase_156" 15 "Tcase_256_3022" ;
VAL_ 1006 VC_BU_ELV_PRSNT 0 "SNA" ;
VAL_ 1006 VC_BU_FUEL_CAP 255 "SNA" ;
VAL_ 1006 VC_BU_WIN_EXPR_FEAT 0 "WIN_EXPR_DRV" 1 "WIN_EXPR_FT" 2 "WIN_EXPR_ALL" 3 "WIN_EXPR_NN" ;
VAL_ 1007 VC_BU_TCASE_HI_RATIO 16383 "SNA" ;
VAL_ 1007 VC_BU_VehCfg4_Stat 0 "NA" 1 "PROGAMMED" 2 "NA1" 3 "SNA" ;
VAL_ 1007 VC_BU_AXLE_RATIO 65535 "SNA" ;
VAL_ 1007 VC_BU_TIRE_CIRCUMF 65535 "SNA" ;
VAL_ 1007 VC_BU_TCASE_LO_RATIO 65535 "SNA" ;
VAL_ 1008 EC_ECUCfg1_Stat 0 "NA" 1 "PROGAMMED" 2 "REQUEST_DATA" 3 "SNA" ;
VAL_ 1009 EC_ECUCfg2_Stat 0 "NA" 1 "PROGAMMED" 2 "REQUEST_DATA" 3 "SNA" ;
VAL_ 1010 EC_ECUCfg3_Stat 0 "NA" 1 "PROGAMMED" 2 "REQUEST_DATA" 3 "SNA" ;
VAL_ 1011 EC_ECUCfg4_Stat 0 "NA" 1 "PROGAMMED" 2 "REQUEST_DATA" 3 "SNA" ;
VAL_ 1012 EC_ECUCfg5_Stat 0 "NA" 1 "PROGAMMED" 2 "REQUEST_DATA" 3 "SNA" ;
VAL_ 1013 EC_ECUCfg6_Stat 0 "NA" 1 "PROGAMMED" 2 "REQUEST_DATA" 3 "SNA" ;
VAL_ 1014 EC_ECUCfg7_Stat 0 "NA" 1 "PROGAMMED" 2 "REQUEST_DATA" 3 "SNA" ;
VAL_ 1015 EC_ECUCfg8_Stat 0 "NA" 1 "PROGAMMED" 2 "REQUEST_DATA" 3 "SNA" ;
VAL_ 1016 EC_BU_ECUCfg1_Stat 0 "NA" 1 "PROGAMMED" 2 "NA1" 3 "SNA" ;
VAL_ 1017 EC_BU_ECUCfg2_Stat 0 "NA" 1 "PROGAMMED" 2 "NA1" 3 "SNA" ;
VAL_ 1018 EC_BU_ECUCfg3_Stat 0 "NA" 1 "PROGAMMED" 2 "NA1" 3 "SNA" ;
VAL_ 1019 EC_BU_ECUCfg4_Stat 0 "NA" 1 "PROGAMMED" 2 "NA1" 3 "SNA" ;
VAL_ 1020 EC_BU_ECUCfg5_Stat 0 "NA" 1 "PROGAMMED" 2 "NA1" 3 "SNA" ;
VAL_ 1021 EC_BU_ECUCfg6_Stat 0 "NA" 1 "PROGAMMED" 2 "NA1" 3 "SNA" ;
VAL_ 1022 EC_BU_ECUCfg7_Stat 0 "NA" 1 "PROGAMMED" 2 "NA1" 3 "SNA" ;
VAL_ 1023 EC_BU_ECUCfg8_Stat 0 "NA" 1 "PROGAMMED" 2 "NA1" 3 "SNA" ;
VAL_ 1024 NM_Mode 252 "LHOM" 253 "RING" 254 "ALIVE" 255 "SNA" ;
VAL_ 1024 WakeupCnt 255 "SNA" ;
VAL_ 1024 Nw_Id 0 "POWERTRAIN" 1 "BODY" 2 "AUDIO_TELE" 255 "SNA" ;
VAL_ 1024 NM_Ud_Srv 2 "WAKEUP_SA" 15 "AWAKE_BC" 255 "NO_USER_DATA" ;
VAL_ 1024 WakeupRsn_RF_HUB 0 "NETWORK" 1 "SSB" 2 "AP1" 3 "AP2" 4 "AP3" 5 "AP4" 6 "AP5" 7 "RF_INPUT" 8 "RESET" 9 "TIMER" 10 "CLUTCH" 255 "SNA" ;
VAL_ 1024 NM_Successor 255 "SNA" ;
VAL_ 1024 NM_Ud_Launch 4 "BROADCAST" 63 "SNA" ;
VAL_ 1025 NM_Ud_Srv 2 "WAKEUP_SA" 15 "AWAKE_BC" 255 "NO_USER_DATA" ;
VAL_ 1025 WakeupRsn_CBC 0 "NETWORK" 1 "CAN_C" 2 "CAN_I" 3 "LIN_ONE" 4 "LIN_TWO" 5 "LIN_THREE" 6 "DRV_AJAR" 7 "PSG_AJAR" 8 "L_R_AJAR" 9 "R_R_AJAR" 10 "TLG_AJAR" 11 "FG_AJAR" 12 "HOOD_AJAR" 13 "HRD_TOP_STEALTH" 14 "TK_FG_SW" 15 "DRV_LK_SW" 16 "PASS_LK_SW" 17 "HAZARD_SW" 18 "SS_SW" 19 "BRK_SW" 20 "HL_SW" 21 "PD_SW" 22 "CARGO_SW" 23 "CON_LAMP_LD" 24 "REFUEL" 25 "ELCM" 255 "SNA" ;
VAL_ 1025 NM_Mode 252 "LHOM" 253 "RING" 254 "ALIVE" 255 "SNA" ;
VAL_ 1025 NM_Successor 255 "SNA" ;
VAL_ 1025 NM_Ud_Launch 4 "BROADCAST" 63 "SNA" ;
VAL_ 1025 WakeupCnt 255 "SNA" ;
VAL_ 1025 Nw_Id 0 "POWERTRAIN" 1 "BODY" 2 "AUDIO_TELE" 255 "SNA" ;
VAL_ 1026 NM_Ud_Launch 4 "BROADCAST" 63 "SNA" ;
VAL_ 1026 WakeupRsn_IC 0 "NETWORK" 1 "IGN" 255 "SNA" ;
VAL_ 1026 NM_Ud_Srv 2 "WAKEUP_SA" 15 "AWAKE_BC" 255 "NO_USER_DATA" ;
VAL_ 1026 WakeupCnt 255 "SNA" ;
VAL_ 1026 Nw_Id 0 "POWERTRAIN" 1 "BODY" 2 "AUDIO_TELE" 255 "SNA" ;
VAL_ 1026 NM_Mode 252 "LHOM" 253 "RING" 254 "ALIVE" 255 "SNA" ;
VAL_ 1026 NM_Successor 255 "SNA" ;
VAL_ 1031 NM_Mode 252 "LHOM" 253 "RING" 254 "ALIVE" 255 "SNA" ;
VAL_ 1031 WakeupCnt 255 "SNA" ;
VAL_ 1031 Nw_Id 0 "POWERTRAIN" 1 "BODY" 2 "AUDIO_TELE" 255 "SNA" ;
VAL_ 1031 NM_Ud_Srv 2 "WAKEUP_SA" 15 "AWAKE_BC" 255 "NO_USER_DATA" ;
VAL_ 1031 WakeupRsn_ESC 0 "NETWORK" 1 "BP" 2 "VEH_SPD" 3 "RA_RECLAMP" 4 "T_RECLAMP" 5 "SWU" 6 "DIAG" 7 "IGN" 255 "SNA" ;
VAL_ 1031 NM_Successor 255 "SNA" ;
VAL_ 1031 NM_Ud_Launch 4 "BROADCAST" 63 "SNA" ;
VAL_ 1032 WakeupCnt 255 "SNA" ;
VAL_ 1032 Nw_Id 0 "POWERTRAIN" 1 "BODY" 2 "AUDIO_TELE" 255 "SNA" ;
VAL_ 1032 NM_Mode 252 "LHOM" 253 "RING" 254 "ALIVE" 255 "SNA" ;
VAL_ 1032 NM_Successor 255 "SNA" ;
VAL_ 1032 NM_Ud_Launch 4 "BROADCAST" 63 "SNA" ;
VAL_ 1032 NM_Ud_Srv 2 "WAKEUP_SA" 15 "AWAKE_BC" 255 "NO_USER_DATA" ;
VAL_ 1032 WakeupRsn_ESL 0 "NETWORK" 255 "SNA" ;
VAL_ 1033 Nw_Id 0 "POWERTRAIN" 1 "BODY" 2 "AUDIO_TELE" 255 "SNA" ;
VAL_ 1033 NM_Ud_Srv 2 "WAKEUP_SA" 15 "AWAKE_BC" 255 "NO_USER_DATA" ;
VAL_ 1033 WakeupRsn_SBWM 0 "NETWORK" 1 "UNLK_R_S" 255 "SNA" ;
VAL_ 1033 WakeupCnt 255 "SNA" ;
VAL_ 1033 NM_Mode 252 "LHOM" 253 "RING" 254 "ALIVE" 255 "SNA" ;
VAL_ 1033 NM_Successor 255 "SNA" ;
VAL_ 1033 NM_Ud_Launch 4 "BROADCAST" 63 "SNA" ;
VAL_ 1050 NM_Successor 255 "SNA" ;
VAL_ 1050 WakeupCnt 255 "SNA" ;
VAL_ 1050 Nw_Id 0 "POWERTRAIN" 1 "BODY" 2 "AUDIO_TELE" 255 "SNA" ;
VAL_ 1050 NM_Ud_Srv 2 "WAKEUP_SA" 15 "AWAKE_BC" 255 "NO_USER_DATA" ;
VAL_ 1050 NM_Ud_Launch 4 "BROADCAST" 63 "SNA" ;
VAL_ 1050 WakeupRsn_EPS 0 "NETWORK" 1 "IGN" 255 "SNA" ;
VAL_ 1050 NM_Mode 252 "LHOM" 253 "RING" 254 "ALIVE" 255 "SNA" ;
VAL_ 1059 WakeupRsn_SCCM 0 "NETWORK" 71 "TILT" 72 "FP_LVR" 73 "HRN_SW" 76 "STW_SW" 255 "SNA" ;
VAL_ 1059 WakeupCnt 255 "SNA" ;
VAL_ 1059 Nw_Id 0 "POWERTRAIN" 1 "BODY" 2 "AUDIO_TELE" 255 "SNA" ;
VAL_ 1059 NM_Ud_Srv 2 "WAKEUP_SA" 15 "AWAKE_BC" 255 "NO_USER_DATA" ;
VAL_ 1059 NM_Mode 252 "LHOM" 253 "RING" 254 "ALIVE" 255 "SNA" ;
VAL_ 1059 NM_Successor 255 "SNA" ;
VAL_ 1059 NM_Ud_Launch 4 "BROADCAST" 63 "SNA" ;
